VERSION "HNPBNYYYYYYYYYYYYYYYYYYYYYYYYYYYNNNNNNNNNN/4/%%/4/'%**4NNN///"

NS_ :

BS_:

BU_: ADL Aux_Device CANLogger CTU Central CentralMulti OffboardUDS Predecessor_Node RDC Radar SensorCANopen Simulator TEPM TIM TPMS iTEPM

BO_ 2566805936 ASC3_Tx_4 :8 CentralMulti
 SG_ VehicleLevelFrontLeft : 0|16@1+ (0.1,-3200) [0|65535] "mm" Vector__XXX
 SG_ VehicleLevelFrontRight : 16|16@1+ (0.1,-3200) [0|65535] "mm" Vector__XXX
 SG_ VehicleLevelRearLeft : 32|16@1+ (0.1,-3200) [0|65535] "mm" Vector__XXX
 SG_ VehicleLevelRearRight : 48|16@1+ (0.1,-3200) [0|65535] "mm" Vector__XXX

BO_ 2566805928 ASC3_Tx_5 :8 CentralMulti
 SG_ VehicleLevelFrontLeft : 0|16@1+ (0.1,-3200) [0|65535] "mm" Vector__XXX
 SG_ VehicleLevelFrontRight : 16|16@1+ (0.1,-3200) [0|65535] "mm" Vector__XXX
 SG_ VehicleLevelRearLeft : 32|16@1+ (0.1,-3200) [0|65535] "mm" Vector__XXX
 SG_ VehicleLevelRearRight : 48|16@1+ (0.1,-3200) [0|65535] "mm" Vector__XXX

BO_ 2566805920 ASC3_Tx_6 :8 CentralMulti
 SG_ VehicleLevelFrontLeft : 0|16@1+ (0.1,-3200) [0|65535] "mm" Vector__XXX
 SG_ VehicleLevelFrontRight : 16|16@1+ (0.1,-3200) [0|65535] "mm" Vector__XXX
 SG_ VehicleLevelRearLeft : 32|16@1+ (0.1,-3200) [0|65535] "mm" Vector__XXX
 SG_ VehicleLevelRearRight : 48|16@1+ (0.1,-3200) [0|65535] "mm" Vector__XXX

BO_ 2173691288 ASC3_Tx_7 :8 CentralMulti
 SG_ VehicleLevelFrontLeft : 0|16@1+ (0.1,-3200) [0|65535] "mm" Vector__XXX
 SG_ VehicleLevelFrontRight : 16|16@1+ (0.1,-3200) [0|65535] "mm" Vector__XXX
 SG_ VehicleLevelRearLeft : 32|16@1+ (0.1,-3200) [0|65535] "mm" Vector__XXX
 SG_ VehicleLevelRearRight : 48|16@1+ (0.1,-3200) [0|65535] "mm" Vector__XXX

BO_ 2566805904 ASC3_Tx_8 :8 CentralMulti
 SG_ VehicleLevelFrontLeft : 0|16@1+ (0.1,-3200) [0|65535] "mm" Vector__XXX
 SG_ VehicleLevelFrontRight : 16|16@1+ (0.1,-3200) [0|65535] "mm" Vector__XXX
 SG_ VehicleLevelRearLeft : 32|16@1+ (0.1,-3200) [0|65535] "mm" Vector__XXX
 SG_ VehicleLevelRearRight : 48|16@1+ (0.1,-3200) [0|65535] "mm" Vector__XXX

BO_ 2566805896 ASC3_Tx_9 :8 CentralMulti
 SG_ VehicleLevelFrontLeft : 0|16@1+ (0.1,-3200) [0|65535] "mm" Vector__XXX
 SG_ VehicleLevelFrontRight : 16|16@1+ (0.1,-3200) [0|65535] "mm" Vector__XXX
 SG_ VehicleLevelRearLeft : 32|16@1+ (0.1,-3200) [0|65535] "mm" Vector__XXX
 SG_ VehicleLevelRearRight : 48|16@1+ (0.1,-3200) [0|65535] "mm" Vector__XXX

BO_ 2566805888 ASC3_Tx_10 :8 CentralMulti
 SG_ VehicleLevelFrontLeft : 0|16@1+ (0.1,-3200) [0|65535] "mm" Vector__XXX
 SG_ VehicleLevelFrontRight : 16|16@1+ (0.1,-3200) [0|65535] "mm" Vector__XXX
 SG_ VehicleLevelRearLeft : 32|16@1+ (0.1,-3200) [0|65535] "mm" Vector__XXX
 SG_ VehicleLevelRearRight : 48|16@1+ (0.1,-3200) [0|65535] "mm" Vector__XXX

BO_ 2566813896 PGN65144_Tx :8 Central
 SG_ Tire_Press_Sw_Sta : 28|2@1+ (1,0) [0|3] "" Vector__XXX

BO_ 2566813888 PGN65144_Tx_2 :8 CentralMulti
 SG_ Tire_Press_Sw_Sta : 28|2@1+ (1,0) [0|3] "" Vector__XXX

BO_ 2566813880 PGN65144_Tx_3 :8 CentralMulti
 SG_ Tire_Press_Sw_Sta : 28|2@1+ (1,0) [0|3] "" Vector__XXX

BO_ 2566813872 PGN65144_Tx_4 :8 CentralMulti
 SG_ Tire_Press_Sw_Sta : 28|2@1+ (1,0) [0|3] "" Vector__XXX

BO_ 2566813864 PGN65144_Tx_5 :8 CentralMulti
 SG_ Tire_Press_Sw_Sta : 28|2@1+ (1,0) [0|3] "" Vector__XXX

BO_ 2566813856 PGN65144_Tx_6 :8 CentralMulti
 SG_ Tire_Press_Sw_Sta : 28|2@1+ (1,0) [0|3] "" Vector__XXX

BO_ 2566813848 PGN65144_Tx_7 :8 CentralMulti
 SG_ Tire_Press_Sw_Sta : 28|2@1+ (1,0) [0|3] "" Vector__XXX

BO_ 2566813840 PGN65144_Tx_8 :8 CentralMulti
 SG_ Tire_Press_Sw_Sta : 28|2@1+ (1,0) [0|3] "" Vector__XXX

BO_ 2566813832 PGN65144_Tx_9 :8 CentralMulti
 SG_ Tire_Press_Sw_Sta : 28|2@1+ (1,0) [0|3] "" Vector__XXX

BO_ 2566813824 PGN65144_Tx_10 :8 CentralMulti
 SG_ Tire_Press_Sw_Sta : 28|2@1+ (1,0) [0|3] "" Vector__XXX

BO_ 2566844872 PGN65265_Tx :8 Central
 SG_ ParkBrakeSwitch : 2|2@1+ (1,0) [0|3] "" Vector__XXX

BO_ 2566844864 PGN65265_Tx_2 :8 CentralMulti
 SG_ ParkBrakeSwitch : 2|2@1+ (1,0) [0|3] "" Vector__XXX

BO_ 2566844856 PGN65265_Tx_3 :8 CentralMulti
 SG_ ParkBrakeSwitch : 2|2@1+ (1,0) [0|3] "" Vector__XXX

BO_ 2566844848 PGN65265_Tx_4 :8 CentralMulti
 SG_ ParkBrakeSwitch : 2|2@1+ (1,0) [0|3] "" Vector__XXX

BO_ 2566844840 PGN65265_Tx_5 :8 CentralMulti
 SG_ ParkBrakeSwitch : 2|2@1+ (1,0) [0|3] "" Vector__XXX

BO_ 2566844832 PGN65265_Tx_6 :8 CentralMulti
 SG_ ParkBrakeSwitch : 2|2@1+ (1,0) [0|3] "" Vector__XXX

BO_ 2566844824 PGN65265_Tx_7 :8 CentralMulti
 SG_ ParkBrakeSwitch : 2|2@1+ (1,0) [0|3] "" Vector__XXX

BO_ 2566844816 PGN65265_Tx_8 :8 CentralMulti
 SG_ ParkBrakeSwitch : 2|2@1+ (1,0) [0|3] "" Vector__XXX

BO_ 2566844808 PGN65265_Tx_9 :8 CentralMulti
 SG_ ParkBrakeSwitch : 2|2@1+ (1,0) [0|3] "" Vector__XXX

BO_ 2566844800 PGN65265_Tx_10 :8 CentralMulti
 SG_ ParkBrakeSwitch : 2|2@1+ (1,0) [0|3] "" Vector__XXX

BO_ 2566848712 PGN65280_Tx :8 Central
 SG_ Overload : 0|2@1+ (1,0) [0|3] "" Vector__XXX
 SG_ TracHelp : 2|2@1+ (1,0) [0|3] "" Vector__XXX
 SG_ P1_Sys : 8|8@1+ (80,0) [0|255] "mbar" Vector__XXX
 SG_ P4_Dem : 16|8@1+ (80,0) [0|255] "mbar" Vector__XXX
 SG_ EBS_Press : 24|8@1+ (80,0) [0|255] "mbar" Vector__XXX
 SG_ AvgBrPressMain : 32|8@1+ (80,0) [0|255] "mbar" Vector__XXX
 SG_ AvgBrPressSteer : 40|8@1+ (80,0) [0|255] "mbar" Vector__XXX
 SG_ LoadPress : 48|8@1+ (80,0) [0|255] "mbar" Vector__XXX

BO_ 2566848704 PGN65280_Tx_2 :8 CentralMulti
 SG_ Overload : 0|2@1+ (1,0) [0|3] "" Vector__XXX
 SG_ TracHelp : 2|2@1+ (1,0) [0|3] "" Vector__XXX
 SG_ P1_Sys : 8|8@1+ (80,0) [0|255] "mbar" Vector__XXX
 SG_ P4_Dem : 16|8@1+ (80,0) [0|255] "mbar" Vector__XXX
 SG_ EBS_Press : 24|8@1+ (80,0) [0|255] "mbar" Vector__XXX
 SG_ AvgBrPressMain : 32|8@1+ (80,0) [0|255] "mbar" Vector__XXX
 SG_ AvgBrPressSteer : 40|8@1+ (80,0) [0|255] "mbar" Vector__XXX
 SG_ LoadPress : 48|8@1+ (80,0) [0|255] "mbar" Vector__XXX

BO_ 2566848696 PGN65280_Tx_3 :8 CentralMulti
 SG_ Overload : 0|2@1+ (1,0) [0|3] "" Vector__XXX
 SG_ TracHelp : 2|2@1+ (1,0) [0|3] "" Vector__XXX
 SG_ P1_Sys : 8|8@1+ (80,0) [0|255] "mbar" Vector__XXX
 SG_ P4_Dem : 16|8@1+ (80,0) [0|255] "mbar" Vector__XXX
 SG_ EBS_Press : 24|8@1+ (80,0) [0|255] "mbar" Vector__XXX
 SG_ AvgBrPressMain : 32|8@1+ (80,0) [0|255] "mbar" Vector__XXX
 SG_ AvgBrPressSteer : 40|8@1+ (80,0) [0|255] "mbar" Vector__XXX
 SG_ LoadPress : 48|8@1+ (80,0) [0|255] "mbar" Vector__XXX

BO_ 2566848688 PGN65280_Tx_4 :8 CentralMulti
 SG_ Overload : 0|2@1+ (1,0) [0|3] "" Vector__XXX
 SG_ TracHelp : 2|2@1+ (1,0) [0|3] "" Vector__XXX
 SG_ P1_Sys : 8|8@1+ (80,0) [0|255] "mbar" Vector__XXX
 SG_ P4_Dem : 16|8@1+ (80,0) [0|255] "mbar" Vector__XXX
 SG_ EBS_Press : 24|8@1+ (80,0) [0|255] "mbar" Vector__XXX
 SG_ AvgBrPressMain : 32|8@1+ (80,0) [0|255] "mbar" Vector__XXX
 SG_ AvgBrPressSteer : 40|8@1+ (80,0) [0|255] "mbar" Vector__XXX
 SG_ LoadPress : 48|8@1+ (80,0) [0|255] "mbar" Vector__XXX

BO_ 2566848680 PGN65280_Tx_5 :8 CentralMulti
 SG_ Overload : 0|2@1+ (1,0) [0|3] "" Vector__XXX
 SG_ TracHelp : 2|2@1+ (1,0) [0|3] "" Vector__XXX
 SG_ P1_Sys : 8|8@1+ (80,0) [0|255] "mbar" Vector__XXX
 SG_ P4_Dem : 16|8@1+ (80,0) [0|255] "mbar" Vector__XXX
 SG_ EBS_Press : 24|8@1+ (80,0) [0|255] "mbar" Vector__XXX
 SG_ AvgBrPressMain : 32|8@1+ (80,0) [0|255] "mbar" Vector__XXX
 SG_ AvgBrPressSteer : 40|8@1+ (80,0) [0|255] "mbar" Vector__XXX
 SG_ LoadPress : 48|8@1+ (80,0) [0|255] "mbar" Vector__XXX

BO_ 2566848672 PGN65280_Tx_6 :8 CentralMulti
 SG_ Overload : 0|2@1+ (1,0) [0|3] "" Vector__XXX
 SG_ TracHelp : 2|2@1+ (1,0) [0|3] "" Vector__XXX
 SG_ P1_Sys : 8|8@1+ (80,0) [0|255] "mbar" Vector__XXX
 SG_ P4_Dem : 16|8@1+ (80,0) [0|255] "mbar" Vector__XXX
 SG_ EBS_Press : 24|8@1+ (80,0) [0|255] "mbar" Vector__XXX
 SG_ AvgBrPressMain : 32|8@1+ (80,0) [0|255] "mbar" Vector__XXX
 SG_ AvgBrPressSteer : 40|8@1+ (80,0) [0|255] "mbar" Vector__XXX
 SG_ LoadPress : 48|8@1+ (80,0) [0|255] "mbar" Vector__XXX

BO_ 2566848664 PGN65280_Tx_7 :8 CentralMulti
 SG_ Overload : 0|2@1+ (1,0) [0|3] "" Vector__XXX
 SG_ TracHelp : 2|2@1+ (1,0) [0|3] "" Vector__XXX
 SG_ P1_Sys : 8|8@1+ (80,0) [0|255] "mbar" Vector__XXX
 SG_ P4_Dem : 16|8@1+ (80,0) [0|255] "mbar" Vector__XXX
 SG_ EBS_Press : 24|8@1+ (80,0) [0|255] "mbar" Vector__XXX
 SG_ AvgBrPressMain : 32|8@1+ (80,0) [0|255] "mbar" Vector__XXX
 SG_ AvgBrPressSteer : 40|8@1+ (80,0) [0|255] "mbar" Vector__XXX
 SG_ LoadPress : 48|8@1+ (80,0) [0|255] "mbar" Vector__XXX

BO_ 2566848656 PGN65280_Tx_8 :8 CentralMulti
 SG_ Overload : 0|2@1+ (1,0) [0|3] "" Vector__XXX
 SG_ TracHelp : 2|2@1+ (1,0) [0|3] "" Vector__XXX
 SG_ P1_Sys : 8|8@1+ (80,0) [0|255] "mbar" Vector__XXX
 SG_ P4_Dem : 16|8@1+ (80,0) [0|255] "mbar" Vector__XXX
 SG_ EBS_Press : 24|8@1+ (80,0) [0|255] "mbar" Vector__XXX
 SG_ AvgBrPressMain : 32|8@1+ (80,0) [0|255] "mbar" Vector__XXX
 SG_ AvgBrPressSteer : 40|8@1+ (80,0) [0|255] "mbar" Vector__XXX
 SG_ LoadPress : 48|8@1+ (80,0) [0|255] "mbar" Vector__XXX

BO_ 2566848648 PGN65280_Tx_9 :8 CentralMulti
 SG_ Overload : 0|2@1+ (1,0) [0|3] "" Vector__XXX
 SG_ TracHelp : 2|2@1+ (1,0) [0|3] "" Vector__XXX
 SG_ P1_Sys : 8|8@1+ (80,0) [0|255] "mbar" Vector__XXX
 SG_ P4_Dem : 16|8@1+ (80,0) [0|255] "mbar" Vector__XXX
 SG_ EBS_Press : 24|8@1+ (80,0) [0|255] "mbar" Vector__XXX
 SG_ AvgBrPressMain : 32|8@1+ (80,0) [0|255] "mbar" Vector__XXX
 SG_ AvgBrPressSteer : 40|8@1+ (80,0) [0|255] "mbar" Vector__XXX
 SG_ LoadPress : 48|8@1+ (80,0) [0|255] "mbar" Vector__XXX

BO_ 2566848640 PGN65280_Tx_10 :8 CentralMulti
 SG_ Overload : 0|2@1+ (1,0) [0|3] "" Vector__XXX
 SG_ TracHelp : 2|2@1+ (1,0) [0|3] "" Vector__XXX
 SG_ P1_Sys : 8|8@1+ (80,0) [0|255] "mbar" Vector__XXX
 SG_ P4_Dem : 16|8@1+ (80,0) [0|255] "mbar" Vector__XXX
 SG_ EBS_Press : 24|8@1+ (80,0) [0|255] "mbar" Vector__XXX
 SG_ AvgBrPressMain : 32|8@1+ (80,0) [0|255] "mbar" Vector__XXX
 SG_ AvgBrPressSteer : 40|8@1+ (80,0) [0|255] "mbar" Vector__XXX
 SG_ LoadPress : 48|8@1+ (80,0) [0|255] "mbar" Vector__XXX

BO_ 2566849224 PGN65282_Tx :8 Central
 SG_ StBkpPSup : 0|2@1+ (1,0) [0|3] "" Vector__XXX
 SG_ StISO7638PSup : 2|2@1+ (1,0) [0|3] "" Vector__XXX
 SG_ YellowPress : 24|8@1+ (10,0) [0|255] "kPa" Vector__XXX
 SG_ PCANDem : 32|8@1+ (10,0) [0|255] "kPa" Vector__XXX
 SG_ P21 : 40|8@1+ (10,0) [0|255] "kPa" Vector__XXX
 SG_ P22 : 48|8@1+ (10,0) [0|255] "kPa" Vector__XXX
 SG_ P2P23 : 56|8@1+ (10,0) [0|255] "kPa" Vector__XXX

BO_ 2566849216 PGN65282_Tx_2 :8 CentralMulti
 SG_ StBkpPSup : 0|2@1+ (1,0) [0|3] "" Vector__XXX
 SG_ StISO7638PSup : 2|2@1+ (1,0) [0|3] "" Vector__XXX
 SG_ YellowPress : 24|8@1+ (10,0) [0|255] "kPa" Vector__XXX
 SG_ PCANDem : 32|8@1+ (10,0) [0|255] "kPa" Vector__XXX
 SG_ P21 : 40|8@1+ (10,0) [0|255] "kPa" Vector__XXX
 SG_ P22 : 48|8@1+ (10,0) [0|255] "kPa" Vector__XXX
 SG_ P2P23 : 56|8@1+ (10,0) [0|255] "kPa" Vector__XXX

BO_ 2566849208 PGN65282_Tx_3 :8 CentralMulti
 SG_ StBkpPSup : 0|2@1+ (1,0) [0|3] "" Vector__XXX
 SG_ StISO7638PSup : 2|2@1+ (1,0) [0|3] "" Vector__XXX
 SG_ YellowPress : 24|8@1+ (10,0) [0|255] "kPa" Vector__XXX
 SG_ PCANDem : 32|8@1+ (10,0) [0|255] "kPa" Vector__XXX
 SG_ P21 : 40|8@1+ (10,0) [0|255] "kPa" Vector__XXX
 SG_ P22 : 48|8@1+ (10,0) [0|255] "kPa" Vector__XXX
 SG_ P2P23 : 56|8@1+ (10,0) [0|255] "kPa" Vector__XXX

BO_ 2566849200 PGN65282_Tx_4 :8 CentralMulti
 SG_ StBkpPSup : 0|2@1+ (1,0) [0|3] "" Vector__XXX
 SG_ StISO7638PSup : 2|2@1+ (1,0) [0|3] "" Vector__XXX
 SG_ YellowPress : 24|8@1+ (10,0) [0|255] "kPa" Vector__XXX
 SG_ PCANDem : 32|8@1+ (10,0) [0|255] "kPa" Vector__XXX
 SG_ P21 : 40|8@1+ (10,0) [0|255] "kPa" Vector__XXX
 SG_ P22 : 48|8@1+ (10,0) [0|255] "kPa" Vector__XXX
 SG_ P2P23 : 56|8@1+ (10,0) [0|255] "kPa" Vector__XXX

BO_ 2566849192 PGN65282_Tx_5 :8 CentralMulti
 SG_ StBkpPSup : 0|2@1+ (1,0) [0|3] "" Vector__XXX
 SG_ StISO7638PSup : 2|2@1+ (1,0) [0|3] "" Vector__XXX
 SG_ YellowPress : 24|8@1+ (10,0) [0|255] "kPa" Vector__XXX
 SG_ PCANDem : 32|8@1+ (10,0) [0|255] "kPa" Vector__XXX
 SG_ P21 : 40|8@1+ (10,0) [0|255] "kPa" Vector__XXX
 SG_ P22 : 48|8@1+ (10,0) [0|255] "kPa" Vector__XXX
 SG_ P2P23 : 56|8@1+ (10,0) [0|255] "kPa" Vector__XXX

BO_ 2566849184 PGN65282_Tx_6 :8 CentralMulti
 SG_ StBkpPSup : 0|2@1+ (1,0) [0|3] "" Vector__XXX
 SG_ StISO7638PSup : 2|2@1+ (1,0) [0|3] "" Vector__XXX
 SG_ YellowPress : 24|8@1+ (10,0) [0|255] "kPa" Vector__XXX
 SG_ PCANDem : 32|8@1+ (10,0) [0|255] "kPa" Vector__XXX
 SG_ P21 : 40|8@1+ (10,0) [0|255] "kPa" Vector__XXX
 SG_ P22 : 48|8@1+ (10,0) [0|255] "kPa" Vector__XXX
 SG_ P2P23 : 56|8@1+ (10,0) [0|255] "kPa" Vector__XXX

BO_ 2566849176 PGN65282_Tx_7 :8 CentralMulti
 SG_ StBkpPSup : 0|2@1+ (1,0) [0|3] "" Vector__XXX
 SG_ StISO7638PSup : 2|2@1+ (1,0) [0|3] "" Vector__XXX
 SG_ YellowPress : 24|8@1+ (10,0) [0|255] "kPa" Vector__XXX
 SG_ PCANDem : 32|8@1+ (10,0) [0|255] "kPa" Vector__XXX
 SG_ P21 : 40|8@1+ (10,0) [0|255] "kPa" Vector__XXX
 SG_ P22 : 48|8@1+ (10,0) [0|255] "kPa" Vector__XXX
 SG_ P2P23 : 56|8@1+ (10,0) [0|255] "kPa" Vector__XXX

BO_ 2566849168 PGN65282_Tx_8 :8 CentralMulti
 SG_ StBkpPSup : 0|2@1+ (1,0) [0|3] "" Vector__XXX
 SG_ StISO7638PSup : 2|2@1+ (1,0) [0|3] "" Vector__XXX
 SG_ YellowPress : 24|8@1+ (10,0) [0|255] "kPa" Vector__XXX
 SG_ PCANDem : 32|8@1+ (10,0) [0|255] "kPa" Vector__XXX
 SG_ P21 : 40|8@1+ (10,0) [0|255] "kPa" Vector__XXX
 SG_ P22 : 48|8@1+ (10,0) [0|255] "kPa" Vector__XXX
 SG_ P2P23 : 56|8@1+ (10,0) [0|255] "kPa" Vector__XXX

BO_ 2566849160 PGN65282_Tx_9 :8 CentralMulti
 SG_ StBkpPSup : 0|2@1+ (1,0) [0|3] "" Vector__XXX
 SG_ StISO7638PSup : 2|2@1+ (1,0) [0|3] "" Vector__XXX
 SG_ YellowPress : 24|8@1+ (10,0) [0|255] "kPa" Vector__XXX
 SG_ PCANDem : 32|8@1+ (10,0) [0|255] "kPa" Vector__XXX
 SG_ P21 : 40|8@1+ (10,0) [0|255] "kPa" Vector__XXX
 SG_ P22 : 48|8@1+ (10,0) [0|255] "kPa" Vector__XXX
 SG_ P2P23 : 56|8@1+ (10,0) [0|255] "kPa" Vector__XXX

BO_ 2566849152 PGN65282_Tx_10 :8 CentralMulti
 SG_ StBkpPSup : 0|2@1+ (1,0) [0|3] "" Vector__XXX
 SG_ StISO7638PSup : 2|2@1+ (1,0) [0|3] "" Vector__XXX
 SG_ YellowPress : 24|8@1+ (10,0) [0|255] "kPa" Vector__XXX
 SG_ PCANDem : 32|8@1+ (10,0) [0|255] "kPa" Vector__XXX
 SG_ P21 : 40|8@1+ (10,0) [0|255] "kPa" Vector__XXX
 SG_ P22 : 48|8@1+ (10,0) [0|255] "kPa" Vector__XXX
 SG_ P2P23 : 56|8@1+ (10,0) [0|255] "kPa" Vector__XXX

BO_ 2566849480 PGN65283_Tx :8 Central
 SG_ TrlInfInd : 0|8@1+ (1,0) [0|255] "" Vector__XXX
 SG_ TrlInfDat : 8|8@1+ (1,0) [0|255] "" Vector__XXX
 SG_ Odometer : 16|32@1+ (5,0) [0|4294967295] "m" Vector__XXX
 SG_ ConDevPermTr : 48|2@1+ (1,0) [0|3] "" Vector__XXX

BO_ 2566849472 PGN65283_Tx_2 :8 CentralMulti
 SG_ TrlInfInd : 0|8@1+ (1,0) [0|255] "" Vector__XXX
 SG_ TrlInfDat : 8|8@1+ (1,0) [0|255] "" Vector__XXX
 SG_ Odometer : 16|32@1+ (5,0) [0|4294967295] "m" Vector__XXX
 SG_ ConDevPermTr : 48|2@1+ (1,0) [0|3] "" Vector__XXX

BO_ 2566849464 PGN65283_Tx_3 :8 CentralMulti
 SG_ TrlInfInd : 0|8@1+ (1,0) [0|255] "" Vector__XXX
 SG_ TrlInfDat : 8|8@1+ (1,0) [0|255] "" Vector__XXX
 SG_ Odometer : 16|32@1+ (5,0) [0|4294967295] "m" Vector__XXX
 SG_ ConDevPermTr : 48|2@1+ (1,0) [0|3] "" Vector__XXX

BO_ 2566849456 PGN65283_Tx_4 :8 CentralMulti
 SG_ TrlInfInd : 0|8@1+ (1,0) [0|255] "" Vector__XXX
 SG_ TrlInfDat : 8|8@1+ (1,0) [0|255] "" Vector__XXX
 SG_ Odometer : 16|32@1+ (5,0) [0|4294967295] "m" Vector__XXX
 SG_ ConDevPermTr : 48|2@1+ (1,0) [0|3] "" Vector__XXX

BO_ 2566849448 PGN65283_Tx_5 :8 CentralMulti
 SG_ TrlInfInd : 0|8@1+ (1,0) [0|255] "" Vector__XXX
 SG_ TrlInfDat : 8|8@1+ (1,0) [0|255] "" Vector__XXX
 SG_ Odometer : 16|32@1+ (5,0) [0|4294967295] "m" Vector__XXX
 SG_ ConDevPermTr : 48|2@1+ (1,0) [0|3] "" Vector__XXX

BO_ 2566849440 PGN65283_Tx_6 :8 CentralMulti
 SG_ TrlInfInd : 0|8@1+ (1,0) [0|255] "" Vector__XXX
 SG_ TrlInfDat : 8|8@1+ (1,0) [0|255] "" Vector__XXX
 SG_ Odometer : 16|32@1+ (5,0) [0|4294967295] "m" Vector__XXX
 SG_ ConDevPermTr : 48|2@1+ (1,0) [0|3] "" Vector__XXX

BO_ 2566849432 PGN65283_Tx_7 :8 CentralMulti
 SG_ TrlInfInd : 0|8@1+ (1,0) [0|255] "" Vector__XXX
 SG_ TrlInfDat : 8|8@1+ (1,0) [0|255] "" Vector__XXX
 SG_ Odometer : 16|32@1+ (5,0) [0|4294967295] "m" Vector__XXX
 SG_ ConDevPermTr : 48|2@1+ (1,0) [0|3] "" Vector__XXX

BO_ 2566849424 PGN65283_Tx_8 :8 CentralMulti
 SG_ TrlInfInd : 0|8@1+ (1,0) [0|255] "" Vector__XXX
 SG_ TrlInfDat : 8|8@1+ (1,0) [0|255] "" Vector__XXX
 SG_ Odometer : 16|32@1+ (5,0) [0|4294967295] "m" Vector__XXX
 SG_ ConDevPermTr : 48|2@1+ (1,0) [0|3] "" Vector__XXX

BO_ 2566849416 PGN65283_Tx_9 :8 CentralMulti
 SG_ TrlInfInd : 0|8@1+ (1,0) [0|255] "" Vector__XXX
 SG_ TrlInfDat : 8|8@1+ (1,0) [0|255] "" Vector__XXX
 SG_ Odometer : 16|32@1+ (5,0) [0|4294967295] "m" Vector__XXX
 SG_ ConDevPermTr : 48|2@1+ (1,0) [0|3] "" Vector__XXX

BO_ 2566849408 PGN65283_Tx_10 :8 CentralMulti
 SG_ TrlInfInd : 0|8@1+ (1,0) [0|255] "" Vector__XXX
 SG_ TrlInfDat : 8|8@1+ (1,0) [0|255] "" Vector__XXX
 SG_ Odometer : 16|32@1+ (5,0) [0|4294967295] "m" Vector__XXX
 SG_ ConDevPermTr : 48|2@1+ (1,0) [0|3] "" Vector__XXX

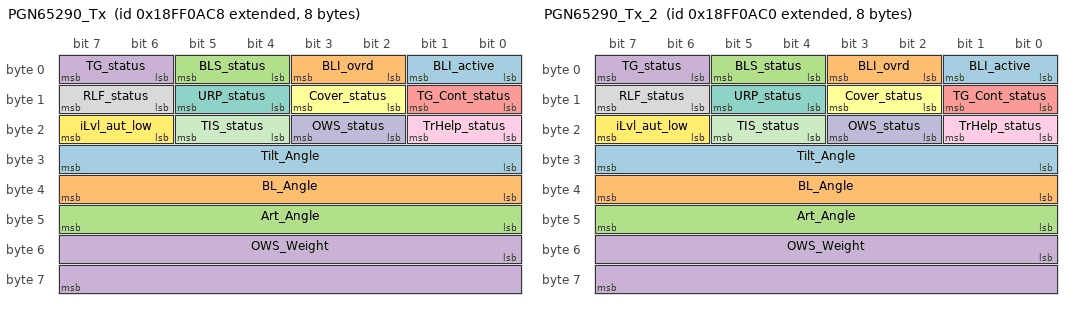
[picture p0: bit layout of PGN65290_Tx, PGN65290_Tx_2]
BO_ 2566851272 PGN65290_Tx :8 Central
 SG_ BLI_active : 0|2@1+ (1,0) [0|3] "" Vector__XXX
 SG_ BLI_ovrd : 2|2@1+ (1,0) [0|3] "" Vector__XXX
 SG_ BLS_status : 4|2@1+ (1,0) [0|3] "" Vector__XXX
 SG_ TG_status : 6|2@1+ (1,0) [0|3] "" Vector__XXX
 SG_ TG_Cont_status : 8|2@1+ (1,0) [0|3] "" Vector__XXX
 SG_ Cover_status : 10|2@1+ (1,0) [0|3] "" Vector__XXX
 SG_ URP_status : 12|2@1+ (1,0) [0|3] "" Vector__XXX
 SG_ RLF_status : 14|2@1+ (1,0) [0|3] "" Vector__XXX
 SG_ TrHelp_status : 16|2@1+ (1,0) [0|3] "" Vector__XXX
 SG_ OWS_status : 18|2@1+ (1,0) [0|3] "" Vector__XXX
 SG_ TIS_status : 20|2@1+ (1,0) [0|3] "" Vector__XXX
 SG_ iLvl_aut_low : 22|2@1+ (1,0) [0|3] "" Vector__XXX
 SG_ Tilt_Angle : 24|8@1+ (1,-125) [0|255] "deg" Vector__XXX
 SG_ BL_Angle : 32|8@1+ (1,-125) [0|255] "deg" Vector__XXX
 SG_ Art_Angle : 40|8@1+ (1,-125) [0|255] "deg" Vector__XXX
 SG_ OWS_Weight : 48|16@1+ (10,0) [0|65535] "kg" Vector__XXX

BO_ 2566851264 PGN65290_Tx_2 :8 CentralMulti
 SG_ BLI_active : 0|2@1+ (1,0) [0|3] "" Vector__XXX
 SG_ BLI_ovrd : 2|2@1+ (1,0) [0|3] "" Vector__XXX
 SG_ BLS_status : 4|2@1+ (1,0) [0|3] "" Vector__XXX
 SG_ TG_status : 6|2@1+ (1,0) [0|3] "" Vector__XXX
 SG_ TG_Cont_status : 8|2@1+ (1,0) [0|3] "" Vector__XXX
 SG_ Cover_status : 10|2@1+ (1,0) [0|3] "" Vector__XXX
 SG_ URP_status : 12|2@1+ (1,0) [0|3] "" Vector__XXX
 SG_ RLF_status : 14|2@1+ (1,0) [0|3] "" Vector__XXX
 SG_ TrHelp_status : 16|2@1+ (1,0) [0|3] "" Vector__XXX
 SG_ OWS_status : 18|2@1+ (1,0) [0|3] "" Vector__XXX
 SG_ TIS_status : 20|2@1+ (1,0) [0|3] "" Vector__XXX
 SG_ iLvl_aut_low : 22|2@1+ (1,0) [0|3] "" Vector__XXX
 SG_ Tilt_Angle : 24|8@1+ (1,-125) [0|255] "deg" Vector__XXX
 SG_ BL_Angle : 32|8@1+ (1,-125) [0|255] "deg" Vector__XXX
 SG_ Art_Angle : 40|8@1+ (1,-125) [0|255] "deg" Vector__XXX
 SG_ OWS_Weight : 48|16@1+ (10,0) [0|65535] "kg" Vector__XXX

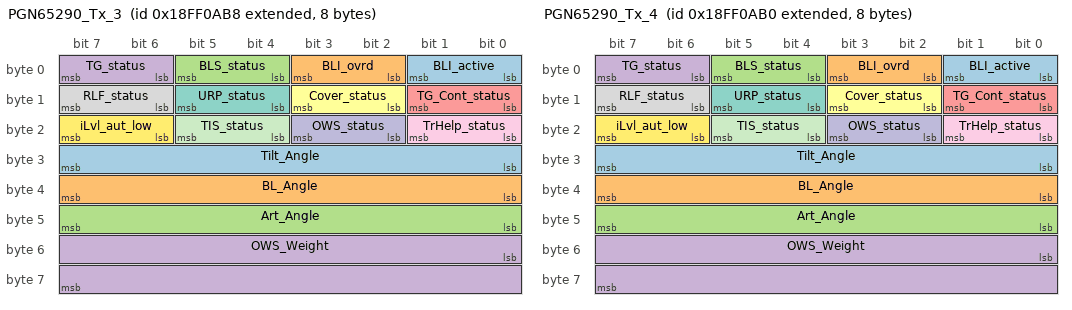
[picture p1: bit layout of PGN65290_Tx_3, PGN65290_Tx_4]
BO_ 2566851256 PGN65290_Tx_3 :8 CentralMulti
 SG_ BLI_active : 0|2@1+ (1,0) [0|3] "" Vector__XXX
 SG_ BLI_ovrd : 2|2@1+ (1,0) [0|3] "" Vector__XXX
 SG_ BLS_status : 4|2@1+ (1,0) [0|3] "" Vector__XXX
 SG_ TG_status : 6|2@1+ (1,0) [0|3] "" Vector__XXX
 SG_ TG_Cont_status : 8|2@1+ (1,0) [0|3] "" Vector__XXX
 SG_ Cover_status : 10|2@1+ (1,0) [0|3] "" Vector__XXX
 SG_ URP_status : 12|2@1+ (1,0) [0|3] "" Vector__XXX
 SG_ RLF_status : 14|2@1+ (1,0) [0|3] "" Vector__XXX
 SG_ TrHelp_status : 16|2@1+ (1,0) [0|3] "" Vector__XXX
 SG_ OWS_status : 18|2@1+ (1,0) [0|3] "" Vector__XXX
 SG_ TIS_status : 20|2@1+ (1,0) [0|3] "" Vector__XXX
 SG_ iLvl_aut_low : 22|2@1+ (1,0) [0|3] "" Vector__XXX
 SG_ Tilt_Angle : 24|8@1+ (1,-125) [0|255] "deg" Vector__XXX
 SG_ BL_Angle : 32|8@1+ (1,-125) [0|255] "deg" Vector__XXX
 SG_ Art_Angle : 40|8@1+ (1,-125) [0|255] "deg" Vector__XXX
 SG_ OWS_Weight : 48|16@1+ (10,0) [0|65535] "kg" Vector__XXX

BO_ 2566851248 PGN65290_Tx_4 :8 CentralMulti
 SG_ BLI_active : 0|2@1+ (1,0) [0|3] "" Vector__XXX
 SG_ BLI_ovrd : 2|2@1+ (1,0) [0|3] "" Vector__XXX
 SG_ BLS_status : 4|2@1+ (1,0) [0|3] "" Vector__XXX
 SG_ TG_status : 6|2@1+ (1,0) [0|3] "" Vector__XXX
 SG_ TG_Cont_status : 8|2@1+ (1,0) [0|3] "" Vector__XXX
 SG_ Cover_status : 10|2@1+ (1,0) [0|3] "" Vector__XXX
 SG_ URP_status : 12|2@1+ (1,0) [0|3] "" Vector__XXX
 SG_ RLF_status : 14|2@1+ (1,0) [0|3] "" Vector__XXX
 SG_ TrHelp_status : 16|2@1+ (1,0) [0|3] "" Vector__XXX
 SG_ OWS_status : 18|2@1+ (1,0) [0|3] "" Vector__XXX
 SG_ TIS_status : 20|2@1+ (1,0) [0|3] "" Vector__XXX
 SG_ iLvl_aut_low : 22|2@1+ (1,0) [0|3] "" Vector__XXX
 SG_ Tilt_Angle : 24|8@1+ (1,-125) [0|255] "deg" Vector__XXX
 SG_ BL_Angle : 32|8@1+ (1,-125) [0|255] "deg" Vector__XXX
 SG_ Art_Angle : 40|8@1+ (1,-125) [0|255] "deg" Vector__XXX
 SG_ OWS_Weight : 48|16@1+ (10,0) [0|65535] "kg" Vector__XXX

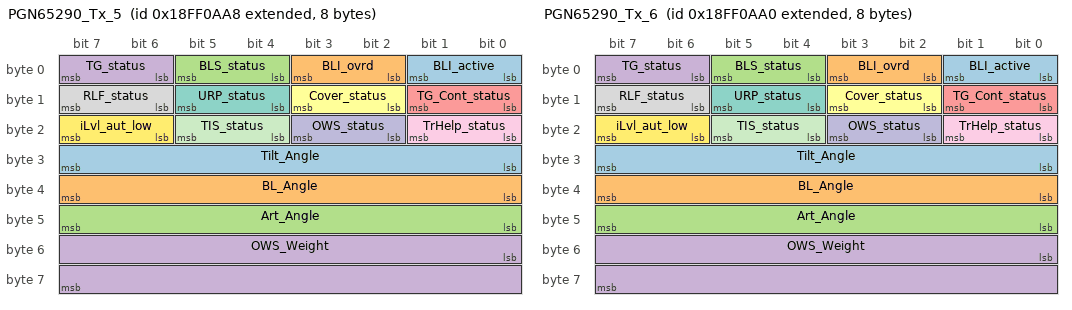
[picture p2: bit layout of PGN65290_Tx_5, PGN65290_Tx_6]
BO_ 2566851240 PGN65290_Tx_5 :8 CentralMulti
 SG_ BLI_active : 0|2@1+ (1,0) [0|3] "" Vector__XXX
 SG_ BLI_ovrd : 2|2@1+ (1,0) [0|3] "" Vector__XXX
 SG_ BLS_status : 4|2@1+ (1,0) [0|3] "" Vector__XXX
 SG_ TG_status : 6|2@1+ (1,0) [0|3] "" Vector__XXX
 SG_ TG_Cont_status : 8|2@1+ (1,0) [0|3] "" Vector__XXX
 SG_ Cover_status : 10|2@1+ (1,0) [0|3] "" Vector__XXX
 SG_ URP_status : 12|2@1+ (1,0) [0|3] "" Vector__XXX
 SG_ RLF_status : 14|2@1+ (1,0) [0|3] "" Vector__XXX
 SG_ TrHelp_status : 16|2@1+ (1,0) [0|3] "" Vector__XXX
 SG_ OWS_status : 18|2@1+ (1,0) [0|3] "" Vector__XXX
 SG_ TIS_status : 20|2@1+ (1,0) [0|3] "" Vector__XXX
 SG_ iLvl_aut_low : 22|2@1+ (1,0) [0|3] "" Vector__XXX
 SG_ Tilt_Angle : 24|8@1+ (1,-125) [0|255] "deg" Vector__XXX
 SG_ BL_Angle : 32|8@1+ (1,-125) [0|255] "deg" Vector__XXX
 SG_ Art_Angle : 40|8@1+ (1,-125) [0|255] "deg" Vector__XXX
 SG_ OWS_Weight : 48|16@1+ (10,0) [0|65535] "kg" Vector__XXX

BO_ 2566851232 PGN65290_Tx_6 :8 CentralMulti
 SG_ BLI_active : 0|2@1+ (1,0) [0|3] "" Vector__XXX
 SG_ BLI_ovrd : 2|2@1+ (1,0) [0|3] "" Vector__XXX
 SG_ BLS_status : 4|2@1+ (1,0) [0|3] "" Vector__XXX
 SG_ TG_status : 6|2@1+ (1,0) [0|3] "" Vector__XXX
 SG_ TG_Cont_status : 8|2@1+ (1,0) [0|3] "" Vector__XXX
 SG_ Cover_status : 10|2@1+ (1,0) [0|3] "" Vector__XXX
 SG_ URP_status : 12|2@1+ (1,0) [0|3] "" Vector__XXX
 SG_ RLF_status : 14|2@1+ (1,0) [0|3] "" Vector__XXX
 SG_ TrHelp_status : 16|2@1+ (1,0) [0|3] "" Vector__XXX
 SG_ OWS_status : 18|2@1+ (1,0) [0|3] "" Vector__XXX
 SG_ TIS_status : 20|2@1+ (1,0) [0|3] "" Vector__XXX
 SG_ iLvl_aut_low : 22|2@1+ (1,0) [0|3] "" Vector__XXX
 SG_ Tilt_Angle : 24|8@1+ (1,-125) [0|255] "deg" Vector__XXX
 SG_ BL_Angle : 32|8@1+ (1,-125) [0|255] "deg" Vector__XXX
 SG_ Art_Angle : 40|8@1+ (1,-125) [0|255] "deg" Vector__XXX
 SG_ OWS_Weight : 48|16@1+ (10,0) [0|65535] "kg" Vector__XXX

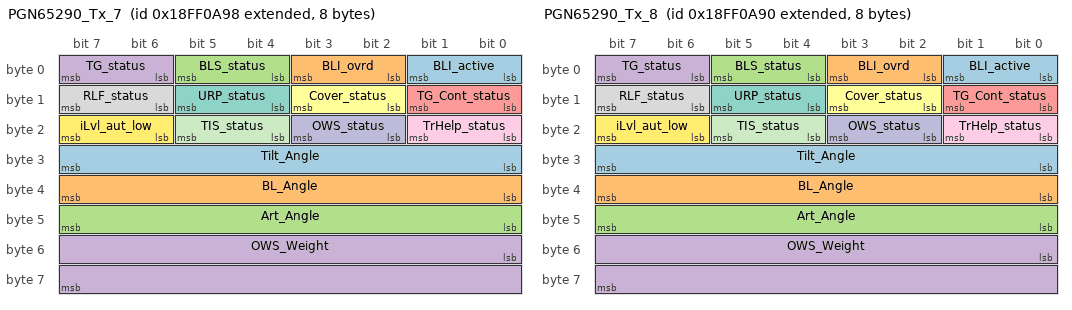
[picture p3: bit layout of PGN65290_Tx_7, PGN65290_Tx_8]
BO_ 2566851224 PGN65290_Tx_7 :8 CentralMulti
 SG_ BLI_active : 0|2@1+ (1,0) [0|3] "" Vector__XXX
 SG_ BLI_ovrd : 2|2@1+ (1,0) [0|3] "" Vector__XXX
 SG_ BLS_status : 4|2@1+ (1,0) [0|3] "" Vector__XXX
 SG_ TG_status : 6|2@1+ (1,0) [0|3] "" Vector__XXX
 SG_ TG_Cont_status : 8|2@1+ (1,0) [0|3] "" Vector__XXX
 SG_ Cover_status : 10|2@1+ (1,0) [0|3] "" Vector__XXX
 SG_ URP_status : 12|2@1+ (1,0) [0|3] "" Vector__XXX
 SG_ RLF_status : 14|2@1+ (1,0) [0|3] "" Vector__XXX
 SG_ TrHelp_status : 16|2@1+ (1,0) [0|3] "" Vector__XXX
 SG_ OWS_status : 18|2@1+ (1,0) [0|3] "" Vector__XXX
 SG_ TIS_status : 20|2@1+ (1,0) [0|3] "" Vector__XXX
 SG_ iLvl_aut_low : 22|2@1+ (1,0) [0|3] "" Vector__XXX
 SG_ Tilt_Angle : 24|8@1+ (1,-125) [0|255] "deg" Vector__XXX
 SG_ BL_Angle : 32|8@1+ (1,-125) [0|255] "deg" Vector__XXX
 SG_ Art_Angle : 40|8@1+ (1,-125) [0|255] "deg" Vector__XXX
 SG_ OWS_Weight : 48|16@1+ (10,0) [0|65535] "kg" Vector__XXX

BO_ 2566851216 PGN65290_Tx_8 :8 CentralMulti
 SG_ BLI_active : 0|2@1+ (1,0) [0|3] "" Vector__XXX
 SG_ BLI_ovrd : 2|2@1+ (1,0) [0|3] "" Vector__XXX
 SG_ BLS_status : 4|2@1+ (1,0) [0|3] "" Vector__XXX
 SG_ TG_status : 6|2@1+ (1,0) [0|3] "" Vector__XXX
 SG_ TG_Cont_status : 8|2@1+ (1,0) [0|3] "" Vector__XXX
 SG_ Cover_status : 10|2@1+ (1,0) [0|3] "" Vector__XXX
 SG_ URP_status : 12|2@1+ (1,0) [0|3] "" Vector__XXX
 SG_ RLF_status : 14|2@1+ (1,0) [0|3] "" Vector__XXX
 SG_ TrHelp_status : 16|2@1+ (1,0) [0|3] "" Vector__XXX
 SG_ OWS_status : 18|2@1+ (1,0) [0|3] "" Vector__XXX
 SG_ TIS_status : 20|2@1+ (1,0) [0|3] "" Vector__XXX
 SG_ iLvl_aut_low : 22|2@1+ (1,0) [0|3] "" Vector__XXX
 SG_ Tilt_Angle : 24|8@1+ (1,-125) [0|255] "deg" Vector__XXX
 SG_ BL_Angle : 32|8@1+ (1,-125) [0|255] "deg" Vector__XXX
 SG_ Art_Angle : 40|8@1+ (1,-125) [0|255] "deg" Vector__XXX
 SG_ OWS_Weight : 48|16@1+ (10,0) [0|65535] "kg" Vector__XXX

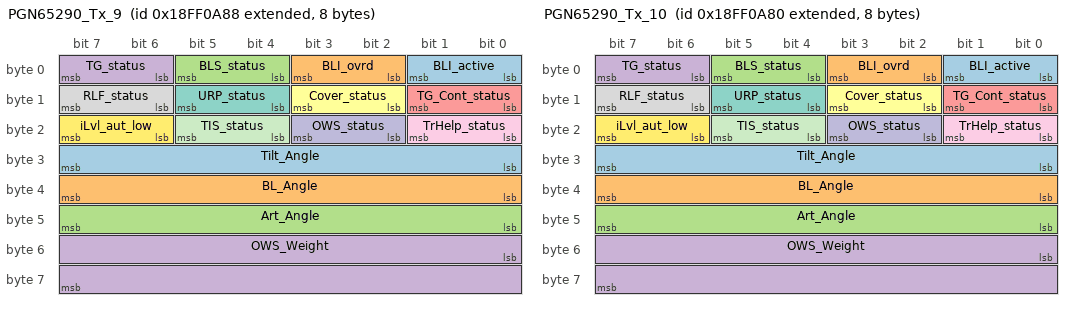
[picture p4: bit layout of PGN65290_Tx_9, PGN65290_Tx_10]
BO_ 2566851208 PGN65290_Tx_9 :8 CentralMulti
 SG_ BLI_active : 0|2@1+ (1,0) [0|3] "" Vector__XXX
 SG_ BLI_ovrd : 2|2@1+ (1,0) [0|3] "" Vector__XXX
 SG_ BLS_status : 4|2@1+ (1,0) [0|3] "" Vector__XXX
 SG_ TG_status : 6|2@1+ (1,0) [0|3] "" Vector__XXX
 SG_ TG_Cont_status : 8|2@1+ (1,0) [0|3] "" Vector__XXX
 SG_ Cover_status : 10|2@1+ (1,0) [0|3] "" Vector__XXX
 SG_ URP_status : 12|2@1+ (1,0) [0|3] "" Vector__XXX
 SG_ RLF_status : 14|2@1+ (1,0) [0|3] "" Vector__XXX
 SG_ TrHelp_status : 16|2@1+ (1,0) [0|3] "" Vector__XXX
 SG_ OWS_status : 18|2@1+ (1,0) [0|3] "" Vector__XXX
 SG_ TIS_status : 20|2@1+ (1,0) [0|3] "" Vector__XXX
 SG_ iLvl_aut_low : 22|2@1+ (1,0) [0|3] "" Vector__XXX
 SG_ Tilt_Angle : 24|8@1+ (1,-125) [0|255] "deg" Vector__XXX
 SG_ BL_Angle : 32|8@1+ (1,-125) [0|255] "deg" Vector__XXX
 SG_ Art_Angle : 40|8@1+ (1,-125) [0|255] "deg" Vector__XXX
 SG_ OWS_Weight : 48|16@1+ (10,0) [0|65535] "kg" Vector__XXX

BO_ 2566851200 PGN65290_Tx_10 :8 CentralMulti
 SG_ BLI_active : 0|2@1+ (1,0) [0|3] "" Vector__XXX
 SG_ BLI_ovrd : 2|2@1+ (1,0) [0|3] "" Vector__XXX
 SG_ BLS_status : 4|2@1+ (1,0) [0|3] "" Vector__XXX
 SG_ TG_status : 6|2@1+ (1,0) [0|3] "" Vector__XXX
 SG_ TG_Cont_status : 8|2@1+ (1,0) [0|3] "" Vector__XXX
 SG_ Cover_status : 10|2@1+ (1,0) [0|3] "" Vector__XXX
 SG_ URP_status : 12|2@1+ (1,0) [0|3] "" Vector__XXX
 SG_ RLF_status : 14|2@1+ (1,0) [0|3] "" Vector__XXX
 SG_ TrHelp_status : 16|2@1+ (1,0) [0|3] "" Vector__XXX
 SG_ OWS_status : 18|2@1+ (1,0) [0|3] "" Vector__XXX
 SG_ TIS_status : 20|2@1+ (1,0) [0|3] "" Vector__XXX
 SG_ iLvl_aut_low : 22|2@1+ (1,0) [0|3] "" Vector__XXX
 SG_ Tilt_Angle : 24|8@1+ (1,-125) [0|255] "deg" Vector__XXX
 SG_ BL_Angle : 32|8@1+ (1,-125) [0|255] "deg" Vector__XXX
 SG_ Art_Angle : 40|8@1+ (1,-125) [0|255] "deg" Vector__XXX
 SG_ OWS_Weight : 48|16@1+ (10,0) [0|65535] "kg" Vector__XXX

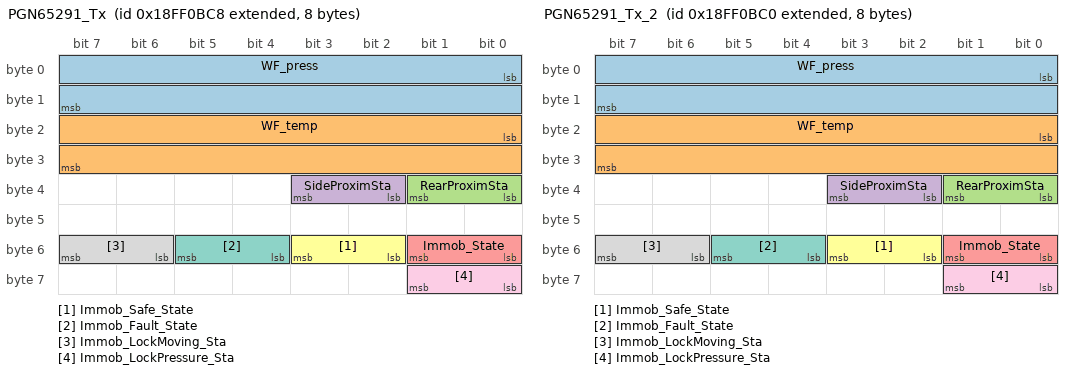
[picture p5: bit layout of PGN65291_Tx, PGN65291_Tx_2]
BO_ 2566851528 PGN65291_Tx :8 Central
 SG_ WF_press : 0|16@1+ (0.1,0) [0|65535] "bar" Vector__XXX
 SG_ WF_temp : 16|16@1+ (0.1,0) [0|65535] "C" Vector__XXX
 SG_ RearProximSta : 32|2@1+ (1,0) [0|3] "" Vector__XXX
 SG_ SideProximSta : 34|2@1+ (1,0) [0|3] "" Vector__XXX
 SG_ Immob_State : 48|2@1+ (1,0) [0|3] "" Vector__XXX
 SG_ Immob_Safe_State : 50|2@1+ (1,0) [0|3] "" Vector__XXX
 SG_ Immob_Fault_State : 52|2@1+ (1,0) [0|3] "" Vector__XXX
 SG_ Immob_LockMoving_Sta : 54|2@1+ (1,0) [0|3] "" Vector__XXX
 SG_ Immob_LockPressure_Sta : 56|2@1+ (1,0) [0|3] "" Vector__XXX

BO_ 2566851520 PGN65291_Tx_2 :8 CentralMulti
 SG_ WF_press : 0|16@1+ (0.1,0) [0|65535] "bar" Vector__XXX
 SG_ WF_temp : 16|16@1+ (0.1,0) [0|65535] "C" Vector__XXX
 SG_ RearProximSta : 32|2@1+ (1,0) [0|3] "" Vector__XXX
 SG_ SideProximSta : 34|2@1+ (1,0) [0|3] "" Vector__XXX
 SG_ Immob_State : 48|2@1+ (1,0) [0|3] "" Vector__XXX
 SG_ Immob_Safe_State : 50|2@1+ (1,0) [0|3] "" Vector__XXX
 SG_ Immob_Fault_State : 52|2@1+ (1,0) [0|3] "" Vector__XXX
 SG_ Immob_LockMoving_Sta : 54|2@1+ (1,0) [0|3] "" Vector__XXX
 SG_ Immob_LockPressure_Sta : 56|2@1+ (1,0) [0|3] "" Vector__XXX

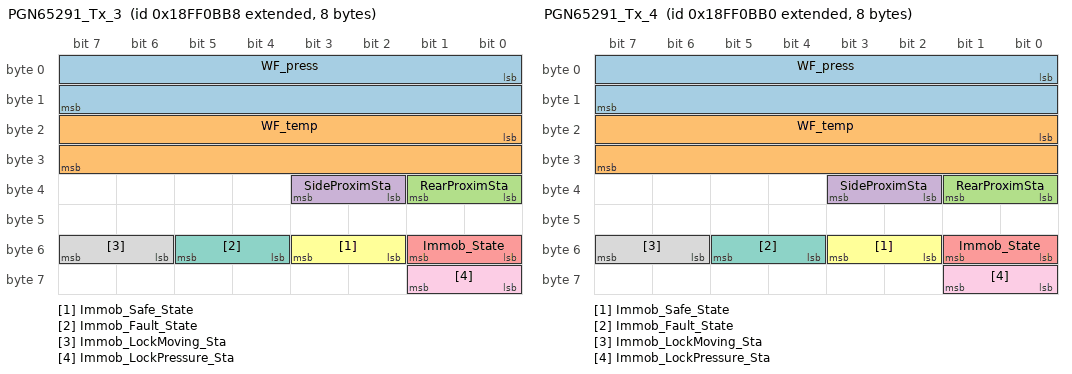
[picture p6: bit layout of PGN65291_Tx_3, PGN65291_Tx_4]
BO_ 2566851512 PGN65291_Tx_3 :8 CentralMulti
 SG_ WF_press : 0|16@1+ (0.1,0) [0|65535] "bar" Vector__XXX
 SG_ WF_temp : 16|16@1+ (0.1,0) [0|65535] "C" Vector__XXX
 SG_ RearProximSta : 32|2@1+ (1,0) [0|3] "" Vector__XXX
 SG_ SideProximSta : 34|2@1+ (1,0) [0|3] "" Vector__XXX
 SG_ Immob_State : 48|2@1+ (1,0) [0|3] "" Vector__XXX
 SG_ Immob_Safe_State : 50|2@1+ (1,0) [0|3] "" Vector__XXX
 SG_ Immob_Fault_State : 52|2@1+ (1,0) [0|3] "" Vector__XXX
 SG_ Immob_LockMoving_Sta : 54|2@1+ (1,0) [0|3] "" Vector__XXX
 SG_ Immob_LockPressure_Sta : 56|2@1+ (1,0) [0|3] "" Vector__XXX

BO_ 2566851504 PGN65291_Tx_4 :8 CentralMulti
 SG_ WF_press : 0|16@1+ (0.1,0) [0|65535] "bar" Vector__XXX
 SG_ WF_temp : 16|16@1+ (0.1,0) [0|65535] "C" Vector__XXX
 SG_ RearProximSta : 32|2@1+ (1,0) [0|3] "" Vector__XXX
 SG_ SideProximSta : 34|2@1+ (1,0) [0|3] "" Vector__XXX
 SG_ Immob_State : 48|2@1+ (1,0) [0|3] "" Vector__XXX
 SG_ Immob_Safe_State : 50|2@1+ (1,0) [0|3] "" Vector__XXX
 SG_ Immob_Fault_State : 52|2@1+ (1,0) [0|3] "" Vector__XXX
 SG_ Immob_LockMoving_Sta : 54|2@1+ (1,0) [0|3] "" Vector__XXX
 SG_ Immob_LockPressure_Sta : 56|2@1+ (1,0) [0|3] "" Vector__XXX

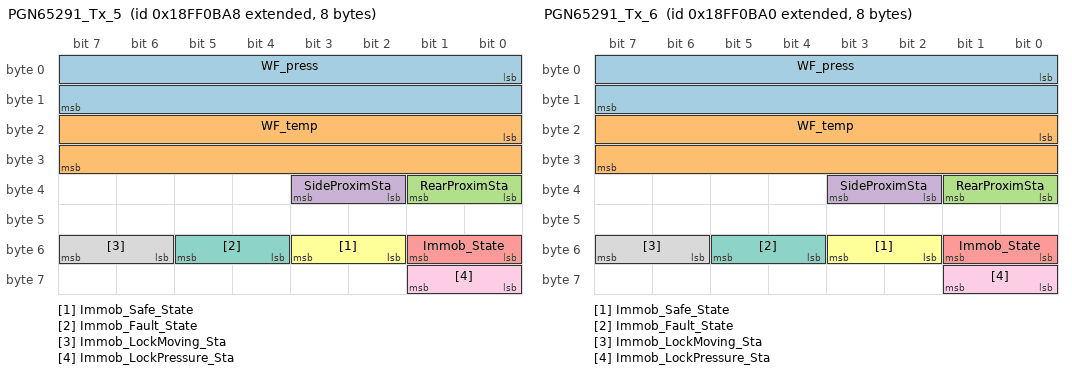
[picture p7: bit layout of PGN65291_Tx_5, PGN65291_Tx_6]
BO_ 2566851496 PGN65291_Tx_5 :8 CentralMulti
 SG_ WF_press : 0|16@1+ (0.1,0) [0|65535] "bar" Vector__XXX
 SG_ WF_temp : 16|16@1+ (0.1,0) [0|65535] "C" Vector__XXX
 SG_ RearProximSta : 32|2@1+ (1,0) [0|3] "" Vector__XXX
 SG_ SideProximSta : 34|2@1+ (1,0) [0|3] "" Vector__XXX
 SG_ Immob_State : 48|2@1+ (1,0) [0|3] "" Vector__XXX
 SG_ Immob_Safe_State : 50|2@1+ (1,0) [0|3] "" Vector__XXX
 SG_ Immob_Fault_State : 52|2@1+ (1,0) [0|3] "" Vector__XXX
 SG_ Immob_LockMoving_Sta : 54|2@1+ (1,0) [0|3] "" Vector__XXX
 SG_ Immob_LockPressure_Sta : 56|2@1+ (1,0) [0|3] "" Vector__XXX

BO_ 2566851488 PGN65291_Tx_6 :8 CentralMulti
 SG_ WF_press : 0|16@1+ (0.1,0) [0|65535] "bar" Vector__XXX
 SG_ WF_temp : 16|16@1+ (0.1,0) [0|65535] "C" Vector__XXX
 SG_ RearProximSta : 32|2@1+ (1,0) [0|3] "" Vector__XXX
 SG_ SideProximSta : 34|2@1+ (1,0) [0|3] "" Vector__XXX
 SG_ Immob_State : 48|2@1+ (1,0) [0|3] "" Vector__XXX
 SG_ Immob_Safe_State : 50|2@1+ (1,0) [0|3] "" Vector__XXX
 SG_ Immob_Fault_State : 52|2@1+ (1,0) [0|3] "" Vector__XXX
 SG_ Immob_LockMoving_Sta : 54|2@1+ (1,0) [0|3] "" Vector__XXX
 SG_ Immob_LockPressure_Sta : 56|2@1+ (1,0) [0|3] "" Vector__XXX

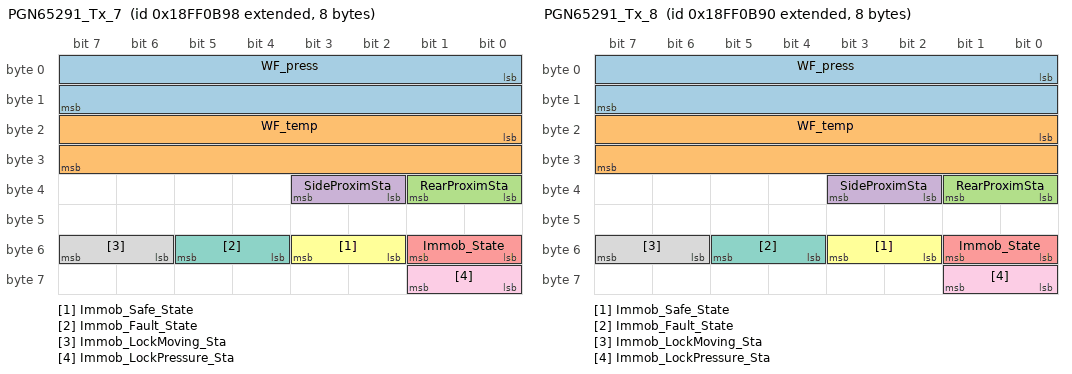
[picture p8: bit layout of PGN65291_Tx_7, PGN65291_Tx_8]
BO_ 2566851480 PGN65291_Tx_7 :8 CentralMulti
 SG_ WF_press : 0|16@1+ (0.1,0) [0|65535] "bar" Vector__XXX
 SG_ WF_temp : 16|16@1+ (0.1,0) [0|65535] "C" Vector__XXX
 SG_ RearProximSta : 32|2@1+ (1,0) [0|3] "" Vector__XXX
 SG_ SideProximSta : 34|2@1+ (1,0) [0|3] "" Vector__XXX
 SG_ Immob_State : 48|2@1+ (1,0) [0|3] "" Vector__XXX
 SG_ Immob_Safe_State : 50|2@1+ (1,0) [0|3] "" Vector__XXX
 SG_ Immob_Fault_State : 52|2@1+ (1,0) [0|3] "" Vector__XXX
 SG_ Immob_LockMoving_Sta : 54|2@1+ (1,0) [0|3] "" Vector__XXX
 SG_ Immob_LockPressure_Sta : 56|2@1+ (1,0) [0|3] "" Vector__XXX

BO_ 2566851472 PGN65291_Tx_8 :8 CentralMulti
 SG_ WF_press : 0|16@1+ (0.1,0) [0|65535] "bar" Vector__XXX
 SG_ WF_temp : 16|16@1+ (0.1,0) [0|65535] "C" Vector__XXX
 SG_ RearProximSta : 32|2@1+ (1,0) [0|3] "" Vector__XXX
 SG_ SideProximSta : 34|2@1+ (1,0) [0|3] "" Vector__XXX
 SG_ Immob_State : 48|2@1+ (1,0) [0|3] "" Vector__XXX
 SG_ Immob_Safe_State : 50|2@1+ (1,0) [0|3] "" Vector__XXX
 SG_ Immob_Fault_State : 52|2@1+ (1,0) [0|3] "" Vector__XXX
 SG_ Immob_LockMoving_Sta : 54|2@1+ (1,0) [0|3] "" Vector__XXX
 SG_ Immob_LockPressure_Sta : 56|2@1+ (1,0) [0|3] "" Vector__XXX

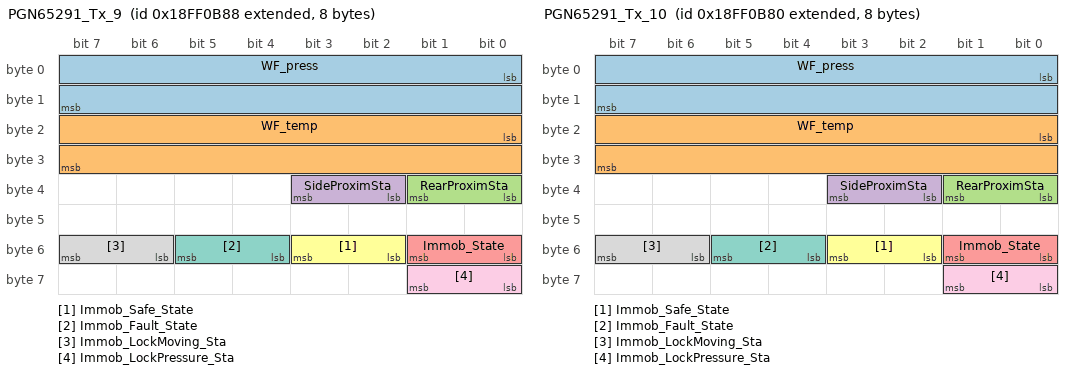
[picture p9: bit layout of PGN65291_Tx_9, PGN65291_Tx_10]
BO_ 2566851464 PGN65291_Tx_9 :8 CentralMulti
 SG_ WF_press : 0|16@1+ (0.1,0) [0|65535] "bar" Vector__XXX
 SG_ WF_temp : 16|16@1+ (0.1,0) [0|65535] "C" Vector__XXX
 SG_ RearProximSta : 32|2@1+ (1,0) [0|3] "" Vector__XXX
 SG_ SideProximSta : 34|2@1+ (1,0) [0|3] "" Vector__XXX
 SG_ Immob_State : 48|2@1+ (1,0) [0|3] "" Vector__XXX
 SG_ Immob_Safe_State : 50|2@1+ (1,0) [0|3] "" Vector__XXX
 SG_ Immob_Fault_State : 52|2@1+ (1,0) [0|3] "" Vector__XXX
 SG_ Immob_LockMoving_Sta : 54|2@1+ (1,0) [0|3] "" Vector__XXX
 SG_ Immob_LockPressure_Sta : 56|2@1+ (1,0) [0|3] "" Vector__XXX

BO_ 2566851456 PGN65291_Tx_10 :8 CentralMulti
 SG_ WF_press : 0|16@1+ (0.1,0) [0|65535] "bar" Vector__XXX
 SG_ WF_temp : 16|16@1+ (0.1,0) [0|65535] "C" Vector__XXX
 SG_ RearProximSta : 32|2@1+ (1,0) [0|3] "" Vector__XXX
 SG_ SideProximSta : 34|2@1+ (1,0) [0|3] "" Vector__XXX
 SG_ Immob_State : 48|2@1+ (1,0) [0|3] "" Vector__XXX
 SG_ Immob_Safe_State : 50|2@1+ (1,0) [0|3] "" Vector__XXX
 SG_ Immob_Fault_State : 52|2@1+ (1,0) [0|3] "" Vector__XXX
 SG_ Immob_LockMoving_Sta : 54|2@1+ (1,0) [0|3] "" Vector__XXX
 SG_ Immob_LockPressure_Sta : 56|2@1+ (1,0) [0|3] "" Vector__XXX

BO_ 2566913480 PGN65533_Tx :8 Central
 SG_ ServiceDist : 0|32@1+ (0.005,-10527703) [0|4294967295] "km" Vector__XXX

BO_ 2566913472 PGN65533_Tx_2 :8 CentralMulti
 SG_ ServiceDist : 0|32@1+ (0.005,-10527703) [0|4294967295] "km" Vector__XXX

BO_ 2566913464 PGN65533_Tx_3 :8 CentralMulti
 SG_ ServiceDist : 0|32@1+ (0.005,-10527703) [0|4294967295] "km" Vector__XXX

BO_ 2566913456 PGN65533_Tx_4 :8 CentralMulti
 SG_ ServiceDist : 0|32@1+ (0.005,-10527703) [0|4294967295] "km" Vector__XXX

BO_ 2566913448 PGN65533_Tx_5 :8 CentralMulti
 SG_ ServiceDist : 0|32@1+ (0.005,-10527703) [0|4294967295] "km" Vector__XXX

BO_ 2566913440 PGN65533_Tx_6 :8 CentralMulti
 SG_ ServiceDist : 0|32@1+ (0.005,-10527703) [0|4294967295] "km" Vector__XXX

BO_ 2566913432 PGN65533_Tx_7 :8 CentralMulti
 SG_ ServiceDist : 0|32@1+ (0.005,-10527703) [0|4294967295] "km" Vector__XXX

BO_ 2566913424 PGN65533_Tx_8 :8 CentralMulti
 SG_ ServiceDist : 0|32@1+ (0.005,-10527703) [0|4294967295] "km" Vector__XXX

BO_ 2566913416 PGN65533_Tx_9 :8 CentralMulti
 SG_ ServiceDist : 0|32@1+ (0.005,-10527703) [0|4294967295] "km" Vector__XXX

BO_ 2566913408 PGN65533_Tx_10 :8 CentralMulti
 SG_ ServiceDist : 0|32@1+ (0.005,-10527703) [0|4294967295] "km" Vector__XXX

BO_ 2566913736 PGN65534_Tx :8 Central
 SG_ Data : 0|64@1+ (1,0) [0|0] "" Vector__XXX

BO_ 2566913728 PGN65534_Tx_2 :8 CentralMulti
 SG_ Data : 0|64@1+ (1,0) [0|0] "" Vector__XXX

BO_ 2566913720 PGN65534_Tx_3 :8 CentralMulti
 SG_ Data : 0|64@1+ (1,0) [0|0] "" Vector__XXX

BO_ 2566913712 PGN65534_Tx_4 :8 CentralMulti
 SG_ Data : 0|64@1+ (1,0) [0|0] "" Vector__XXX

BO_ 2566913704 PGN65534_Tx_5 :8 CentralMulti
 SG_ Data : 0|64@1+ (1,0) [0|0] "" Vector__XXX

BO_ 2566913696 PGN65534_Tx_6 :8 CentralMulti
 SG_ Data : 0|64@1+ (1,0) [0|0] "" Vector__XXX

BO_ 2566913688 PGN65534_Tx_7 :8 CentralMulti
 SG_ Data : 0|64@1+ (1,0) [0|0] "" Vector__XXX

BO_ 2566913680 PGN65534_Tx_8 :8 CentralMulti
 SG_ Data : 0|64@1+ (1,0) [0|0] "" Vector__XXX

BO_ 2566913672 PGN65534_Tx_9 :8 CentralMulti
 SG_ Data : 0|64@1+ (1,0) [0|0] "" Vector__XXX

BO_ 2566913664 PGN65534_Tx_10 :8 CentralMulti
 SG_ Data : 0|64@1+ (1,0) [0|0] "" Vector__XXX

BO_ 2566913992 PGN65535_Tx :8 Central
 SG_ VlvVolt : 0|16@1+ (0.05,0) [0|65535] "V" Vector__XXX
 SG_ ElVolt : 16|16@1+ (0.05,0) [0|65535] "V" Vector__XXX
 SG_ BogLoadPrc : 32|8@1+ (1,0) [0|255] "%" Vector__XXX
 SG_ TrlLoadPrc : 40|8@1+ (1,0) [0|255] "%" Vector__XXX

BO_ 2566913984 PGN65535_Tx_2 :8 CentralMulti
 SG_ VlvVolt : 0|16@1+ (0.05,0) [0|65535] "V" Vector__XXX
 SG_ ElVolt : 16|16@1+ (0.05,0) [0|65535] "V" Vector__XXX
 SG_ BogLoadPrc : 32|8@1+ (1,0) [0|255] "%" Vector__XXX
 SG_ TrlLoadPrc : 40|8@1+ (1,0) [0|255] "%" Vector__XXX

BO_ 2566913976 PGN65535_Tx_3 :8 CentralMulti
 SG_ VlvVolt : 0|16@1+ (0.05,0) [0|65535] "V" Vector__XXX
 SG_ ElVolt : 16|16@1+ (0.05,0) [0|65535] "V" Vector__XXX
 SG_ BogLoadPrc : 32|8@1+ (1,0) [0|255] "%" Vector__XXX
 SG_ TrlLoadPrc : 40|8@1+ (1,0) [0|255] "%" Vector__XXX

BO_ 2566913968 PGN65535_Tx_4 :8 CentralMulti
 SG_ VlvVolt : 0|16@1+ (0.05,0) [0|65535] "V" Vector__XXX
 SG_ ElVolt : 16|16@1+ (0.05,0) [0|65535] "V" Vector__XXX
 SG_ BogLoadPrc : 32|8@1+ (1,0) [0|255] "%" Vector__XXX
 SG_ TrlLoadPrc : 40|8@1+ (1,0) [0|255] "%" Vector__XXX

BO_ 2566913960 PGN65535_Tx_5 :8 CentralMulti
 SG_ VlvVolt : 0|16@1+ (0.05,0) [0|65535] "V" Vector__XXX
 SG_ ElVolt : 16|16@1+ (0.05,0) [0|65535] "V" Vector__XXX
 SG_ BogLoadPrc : 32|8@1+ (1,0) [0|255] "%" Vector__XXX
 SG_ TrlLoadPrc : 40|8@1+ (1,0) [0|255] "%" Vector__XXX

BO_ 2566913952 PGN65535_Tx_6 :8 CentralMulti
 SG_ VlvVolt : 0|16@1+ (0.05,0) [0|65535] "V" Vector__XXX
 SG_ ElVolt : 16|16@1+ (0.05,0) [0|65535] "V" Vector__XXX
 SG_ BogLoadPrc : 32|8@1+ (1,0) [0|255] "%" Vector__XXX
 SG_ TrlLoadPrc : 40|8@1+ (1,0) [0|255] "%" Vector__XXX

BO_ 2566913944 PGN65535_Tx_7 :8 CentralMulti
 SG_ VlvVolt : 0|16@1+ (0.05,0) [0|65535] "V" Vector__XXX
 SG_ ElVolt : 16|16@1+ (0.05,0) [0|65535] "V" Vector__XXX
 SG_ BogLoadPrc : 32|8@1+ (1,0) [0|255] "%" Vector__XXX
 SG_ TrlLoadPrc : 40|8@1+ (1,0) [0|255] "%" Vector__XXX

BO_ 2566913936 PGN65535_Tx_8 :8 CentralMulti
 SG_ VlvVolt : 0|16@1+ (0.05,0) [0|65535] "V" Vector__XXX
 SG_ ElVolt : 16|16@1+ (0.05,0) [0|65535] "V" Vector__XXX
 SG_ BogLoadPrc : 32|8@1+ (1,0) [0|255] "%" Vector__XXX
 SG_ TrlLoadPrc : 40|8@1+ (1,0) [0|255] "%" Vector__XXX

BO_ 2566913928 PGN65535_Tx_9 :8 CentralMulti
 SG_ VlvVolt : 0|16@1+ (0.05,0) [0|65535] "V" Vector__XXX
 SG_ ElVolt : 16|16@1+ (0.05,0) [0|65535] "V" Vector__XXX
 SG_ BogLoadPrc : 32|8@1+ (1,0) [0|255] "%" Vector__XXX
 SG_ TrlLoadPrc : 40|8@1+ (1,0) [0|255] "%" Vector__XXX

BO_ 2566913920 PGN65535_Tx_10 :8 CentralMulti
 SG_ VlvVolt : 0|16@1+ (0.05,0) [0|65535] "V" Vector__XXX
 SG_ ElVolt : 16|16@1+ (0.05,0) [0|65535] "V" Vector__XXX
 SG_ BogLoadPrc : 32|8@1+ (1,0) [0|255] "%" Vector__XXX
 SG_ TrlLoadPrc : 40|8@1+ (1,0) [0|255] "%" Vector__XXX

BO_ 2499791651 TIM_IO_Rx :8 TIM
 SG_ Aux31Error : 0|4@1+ (1,0) [0|15] "" Central
 SG_ Aux31Input : 8|2@1+ (1,0) [0|3] "" Central
 SG_ Aux32Error : 16|4@1+ (1,0) [0|15] "" Central
 SG_ Aux32Input : 24|2@1+ (1,0) [0|3] "" Central
 SG_ AuxADValue : 32|12@1+ (1,0) [0|4095] "" Central
 SG_ AuxADIndex : 44|4@1+ (1,0) [0|15] "" Central

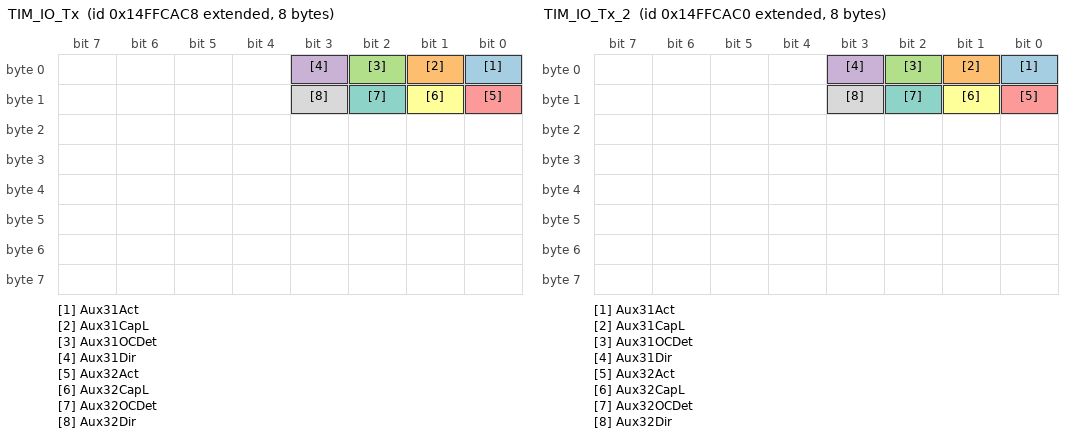
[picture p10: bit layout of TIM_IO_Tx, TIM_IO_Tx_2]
BO_ 2499791560 TIM_IO_Tx :8 Central
 SG_ Aux31Act : 0|1@1+ (1,0) [0|1] "" Vector__XXX
 SG_ Aux31CapL : 1|1@1+ (1,0) [0|1] "" Vector__XXX
 SG_ Aux31OCDet : 2|1@1+ (1,0) [0|1] "" Vector__XXX
 SG_ Aux31Dir : 3|1@1+ (1,0) [0|1] "" Vector__XXX
 SG_ Aux32Act : 8|1@1+ (1,0) [0|1] "" Vector__XXX
 SG_ Aux32CapL : 9|1@1+ (1,0) [0|1] "" Vector__XXX
 SG_ Aux32OCDet : 10|1@1+ (1,0) [0|1] "" Vector__XXX
 SG_ Aux32Dir : 11|1@1+ (1,0) [0|1] "" Vector__XXX

BO_ 2499791552 TIM_IO_Tx_2 :8 CentralMulti
 SG_ Aux31Act : 0|1@1+ (1,0) [0|1] "" Vector__XXX
 SG_ Aux31CapL : 1|1@1+ (1,0) [0|1] "" Vector__XXX
 SG_ Aux31OCDet : 2|1@1+ (1,0) [0|1] "" Vector__XXX
 SG_ Aux31Dir : 3|1@1+ (1,0) [0|1] "" Vector__XXX
 SG_ Aux32Act : 8|1@1+ (1,0) [0|1] "" Vector__XXX
 SG_ Aux32CapL : 9|1@1+ (1,0) [0|1] "" Vector__XXX
 SG_ Aux32OCDet : 10|1@1+ (1,0) [0|1] "" Vector__XXX
 SG_ Aux32Dir : 11|1@1+ (1,0) [0|1] "" Vector__XXX

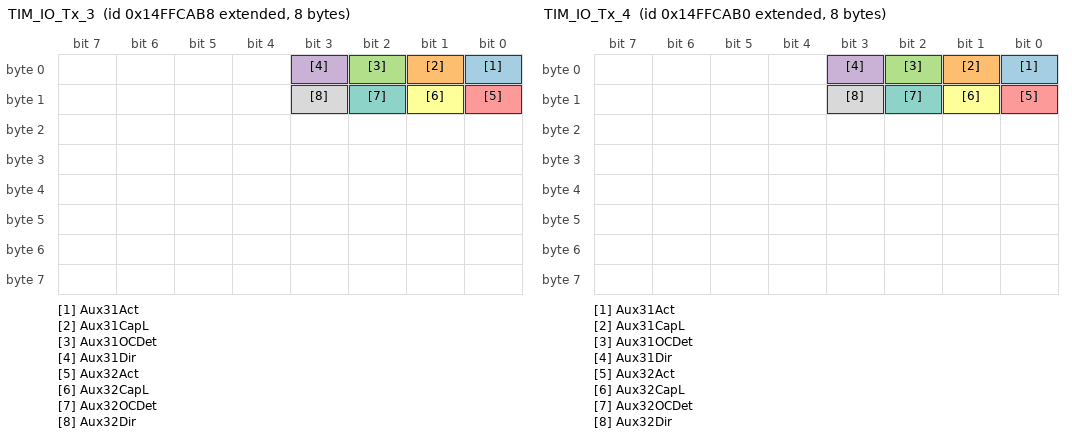
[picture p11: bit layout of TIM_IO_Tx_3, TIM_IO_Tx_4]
BO_ 2499791544 TIM_IO_Tx_3 :8 CentralMulti
 SG_ Aux31Act : 0|1@1+ (1,0) [0|1] "" Vector__XXX
 SG_ Aux31CapL : 1|1@1+ (1,0) [0|1] "" Vector__XXX
 SG_ Aux31OCDet : 2|1@1+ (1,0) [0|1] "" Vector__XXX
 SG_ Aux31Dir : 3|1@1+ (1,0) [0|1] "" Vector__XXX
 SG_ Aux32Act : 8|1@1+ (1,0) [0|1] "" Vector__XXX
 SG_ Aux32CapL : 9|1@1+ (1,0) [0|1] "" Vector__XXX
 SG_ Aux32OCDet : 10|1@1+ (1,0) [0|1] "" Vector__XXX
 SG_ Aux32Dir : 11|1@1+ (1,0) [0|1] "" Vector__XXX

BO_ 2499791536 TIM_IO_Tx_4 :8 CentralMulti
 SG_ Aux31Act : 0|1@1+ (1,0) [0|1] "" Vector__XXX
 SG_ Aux31CapL : 1|1@1+ (1,0) [0|1] "" Vector__XXX
 SG_ Aux31OCDet : 2|1@1+ (1,0) [0|1] "" Vector__XXX
 SG_ Aux31Dir : 3|1@1+ (1,0) [0|1] "" Vector__XXX
 SG_ Aux32Act : 8|1@1+ (1,0) [0|1] "" Vector__XXX
 SG_ Aux32CapL : 9|1@1+ (1,0) [0|1] "" Vector__XXX
 SG_ Aux32OCDet : 10|1@1+ (1,0) [0|1] "" Vector__XXX
 SG_ Aux32Dir : 11|1@1+ (1,0) [0|1] "" Vector__XXX

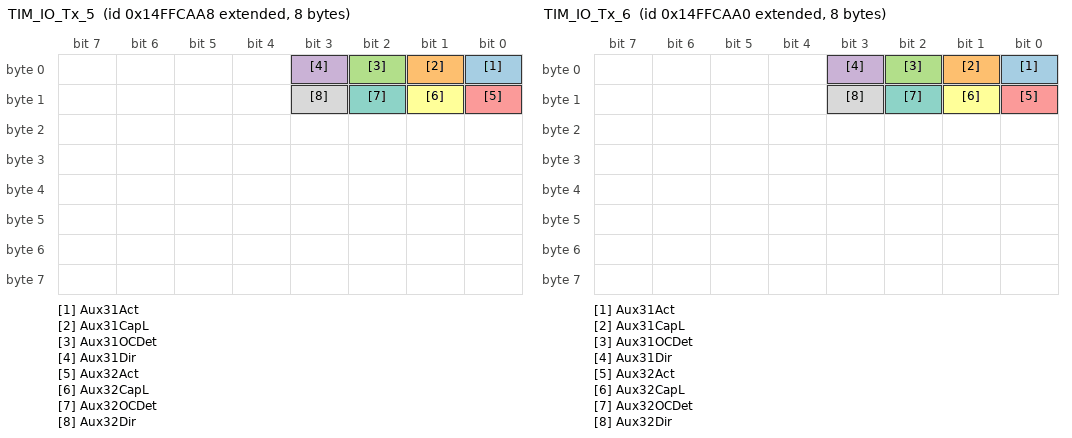
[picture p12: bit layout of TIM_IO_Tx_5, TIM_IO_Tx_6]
BO_ 2499791528 TIM_IO_Tx_5 :8 CentralMulti
 SG_ Aux31Act : 0|1@1+ (1,0) [0|1] "" Vector__XXX
 SG_ Aux31CapL : 1|1@1+ (1,0) [0|1] "" Vector__XXX
 SG_ Aux31OCDet : 2|1@1+ (1,0) [0|1] "" Vector__XXX
 SG_ Aux31Dir : 3|1@1+ (1,0) [0|1] "" Vector__XXX
 SG_ Aux32Act : 8|1@1+ (1,0) [0|1] "" Vector__XXX
 SG_ Aux32CapL : 9|1@1+ (1,0) [0|1] "" Vector__XXX
 SG_ Aux32OCDet : 10|1@1+ (1,0) [0|1] "" Vector__XXX
 SG_ Aux32Dir : 11|1@1+ (1,0) [0|1] "" Vector__XXX

BO_ 2499791520 TIM_IO_Tx_6 :8 CentralMulti
 SG_ Aux31Act : 0|1@1+ (1,0) [0|1] "" Vector__XXX
 SG_ Aux31CapL : 1|1@1+ (1,0) [0|1] "" Vector__XXX
 SG_ Aux31OCDet : 2|1@1+ (1,0) [0|1] "" Vector__XXX
 SG_ Aux31Dir : 3|1@1+ (1,0) [0|1] "" Vector__XXX
 SG_ Aux32Act : 8|1@1+ (1,0) [0|1] "" Vector__XXX
 SG_ Aux32CapL : 9|1@1+ (1,0) [0|1] "" Vector__XXX
 SG_ Aux32OCDet : 10|1@1+ (1,0) [0|1] "" Vector__XXX
 SG_ Aux32Dir : 11|1@1+ (1,0) [0|1] "" Vector__XXX

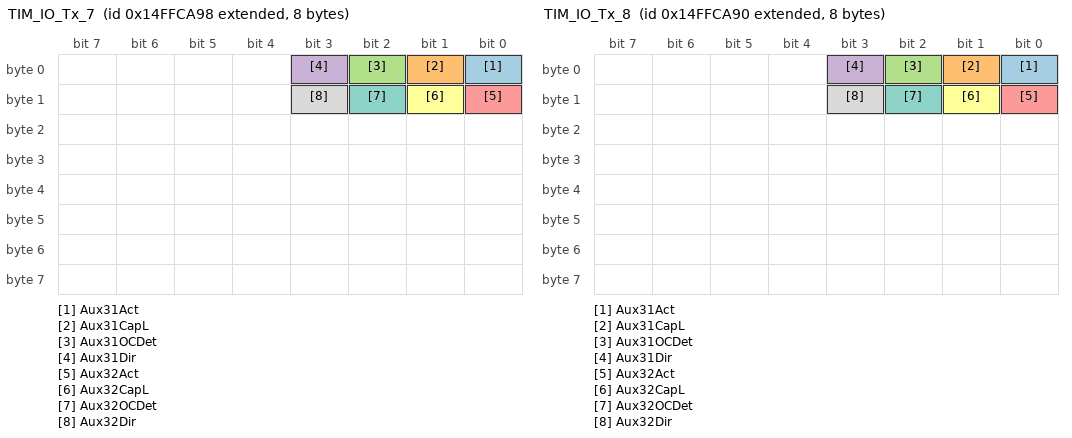
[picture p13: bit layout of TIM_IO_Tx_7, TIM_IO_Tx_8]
BO_ 2499791512 TIM_IO_Tx_7 :8 CentralMulti
 SG_ Aux31Act : 0|1@1+ (1,0) [0|1] "" Vector__XXX
 SG_ Aux31CapL : 1|1@1+ (1,0) [0|1] "" Vector__XXX
 SG_ Aux31OCDet : 2|1@1+ (1,0) [0|1] "" Vector__XXX
 SG_ Aux31Dir : 3|1@1+ (1,0) [0|1] "" Vector__XXX
 SG_ Aux32Act : 8|1@1+ (1,0) [0|1] "" Vector__XXX
 SG_ Aux32CapL : 9|1@1+ (1,0) [0|1] "" Vector__XXX
 SG_ Aux32OCDet : 10|1@1+ (1,0) [0|1] "" Vector__XXX
 SG_ Aux32Dir : 11|1@1+ (1,0) [0|1] "" Vector__XXX

BO_ 2499791504 TIM_IO_Tx_8 :8 CentralMulti
 SG_ Aux31Act : 0|1@1+ (1,0) [0|1] "" Vector__XXX
 SG_ Aux31CapL : 1|1@1+ (1,0) [0|1] "" Vector__XXX
 SG_ Aux31OCDet : 2|1@1+ (1,0) [0|1] "" Vector__XXX
 SG_ Aux31Dir : 3|1@1+ (1,0) [0|1] "" Vector__XXX
 SG_ Aux32Act : 8|1@1+ (1,0) [0|1] "" Vector__XXX
 SG_ Aux32CapL : 9|1@1+ (1,0) [0|1] "" Vector__XXX
 SG_ Aux32OCDet : 10|1@1+ (1,0) [0|1] "" Vector__XXX
 SG_ Aux32Dir : 11|1@1+ (1,0) [0|1] "" Vector__XXX

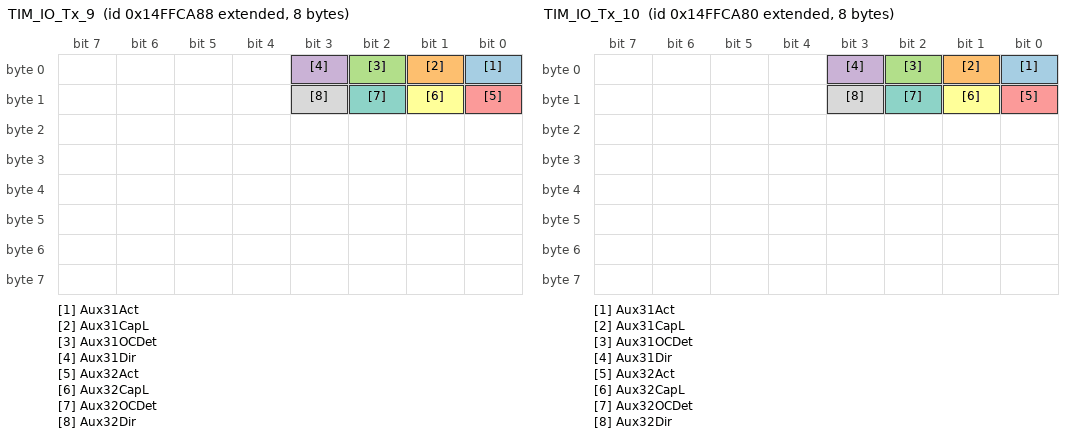
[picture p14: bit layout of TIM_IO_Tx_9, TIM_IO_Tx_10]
BO_ 2499791496 TIM_IO_Tx_9 :8 CentralMulti
 SG_ Aux31Act : 0|1@1+ (1,0) [0|1] "" Vector__XXX
 SG_ Aux31CapL : 1|1@1+ (1,0) [0|1] "" Vector__XXX
 SG_ Aux31OCDet : 2|1@1+ (1,0) [0|1] "" Vector__XXX
 SG_ Aux31Dir : 3|1@1+ (1,0) [0|1] "" Vector__XXX
 SG_ Aux32Act : 8|1@1+ (1,0) [0|1] "" Vector__XXX
 SG_ Aux32CapL : 9|1@1+ (1,0) [0|1] "" Vector__XXX
 SG_ Aux32OCDet : 10|1@1+ (1,0) [0|1] "" Vector__XXX
 SG_ Aux32Dir : 11|1@1+ (1,0) [0|1] "" Vector__XXX

BO_ 2499791488 TIM_IO_Tx_10 :8 CentralMulti
 SG_ Aux31Act : 0|1@1+ (1,0) [0|1] "" Vector__XXX
 SG_ Aux31CapL : 1|1@1+ (1,0) [0|1] "" Vector__XXX
 SG_ Aux31OCDet : 2|1@1+ (1,0) [0|1] "" Vector__XXX
 SG_ Aux31Dir : 3|1@1+ (1,0) [0|1] "" Vector__XXX
 SG_ Aux32Act : 8|1@1+ (1,0) [0|1] "" Vector__XXX
 SG_ Aux32CapL : 9|1@1+ (1,0) [0|1] "" Vector__XXX
 SG_ Aux32OCDet : 10|1@1+ (1,0) [0|1] "" Vector__XXX
 SG_ Aux32Dir : 11|1@1+ (1,0) [0|1] "" Vector__XXX

BO_ 2566848547 VirtualSwitch :8 TIM
 SG_ TH_SWITCH : 0|2@1+ (1,0) [0|3] "" Central
 SG_ TH_BUTTON : 2|2@1+ (1,0) [0|3] "" Central
 SG_ MH_SWITCH : 4|2@1+ (1,0) [0|3] "" Central
 SG_ MH_BUTTON : 6|2@1+ (1,0) [0|3] "" Central
 SG_ LL_SWITCH : 8|2@1+ (1,0) [0|3] "" Central
 SG_ LL1_SWITCH : 10|2@1+ (1,0) [0|3] "" Central
 SG_ LL2_SWITCH : 12|2@1+ (1,0) [0|3] "" Central
 SG_ LL_BUTTON : 14|2@1+ (1,0) [0|3] "" Central
 SG_ LL1_BUTTON : 16|2@1+ (1,0) [0|3] "" Central
 SG_ LL2_BUTTON : 18|2@1+ (1,0) [0|3] "" Central
 SG_ LLTH : 20|2@1+ (1,0) [0|3] "" Central
 SG_ FM : 22|2@1+ (1,0) [0|3] "" Central
 SG_ ADL_IPA : 24|2@1+ (1,0) [0|3] "" Central
 SG_ ADL_IPB : 26|2@1+ (1,0) [0|3] "" Central
 SG_ ADL_IPC : 28|2@1+ (1,0) [0|3] "" Central
 SG_ ADL_IPD : 30|2@1+ (1,0) [0|3] "" Central
 SG_ ADL_IPE : 32|2@1+ (1,0) [0|3] "" Central
 SG_ ADL_IPF : 34|2@1+ (1,0) [0|3] "" Central
 SG_ LC1_State : 36|2@1+ (1,0) [0|3] "" Central
 SG_ LC2_State : 38|2@1+ (1,0) [0|3] "" Central
 SG_ BodyLift : 40|2@1+ (1,0) [0|3] "" Central
 SG_ RLF : 42|2@1+ (1,0) [0|3] "" Central
 SG_ TRI_ADL_A_VirtualSwitch : 44|2@1+ (1,0) [0|3] "" Central
 SG_ TRI_ADL_B_VirtualSwitch : 46|2@1+ (1,0) [0|3] "" Central
 SG_ TRI_ADL_C_VirtualSwitch : 48|2@1+ (1,0) [0|3] "" Central
 SG_ TRI_ADL_D_VirtualSwitch : 50|2@1+ (1,0) [0|3] "" Central
 SG_ TRI_REVERSE_VirtualSwitch : 52|2@1+ (1,0) [0|3] "" Central
 SG_ LSP_SWITCH : 54|2@1+ (1,0) [0|3] "" Central
 SG_ LSP_BUTTON : 56|2@1+ (1,0) [0|3] "" Central
 SG_ TSR_BUTTON : 58|2@1+ (1,0) [0|3] "" Central
 SG_ TBR_BUTTON : 60|2@1+ (1,0) [0|3] "" Central
 SG_ TBR_IL_SW : 62|2@1+ (1,0) [0|3] "" Central

BO_ 2566848803 VirtualSwitchExt :8 TIM
 SG_ TH_SW__TBR_BU : 0|2@1+ (1,0) [0|3] "" Central
 SG_ TH_BU__TBR_IL_SW : 2|2@1+ (1,0) [0|3] "" Central
 SG_ MH_SW__ELC_FR_UP : 4|2@1+ (1,0) [0|3] "" Central
 SG_ MH_BU__ELC_FR_DN : 6|2@1+ (1,0) [0|3] "" Central
 SG_ LL_SW__ELC_RE_UP : 8|2@1+ (1,0) [0|3] "" Central
 SG_ LL1_SW__ELC_RE_DN : 10|2@1+ (1,0) [0|3] "" Central
 SG_ LL2_SW__ELC_FR_M1 : 12|2@1+ (1,0) [0|3] "" Central
 SG_ LL_BU__ELC_RE_M1 : 14|2@1+ (1,0) [0|3] "" Central
 SG_ LL1_BU__ELC_FR_M2 : 16|2@1+ (1,0) [0|3] "" Central
 SG_ LL2_BU__ELC_RE_M2 : 18|2@1+ (1,0) [0|3] "" Central
 SG_ LLTH__ELC_FR_DL1 : 20|2@1+ (1,0) [0|3] "" Central
 SG_ FM__ELC_RE_DL1 : 22|2@1+ (1,0) [0|3] "" Central
 SG_ ADL_IPA__ELC_FR_DL2 : 24|2@1+ (1,0) [0|3] "" Central
 SG_ ADL_IPB__ELC_RE_DL2 : 26|2@1+ (1,0) [0|3] "" Central
 SG_ ADL_IPC__ELC_FR_DL3 : 28|2@1+ (1,0) [0|3] "" Central
 SG_ ADL_IPD__ELC_RE_DL3 : 30|2@1+ (1,0) [0|3] "" Central
 SG_ ADL_IPE__ELC_FR_TOP : 32|2@1+ (1,0) [0|3] "" Central
 SG_ ADL_IPF__ELC_RE_TOP : 34|2@1+ (1,0) [0|3] "" Central
 SG_ LC1_State__ELC_FR_BOT : 36|2@1+ (1,0) [0|3] "" Central
 SG_ LC2_State__ELC_RE_BOT : 38|2@1+ (1,0) [0|3] "" Central
 SG_ BodyLift__ELC_FR_RAMP : 40|2@1+ (1,0) [0|3] "" Central
 SG_ RLF__ELC_RE_RAMP : 42|2@1+ (1,0) [0|3] "" Central
 SG_ TRI_ADL_A : 44|2@1+ (1,0) [0|3] "" Central
 SG_ TRI_ADL_B : 46|2@1+ (1,0) [0|3] "" Central
 SG_ TRI_ADL_C : 48|2@1+ (1,0) [0|3] "" Central
 SG_ TRI_ADL_D : 50|2@1+ (1,0) [0|3] "" Central
 SG_ TRI_REVERSE : 52|2@1+ (1,0) [0|3] "" Central
 SG_ LSP_SW : 54|2@1+ (1,0) [0|3] "" Central
 SG_ LSP_BU : 56|2@1+ (1,0) [0|3] "" Central
 SG_ TSR_BU : 58|2@1+ (1,0) [0|3] "" Central
 SG_ VSE_ID : 60|4@1+ (1,0) [0|15] "" Central

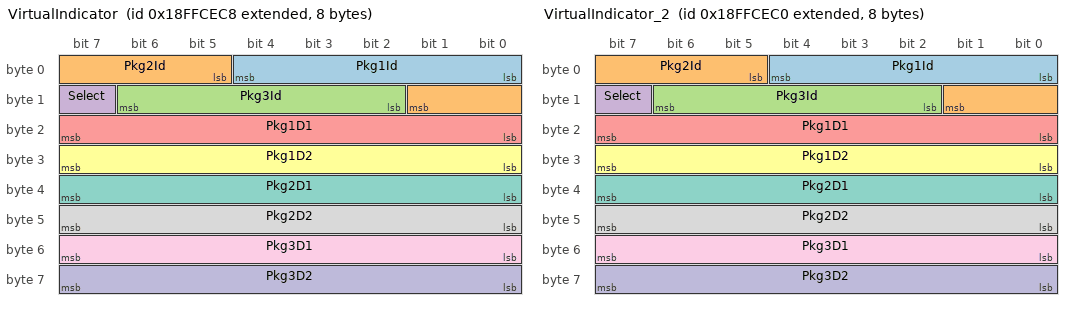
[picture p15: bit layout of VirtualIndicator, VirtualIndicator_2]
BO_ 2566901448 VirtualIndicator :8 Central
 SG_ Pkg1Id : 0|5@1+ (1,0) [0|31] "" Vector__XXX
 SG_ Pkg2Id : 5|5@1+ (1,0) [0|31] "" Vector__XXX
 SG_ Pkg3Id : 10|5@1+ (1,0) [0|31] "" Vector__XXX
 SG_ Select : 15|1@1+ (1,0) [0|1] "" Vector__XXX
 SG_ Pkg1D1 : 16|8@1+ (1,0) [0|255] "" Vector__XXX
 SG_ Pkg1D2 : 24|8@1+ (1,0) [0|255] "" Vector__XXX
 SG_ Pkg2D1 : 32|8@1+ (1,0) [0|255] "" Vector__XXX
 SG_ Pkg2D2 : 40|8@1+ (1,0) [0|255] "" Vector__XXX
 SG_ Pkg3D1 : 48|8@1+ (1,0) [0|255] "" Vector__XXX
 SG_ Pkg3D2 : 56|8@1+ (1,0) [0|255] "" Vector__XXX

BO_ 2566901440 VirtualIndicator_2 :8 CentralMulti
 SG_ Pkg1Id : 0|5@1+ (1,0) [0|31] "" Vector__XXX
 SG_ Pkg2Id : 5|5@1+ (1,0) [0|31] "" Vector__XXX
 SG_ Pkg3Id : 10|5@1+ (1,0) [0|31] "" Vector__XXX
 SG_ Select : 15|1@1+ (1,0) [0|1] "" Vector__XXX
 SG_ Pkg1D1 : 16|8@1+ (1,0) [0|255] "" Vector__XXX
 SG_ Pkg1D2 : 24|8@1+ (1,0) [0|255] "" Vector__XXX
 SG_ Pkg2D1 : 32|8@1+ (1,0) [0|255] "" Vector__XXX
 SG_ Pkg2D2 : 40|8@1+ (1,0) [0|255] "" Vector__XXX
 SG_ Pkg3D1 : 48|8@1+ (1,0) [0|255] "" Vector__XXX
 SG_ Pkg3D2 : 56|8@1+ (1,0) [0|255] "" Vector__XXX

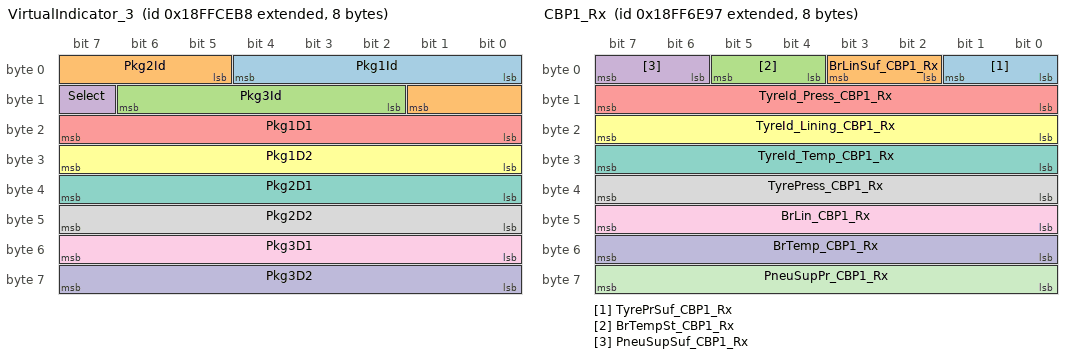
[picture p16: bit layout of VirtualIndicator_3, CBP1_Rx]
BO_ 2566901432 VirtualIndicator_3 :8 CentralMulti
 SG_ Pkg1Id : 0|5@1+ (1,0) [0|31] "" Vector__XXX
 SG_ Pkg2Id : 5|5@1+ (1,0) [0|31] "" Vector__XXX
 SG_ Pkg3Id : 10|5@1+ (1,0) [0|31] "" Vector__XXX
 SG_ Select : 15|1@1+ (1,0) [0|1] "" Vector__XXX
 SG_ Pkg1D1 : 16|8@1+ (1,0) [0|255] "" Vector__XXX
 SG_ Pkg1D2 : 24|8@1+ (1,0) [0|255] "" Vector__XXX
 SG_ Pkg2D1 : 32|8@1+ (1,0) [0|255] "" Vector__XXX
 SG_ Pkg2D2 : 40|8@1+ (1,0) [0|255] "" Vector__XXX
 SG_ Pkg3D1 : 48|8@1+ (1,0) [0|255] "" Vector__XXX
 SG_ Pkg3D2 : 56|8@1+ (1,0) [0|255] "" Vector__XXX

BO_ 2566901424 VirtualIndicator_4 :8 CentralMulti
 SG_ Pkg1Id : 0|5@1+ (1,0) [0|31] "" Vector__XXX
 SG_ Pkg2Id : 5|5@1+ (1,0) [0|31] "" Vector__XXX
 SG_ Pkg3Id : 10|5@1+ (1,0) [0|31] "" Vector__XXX
 SG_ Select : 15|1@1+ (1,0) [0|1] "" Vector__XXX
 SG_ Pkg1D1 : 16|8@1+ (1,0) [0|255] "" Vector__XXX
 SG_ Pkg1D2 : 24|8@1+ (1,0) [0|255] "" Vector__XXX
 SG_ Pkg2D1 : 32|8@1+ (1,0) [0|255] "" Vector__XXX
 SG_ Pkg2D2 : 40|8@1+ (1,0) [0|255] "" Vector__XXX
 SG_ Pkg3D1 : 48|8@1+ (1,0) [0|255] "" Vector__XXX
 SG_ Pkg3D2 : 56|8@1+ (1,0) [0|255] "" Vector__XXX

BO_ 2566901416 VirtualIndicator_5 :8 CentralMulti
 SG_ Pkg1Id : 0|5@1+ (1,0) [0|31] "" Vector__XXX
 SG_ Pkg2Id : 5|5@1+ (1,0) [0|31] "" Vector__XXX
 SG_ Pkg3Id : 10|5@1+ (1,0) [0|31] "" Vector__XXX
 SG_ Select : 15|1@1+ (1,0) [0|1] "" Vector__XXX
 SG_ Pkg1D1 : 16|8@1+ (1,0) [0|255] "" Vector__XXX
 SG_ Pkg1D2 : 24|8@1+ (1,0) [0|255] "" Vector__XXX
 SG_ Pkg2D1 : 32|8@1+ (1,0) [0|255] "" Vector__XXX
 SG_ Pkg2D2 : 40|8@1+ (1,0) [0|255] "" Vector__XXX
 SG_ Pkg3D1 : 48|8@1+ (1,0) [0|255] "" Vector__XXX
 SG_ Pkg3D2 : 56|8@1+ (1,0) [0|255] "" Vector__XXX

BO_ 2566901408 VirtualIndicator_6 :8 CentralMulti
 SG_ Pkg1Id : 0|5@1+ (1,0) [0|31] "" Vector__XXX
 SG_ Pkg2Id : 5|5@1+ (1,0) [0|31] "" Vector__XXX
 SG_ Pkg3Id : 10|5@1+ (1,0) [0|31] "" Vector__XXX
 SG_ Select : 15|1@1+ (1,0) [0|1] "" Vector__XXX
 SG_ Pkg1D1 : 16|8@1+ (1,0) [0|255] "" Vector__XXX
 SG_ Pkg1D2 : 24|8@1+ (1,0) [0|255] "" Vector__XXX
 SG_ Pkg2D1 : 32|8@1+ (1,0) [0|255] "" Vector__XXX
 SG_ Pkg2D2 : 40|8@1+ (1,0) [0|255] "" Vector__XXX
 SG_ Pkg3D1 : 48|8@1+ (1,0) [0|255] "" Vector__XXX
 SG_ Pkg3D2 : 56|8@1+ (1,0) [0|255] "" Vector__XXX

BO_ 2566901400 VirtualIndicator_7 :8 CentralMulti
 SG_ Pkg1Id : 0|5@1+ (1,0) [0|31] "" Vector__XXX
 SG_ Pkg2Id : 5|5@1+ (1,0) [0|31] "" Vector__XXX
 SG_ Pkg3Id : 10|5@1+ (1,0) [0|31] "" Vector__XXX
 SG_ Select : 15|1@1+ (1,0) [0|1] "" Vector__XXX
 SG_ Pkg1D1 : 16|8@1+ (1,0) [0|255] "" Vector__XXX
 SG_ Pkg1D2 : 24|8@1+ (1,0) [0|255] "" Vector__XXX
 SG_ Pkg2D1 : 32|8@1+ (1,0) [0|255] "" Vector__XXX
 SG_ Pkg2D2 : 40|8@1+ (1,0) [0|255] "" Vector__XXX
 SG_ Pkg3D1 : 48|8@1+ (1,0) [0|255] "" Vector__XXX
 SG_ Pkg3D2 : 56|8@1+ (1,0) [0|255] "" Vector__XXX

BO_ 2566901392 VirtualIndicator_8 :8 CentralMulti
 SG_ Pkg1Id : 0|5@1+ (1,0) [0|31] "" Vector__XXX
 SG_ Pkg2Id : 5|5@1+ (1,0) [0|31] "" Vector__XXX
 SG_ Pkg3Id : 10|5@1+ (1,0) [0|31] "" Vector__XXX
 SG_ Select : 15|1@1+ (1,0) [0|1] "" Vector__XXX
 SG_ Pkg1D1 : 16|8@1+ (1,0) [0|255] "" Vector__XXX
 SG_ Pkg1D2 : 24|8@1+ (1,0) [0|255] "" Vector__XXX
 SG_ Pkg2D1 : 32|8@1+ (1,0) [0|255] "" Vector__XXX
 SG_ Pkg2D2 : 40|8@1+ (1,0) [0|255] "" Vector__XXX
 SG_ Pkg3D1 : 48|8@1+ (1,0) [0|255] "" Vector__XXX
 SG_ Pkg3D2 : 56|8@1+ (1,0) [0|255] "" Vector__XXX

BO_ 2566901384 VirtualIndicator_9 :8 CentralMulti
 SG_ Pkg1Id : 0|5@1+ (1,0) [0|31] "" Vector__XXX
 SG_ Pkg2Id : 5|5@1+ (1,0) [0|31] "" Vector__XXX
 SG_ Pkg3Id : 10|5@1+ (1,0) [0|31] "" Vector__XXX
 SG_ Select : 15|1@1+ (1,0) [0|1] "" Vector__XXX
 SG_ Pkg1D1 : 16|8@1+ (1,0) [0|255] "" Vector__XXX
 SG_ Pkg1D2 : 24|8@1+ (1,0) [0|255] "" Vector__XXX
 SG_ Pkg2D1 : 32|8@1+ (1,0) [0|255] "" Vector__XXX
 SG_ Pkg2D2 : 40|8@1+ (1,0) [0|255] "" Vector__XXX
 SG_ Pkg3D1 : 48|8@1+ (1,0) [0|255] "" Vector__XXX
 SG_ Pkg3D2 : 56|8@1+ (1,0) [0|255] "" Vector__XXX

BO_ 2566901376 VirtualIndicator_10 :8 CentralMulti
 SG_ Pkg1Id : 0|5@1+ (1,0) [0|31] "" Vector__XXX
 SG_ Pkg2Id : 5|5@1+ (1,0) [0|31] "" Vector__XXX
 SG_ Pkg3Id : 10|5@1+ (1,0) [0|31] "" Vector__XXX
 SG_ Select : 15|1@1+ (1,0) [0|1] "" Vector__XXX
 SG_ Pkg1D1 : 16|8@1+ (1,0) [0|255] "" Vector__XXX
 SG_ Pkg1D2 : 24|8@1+ (1,0) [0|255] "" Vector__XXX
 SG_ Pkg2D1 : 32|8@1+ (1,0) [0|255] "" Vector__XXX
 SG_ Pkg2D2 : 40|8@1+ (1,0) [0|255] "" Vector__XXX
 SG_ Pkg3D1 : 48|8@1+ (1,0) [0|255] "" Vector__XXX
 SG_ Pkg3D2 : 56|8@1+ (1,0) [0|255] "" Vector__XXX

BO_ 2566876823 CBP1_Rx :8 CTU
 SG_ TyrePrSuf_CBP1_Rx : 0|2@1+ (1,0) [0|3] "" Central
 SG_ BrLinSuf_CBP1_Rx : 2|2@1+ (1,0) [0|3] "" Central
 SG_ BrTempSt_CBP1_Rx : 4|2@1+ (1,0) [0|3] "" Central
 SG_ PneuSupSuf_CBP1_Rx : 6|2@1+ (1,0) [0|3] "" Central
 SG_ TyreId_Press_CBP1_Rx : 8|8@1+ (1,0) [0|255] "" Central
 SG_ TyreId_Lining_CBP1_Rx : 16|8@1+ (1,0) [0|255] "" Central
 SG_ TyreId_Temp_CBP1_Rx : 24|8@1+ (1,0) [0|255] "" Central
 SG_ TyrePress_CBP1_Rx : 32|8@1+ (0.1,0) [0|255] "bar" Central
 SG_ BrLin_CBP1_Rx : 40|8@1+ (0.4,0) [0|255] "%" Central
 SG_ BrTemp_CBP1_Rx : 48|8@1+ (10,0) [0|255] "C" Central
 SG_ PneuSupPr_CBP1_Rx : 56|8@1+ (0.05,0) [0|255] "bar" Central

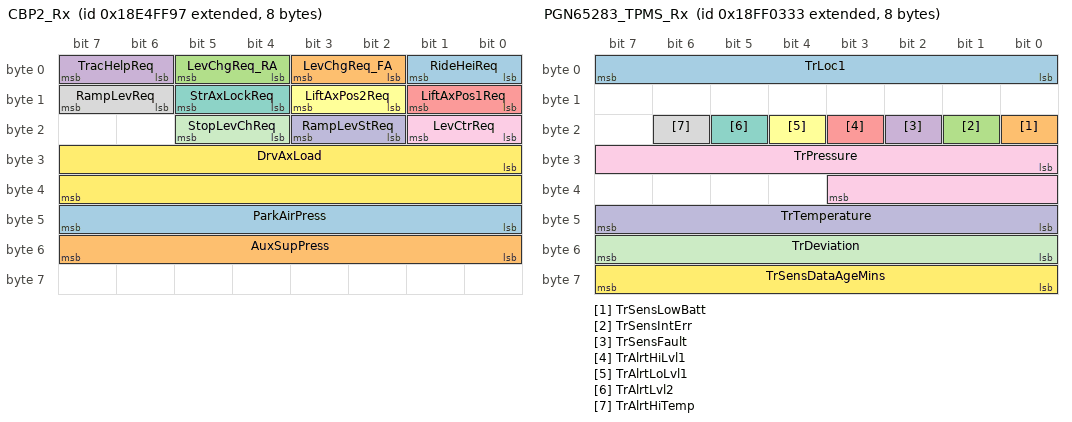
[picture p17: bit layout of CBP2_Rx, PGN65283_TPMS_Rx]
BO_ 2565144471 CBP2_Rx :8 CTU
 SG_ RideHeiReq : 0|2@1+ (1,0) [0|3] "" Central
 SG_ LevChgReq_FA : 2|2@1+ (1,0) [0|3] "" Central
 SG_ LevChgReq_RA : 4|2@1+ (1,0) [0|3] "" Central
 SG_ TracHelpReq : 6|2@1+ (1,0) [0|3] "" Central
 SG_ LiftAxPos1Req : 8|2@1+ (1,0) [0|3] "" Central
 SG_ LiftAxPos2Req : 10|2@1+ (1,0) [0|3] "" Central
 SG_ StrAxLockReq : 12|2@1+ (1,0) [0|3] "" Central
 SG_ RampLevReq : 14|2@1+ (1,0) [0|3] "" Central
 SG_ LevCtrReq : 16|2@1+ (1,0) [0|3] "" Central
 SG_ RampLevStReq : 18|2@1+ (1,0) [0|3] "" Central
 SG_ StopLevChReq : 20|2@1+ (1,0) [0|3] "" Central
 SG_ DrvAxLoad : 24|16@1+ (2,0) [0|65535] "kg" Central
 SG_ ParkAirPress : 40|8@1+ (80,0) [0|255] "mbar" Central
 SG_ AuxSupPress : 48|8@1+ (80,0) [0|255] "mbar" Central

BO_ 2566900787 TPMS1_Rx :8 TPMS
 SG_ TrPos1 : 0|8@1+ (1,0) [0|255] "" Central
 SG_ TrPress1 : 8|8@1+ (1,0) [0|255] "" Central
 SG_ TrTemp1 : 16|16@1+ (1,0) [0|65535] "" Central
 SG_ TrPDev1 : 32|8@1+ (1,0) [0|255] "" Central
 SG_ TrFltMap1 : 40|8@1+ (1,0) [0|255] "" Central

BO_ 2566901043 TPMS2_Rx :8 TPMS
 SG_ TrPos2 : 0|8@1+ (1,0) [0|255] "" Central
 SG_ TrPress2 : 8|8@1+ (1,0) [0|255] "" Central
 SG_ TrTemp2 : 16|8@1+ (1,0) [0|255] "" Central
 SG_ TrPDev2 : 24|8@1+ (1,0) [0|255] "" Central
 SG_ TrFltMap2 : 32|8@1+ (1,0) [0|255] "" Central

BO_ 2566849331 PGN65283_TPMS_Rx :8 TPMS
 SG_ TrLoc1 : 0|8@1+ (1,0) [0|255] "" Central
 SG_ TrSensLowBatt : 16|1@1+ (1,0) [0|1] "" Central
 SG_ TrSensIntErr : 17|1@1+ (1,0) [0|1] "" Central
 SG_ TrSensFault : 18|1@1+ (1,0) [0|1] "" Central
 SG_ TrAlrtHiLvl1 : 19|1@1+ (1,0) [0|1] "" Central
 SG_ TrAlrtLoLvl1 : 20|1@1+ (1,0) [0|1] "" Central
 SG_ TrAlrtLvl2 : 21|1@1+ (1,0) [0|1] "" Central
 SG_ TrAlrtHiTemp : 22|1@1+ (1,0) [0|1] "" Central
 SG_ TrPressure : 24|12@1+ (1,0) [0|4095] "" Central
 SG_ TrTemperature : 40|8@1+ (1,0) [0|255] "" Central
 SG_ TrDeviation : 48|8@1+ (1,0) [0|255] "" Central
 SG_ TrSensDataAgeMins : 56|8@1+ (1,0) [0|255] "" Central

BO_ 2566845491 PGN65268_TPMS_Rx :8 TPMS
 SG_ TrData0 : 0|8@1+ (1,0) [0|255] "" Central
 SG_ TrData1 : 8|8@1+ (1,0) [0|255] "" Central
 SG_ TrData2 : 16|8@1+ (1,0) [0|255] "" Central
 SG_ TrData3 : 24|8@1+ (1,0) [0|255] "" Central
 SG_ TrData4 : 32|8@1+ (1,0) [0|255] "" Central
 SG_ TrData5 : 40|8@1+ (1,0) [0|255] "" Central
 SG_ TrData6 : 48|8@1+ (1,0) [0|255] "" Central
 SG_ TrData7 : 56|8@1+ (1,0) [0|255] "" Central

BO_ 385 Sens1CANopen_Rx :4 SensorCANopen
 SG_ CANopenPr : 0|32@1+ (1,0) [0|4294967295] "" Central

BO_ 129 Sens1CANopen_Err_Rx :8 SensorCANopen
 SG_ CANopenErr : 0|64@1+ (1,0) [0|0] "" Central

BO_ 2499780643 ADP_Capability_Rx :8 Aux_Device
 SG_ P0_CapMask : 0|8@1+ (1,0) [0|255] "" Central
 SG_ P1_CapMask : 8|8@1+ (1,0) [0|255] "" Central
 SG_ P2_CapMask : 16|8@1+ (1,0) [0|255] "" Central
 SG_ P3_CapMask : 24|8@1+ (1,0) [0|255] "" Central
 SG_ P4_CapMask : 32|8@1+ (1,0) [0|255] "" Central
 SG_ P5_CapMask : 40|8@1+ (1,0) [0|255] "" Central
 SG_ P6_CapMask : 48|8@1+ (1,0) [0|255] "" Central
 SG_ iCapSet : 56|4@1+ (1,0) [0|15] "" Central
 SG_ MaxCapSet : 60|4@1+ (1,0) [0|15] "" Central

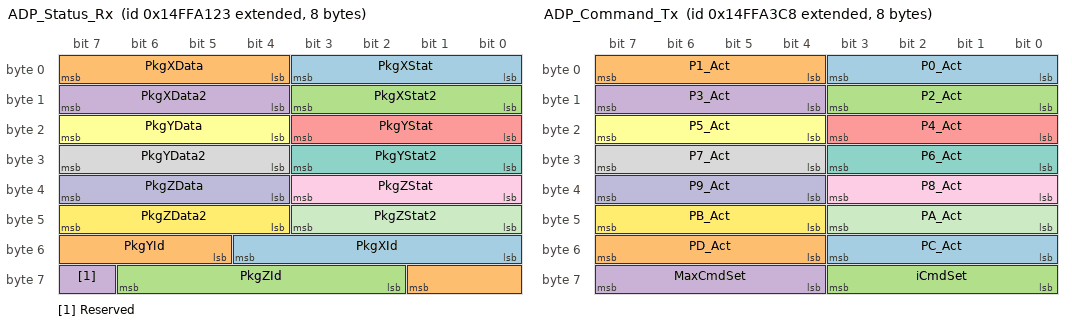
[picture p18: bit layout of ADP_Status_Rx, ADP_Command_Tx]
BO_ 2499780899 ADP_Status_Rx :8 Aux_Device
 SG_ PkgXStat : 0|4@1+ (1,0) [0|15] "" Central
 SG_ PkgXData : 4|4@1+ (1,0) [0|15] "" Central
 SG_ PkgXStat2 : 8|4@1+ (1,0) [0|15] "" Central
 SG_ PkgXData2 : 12|4@1+ (1,0) [0|15] "" Central
 SG_ PkgYStat : 16|4@1+ (1,0) [0|15] "" Central
 SG_ PkgYData : 20|4@1+ (1,0) [0|15] "" Central
 SG_ PkgYStat2 : 24|4@1+ (1,0) [0|15] "" Central
 SG_ PkgYData2 : 28|4@1+ (1,0) [0|15] "" Central
 SG_ PkgZStat : 32|4@1+ (1,0) [0|15] "" Central
 SG_ PkgZData : 36|4@1+ (1,0) [0|15] "" Central
 SG_ PkgZStat2 : 40|4@1+ (1,0) [0|15] "" Central
 SG_ PkgZData2 : 44|4@1+ (1,0) [0|15] "" Central
 SG_ PkgXId : 48|5@1+ (1,0) [0|31] "" Central
 SG_ PkgYId : 53|5@1+ (1,0) [0|31] "" Central
 SG_ PkgZId : 58|5@1+ (1,0) [0|31] "" Central
 SG_ Reserved : 63|1@1+ (1,0) [0|1] "" Central

BO_ 2499781320 ADP_Config_Tx :8 Central
 SG_ P0_IOin : 0|1@1+ (1,0) [0|1] "" Vector__XXX
 SG_ P0_Mode : 1|2@1+ (1,0) [0|3] "" Vector__XXX
 SG_ P0_Ath_PWM : 3|2@1+ (1,0) [0|3] "" Vector__XXX
 SG_ P0_Ath_Cap : 5|1@1+ (1,0) [0|1] "" Vector__XXX
 SG_ P0_Ngnd_OC : 6|1@1+ (1,0) [0|1] "" Vector__XXX
 SG_ P0_Nsup_Stim : 7|1@1+ (1,0) [0|1] "" Vector__XXX
 SG_ P1_IOin : 8|1@1+ (1,0) [0|1] "" Vector__XXX
 SG_ P1_Mode : 9|2@1+ (1,0) [0|3] "" Vector__XXX
 SG_ P1_Ath_PWM : 11|2@1+ (1,0) [0|3] "" Vector__XXX
 SG_ P1_Ath_Cap : 13|1@1+ (1,0) [0|1] "" Vector__XXX
 SG_ P1_Ngnd_OC : 14|1@1+ (1,0) [0|1] "" Vector__XXX
 SG_ P1_Nsup_Stim : 15|1@1+ (1,0) [0|1] "" Vector__XXX
 SG_ P2_IOin : 16|1@1+ (1,0) [0|1] "" Vector__XXX
 SG_ P2_Mode : 17|2@1+ (1,0) [0|3] "" Vector__XXX
 SG_ P2_Ath_PWM : 19|2@1+ (1,0) [0|3] "" Vector__XXX
 SG_ P2_Ath_Cap : 21|1@1+ (1,0) [0|1] "" Vector__XXX
 SG_ P2_Ngnd_OC : 22|1@1+ (1,0) [0|1] "" Vector__XXX
 SG_ P2_Nsup_Stim : 23|1@1+ (1,0) [0|1] "" Vector__XXX
 SG_ P3_IOin : 24|1@1+ (1,0) [0|1] "" Vector__XXX
 SG_ P3_Mode : 25|2@1+ (1,0) [0|3] "" Vector__XXX
 SG_ P3_Ath_PWM : 27|2@1+ (1,0) [0|3] "" Vector__XXX
 SG_ P3_Ath_Cap : 29|1@1+ (1,0) [0|1] "" Vector__XXX
 SG_ P3_Ngnd_OC : 30|1@1+ (1,0) [0|1] "" Vector__XXX
 SG_ P3_Nsup_Stim : 31|1@1+ (1,0) [0|1] "" Vector__XXX
 SG_ P4_IOin : 32|1@1+ (1,0) [0|1] "" Vector__XXX
 SG_ P4_Mode : 33|2@1+ (1,0) [0|3] "" Vector__XXX
 SG_ P4_Ath_PWM : 35|2@1+ (1,0) [0|3] "" Vector__XXX
 SG_ P4_Ath_Cap : 37|1@1+ (1,0) [0|1] "" Vector__XXX
 SG_ P4_Ngnd_OC : 38|1@1+ (1,0) [0|1] "" Vector__XXX
 SG_ P4_Nsup_Stim : 39|1@1+ (1,0) [0|1] "" Vector__XXX
 SG_ P5_IOin : 40|1@1+ (1,0) [0|1] "" Vector__XXX
 SG_ P5_Mode : 41|2@1+ (1,0) [0|3] "" Vector__XXX
 SG_ P5_Ath_PWM : 43|2@1+ (1,0) [0|3] "" Vector__XXX
 SG_ P5_Ath_Cap : 45|1@1+ (1,0) [0|1] "" Vector__XXX
 SG_ P5_Ngnd_OC : 46|1@1+ (1,0) [0|1] "" Vector__XXX
 SG_ P5_Nsup_Stim : 47|1@1+ (1,0) [0|1] "" Vector__XXX
 SG_ P6_IOin : 48|1@1+ (1,0) [0|1] "" Vector__XXX
 SG_ P6_Mode : 49|2@1+ (1,0) [0|3] "" Vector__XXX
 SG_ P6_Ath_PWM : 51|2@1+ (1,0) [0|3] "" Vector__XXX
 SG_ P6_Ath_Cap : 53|1@1+ (1,0) [0|1] "" Vector__XXX
 SG_ P6_Ngnd_OC : 54|1@1+ (1,0) [0|1] "" Vector__XXX
 SG_ P6_Nsup_Stim : 55|1@1+ (1,0) [0|1] "" Vector__XXX
 SG_ iConfSet : 56|4@1+ (1,0) [0|15] "" Vector__XXX
 SG_ MaxConfSet : 60|4@1+ (1,0) [0|15] "" Vector__XXX

BO_ 2499781576 ADP_Command_Tx :8 Central
 SG_ P0_Act : 0|4@1+ (1,0) [0|15] "" Vector__XXX
 SG_ P1_Act : 4|4@1+ (1,0) [0|15] "" Vector__XXX
 SG_ P2_Act : 8|4@1+ (1,0) [0|15] "" Vector__XXX
 SG_ P3_Act : 12|4@1+ (1,0) [0|15] "" Vector__XXX
 SG_ P4_Act : 16|4@1+ (1,0) [0|15] "" Vector__XXX
 SG_ P5_Act : 20|4@1+ (1,0) [0|15] "" Vector__XXX
 SG_ P6_Act : 24|4@1+ (1,0) [0|15] "" Vector__XXX
 SG_ P7_Act : 28|4@1+ (1,0) [0|15] "" Vector__XXX
 SG_ P8_Act : 32|4@1+ (1,0) [0|15] "" Vector__XXX
 SG_ P9_Act : 36|4@1+ (1,0) [0|15] "" Vector__XXX
 SG_ PA_Act : 40|4@1+ (1,0) [0|15] "" Vector__XXX
 SG_ PB_Act : 44|4@1+ (1,0) [0|15] "" Vector__XXX
 SG_ PC_Act : 48|4@1+ (1,0) [0|15] "" Vector__XXX
 SG_ PD_Act : 52|4@1+ (1,0) [0|15] "" Vector__XXX
 SG_ iCmdSet : 56|4@1+ (1,0) [0|15] "" Vector__XXX
 SG_ MaxCmdSet : 60|4@1+ (1,0) [0|15] "" Vector__XXX

BO_ 2499781667 ADP_Capability_iTEPM_Rx :8 iTEPM
 SG_ CRC_E2E : 0|8@1+ (1,0) [0|255] "" Central
 SG_ Counter_E2E : 8|4@1+ (1,0) [0|15] "" Central
 SG_ MaxCapSet : 12|4@1+ (1,0) [0|15] "" Central
 SG_ P0_CapMask : 16|8@1+ (1,0) [0|255] "" Central
 SG_ P1_CapMask : 24|8@1+ (1,0) [0|255] "" Central
 SG_ P2_CapMask : 32|8@1+ (1,0) [0|255] "" Central
 SG_ P3_CapMask : 40|8@1+ (1,0) [0|255] "" Central
 SG_ P4_CapMask : 48|8@1+ (1,0) [0|255] "" Central
 SG_ iCapSet : 60|4@1+ (1,0) [0|15] "" Central

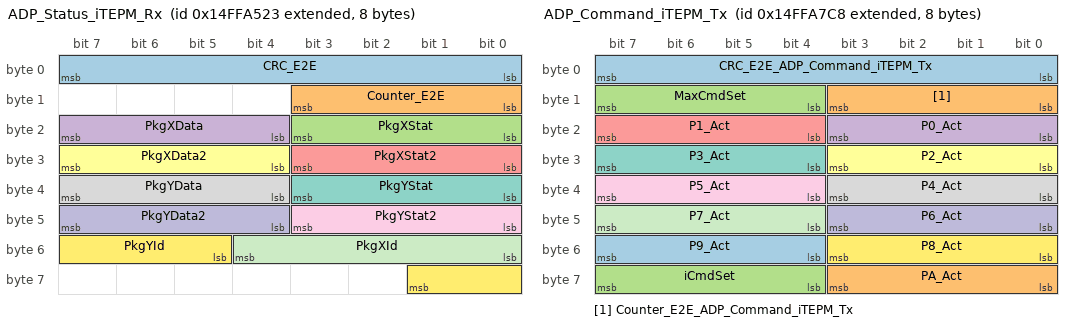
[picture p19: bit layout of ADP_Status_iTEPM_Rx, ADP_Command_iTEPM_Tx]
BO_ 2499781923 ADP_Status_iTEPM_Rx :8 iTEPM
 SG_ CRC_E2E : 0|8@1+ (1,0) [0|255] "" Central
 SG_ Counter_E2E : 8|4@1+ (1,0) [0|15] "" Central
 SG_ PkgXStat : 16|4@1+ (1,0) [0|15] "" Central
 SG_ PkgXData : 20|4@1+ (1,0) [0|15] "" Central
 SG_ PkgXStat2 : 24|4@1+ (1,0) [0|15] "" Central
 SG_ PkgXData2 : 28|4@1+ (1,0) [0|15] "" Central
 SG_ PkgYStat : 32|4@1+ (1,0) [0|15] "" Central
 SG_ PkgYData : 36|4@1+ (1,0) [0|15] "" Central
 SG_ PkgYStat2 : 40|4@1+ (1,0) [0|15] "" Central
 SG_ PkgYData2 : 44|4@1+ (1,0) [0|15] "" Central
 SG_ PkgXId : 48|5@1+ (1,0) [0|31] "" Central
 SG_ PkgYId : 53|5@1+ (1,0) [0|31] "" Central

BO_ 2499782344 ADP_Config_iTEPM_Tx :8 Central
 SG_ CRC_E2E_ADP_Config_iTEPM_Tx : 0|8@1+ (1,0) [0|255] "" iTEPM
 SG_ Counter_E2E_ADP_Config_iTEPM_Tx : 8|4@1+ (1,0) [0|15] "" iTEPM
 SG_ MaxConfSet : 12|4@1+ (1,0) [0|15] "" iTEPM
 SG_ P0_IOin : 16|1@1+ (1,0) [0|1] "" iTEPM
 SG_ P0_Mode : 17|2@1+ (1,0) [0|3] "" iTEPM
 SG_ P0_Ath_PWM : 19|2@1+ (1,0) [0|3] "" iTEPM
 SG_ P0_Ath_Cap : 21|1@1+ (1,0) [0|1] "" iTEPM
 SG_ P0_Ngnd_OC : 22|1@1+ (1,0) [0|1] "" iTEPM
 SG_ P0_Nsup_Stim : 23|1@1+ (1,0) [0|1] "" iTEPM
 SG_ P1_IOin : 24|1@1+ (1,0) [0|1] "" iTEPM
 SG_ P1_Mode : 25|2@1+ (1,0) [0|3] "" iTEPM
 SG_ P1_Ath_PWM : 27|2@1+ (1,0) [0|3] "" iTEPM
 SG_ P1_Ath_Cap : 29|1@1+ (1,0) [0|1] "" iTEPM
 SG_ P1_Ngnd_OC : 30|1@1+ (1,0) [0|1] "" iTEPM
 SG_ P1_Nsup_Stim : 31|1@1+ (1,0) [0|1] "" iTEPM
 SG_ P2_IOin : 32|1@1+ (1,0) [0|1] "" iTEPM
 SG_ P2_Mode : 33|2@1+ (1,0) [0|3] "" iTEPM
 SG_ P2_Ath_PWM : 35|2@1+ (1,0) [0|3] "" iTEPM
 SG_ P2_Ath_Cap : 37|1@1+ (1,0) [0|1] "" iTEPM
 SG_ P2_Ngnd_OC : 38|1@1+ (1,0) [0|1] "" iTEPM
 SG_ P2_Nsup_Stim : 39|1@1+ (1,0) [0|1] "" iTEPM
 SG_ P3_IOin : 40|1@1+ (1,0) [0|1] "" iTEPM
 SG_ P3_Mode : 41|2@1+ (1,0) [0|3] "" iTEPM
 SG_ P3_Ath_PWM : 43|2@1+ (1,0) [0|3] "" iTEPM
 SG_ P3_Ath_Cap : 45|1@1+ (1,0) [0|1] "" iTEPM
 SG_ P3_Ngnd_OC : 46|1@1+ (1,0) [0|1] "" iTEPM
 SG_ P3_Nsup_Stim : 47|1@1+ (1,0) [0|1] "" iTEPM
 SG_ P4_IOin : 48|1@1+ (1,0) [0|1] "" iTEPM
 SG_ P4_Mode : 49|2@1+ (1,0) [0|3] "" iTEPM
 SG_ P4_Ath_PWM : 51|2@1+ (1,0) [0|3] "" iTEPM
 SG_ P4_Ath_Cap : 53|1@1+ (1,0) [0|1] "" iTEPM
 SG_ P4_Ngnd_OC : 54|1@1+ (1,0) [0|1] "" iTEPM
 SG_ P4_Nsup_Stim : 55|1@1+ (1,0) [0|1] "" iTEPM
 SG_ iConfSet : 60|4@1+ (1,0) [0|15] "" iTEPM

BO_ 2499782600 ADP_Command_iTEPM_Tx :8 Central
 SG_ CRC_E2E_ADP_Command_iTEPM_Tx : 0|8@1+ (1,0) [0|255] "" iTEPM
 SG_ Counter_E2E_ADP_Command_iTEPM_Tx : 8|4@1+ (1,0) [0|15] "" iTEPM
 SG_ MaxCmdSet : 12|4@1+ (1,0) [0|15] "" iTEPM
 SG_ P0_Act : 16|4@1+ (1,0) [0|15] "" iTEPM
 SG_ P1_Act : 20|4@1+ (1,0) [0|15] "" iTEPM
 SG_ P2_Act : 24|4@1+ (1,0) [0|15] "" iTEPM
 SG_ P3_Act : 28|4@1+ (1,0) [0|15] "" iTEPM
 SG_ P4_Act : 32|4@1+ (1,0) [0|15] "" iTEPM
 SG_ P5_Act : 36|4@1+ (1,0) [0|15] "" iTEPM
 SG_ P6_Act : 40|4@1+ (1,0) [0|15] "" iTEPM
 SG_ P7_Act : 44|4@1+ (1,0) [0|15] "" iTEPM
 SG_ P8_Act : 48|4@1+ (1,0) [0|15] "" iTEPM
 SG_ P9_Act : 52|4@1+ (1,0) [0|15] "" iTEPM
 SG_ PA_Act : 56|4@1+ (1,0) [0|15] "" iTEPM
 SG_ iCmdSet : 60|4@1+ (1,0) [0|15] "" iTEPM

BO_ 2560726795 EncryptedDataTEBS :8 Central
 SG_ EncrDataTEBS : 0|64@1+ (1,0) [0|0] "" Vector__XXX

BO_ 2560691095 EncryptedDataCTU :8 CTU
 SG_ EncrDataCTU : 0|64@1+ (1,0) [0|0] "" Central

BA_DEF_ BO_ "DiagConnection" INT 0 65535;
BA_DEF_ BO_ "DiagRequest" ENUM "No","Yes";
BA_DEF_ BO_ "DiagResponse" ENUM "No","Yes";
BA_DEF_ BO_ "GenMsgCycleTime" INT 0 3600000;
BA_DEF_ BO_ "GenMsgILSupport" ENUM "No","Yes";
BA_DEF_ BO_ "GenMsgRequestable" INT 0 1;
BA_DEF_ BO_ "GenMsgSendType" ENUM "cyclic","NotUsed","NotUsed","NotUsed","NotUsed","NotUsed","NotUsed","IfActive","noMsgSendType";
BA_DEF_ BO_ "VFrameFormat" ENUM "StandardCAN","ExtendedCAN","reserved","J1939PG";
BA_DEF_ SG_ "GenSigCycleTime" INT 0 4294967295;
BA_DEF_ SG_ "GenSigEVName" STRING ;
BA_DEF_ SG_ "GenSigILSupport" ENUM "No","Yes";
BA_DEF_ SG_ "GenSigInactiveValue" INT 0 4294967295;
BA_DEF_ SG_ "GenSigSendType" ENUM "Cyclic","OnWrite","OnWriteWithRepetition","OnChange","OnChangeWithRepetition","IfActive","IfActiveWithRepetition","NoSigSendType";
BA_DEF_ SG_ "GenSigStartValue" INT 0 4294967295;
BA_DEF_ SG_ "SigType" ENUM "Default","Range","RangeSigned","ASCII","Discrete","Control","ReferencePGN","DTC","StringDelimiter","StringLength","StringLengthControl";
BA_DEF_DEF_ "DiagConnection" 0;
BA_DEF_DEF_ "DiagRequest" "No";
BA_DEF_DEF_ "DiagResponse" "No";
BA_DEF_DEF_ "GenMsgCycleTime" 0;
BA_DEF_DEF_ "GenMsgILSupport" "Yes";
BA_DEF_DEF_ "GenMsgRequestable" 1;
BA_DEF_DEF_ "GenMsgSendType" "noMsgSendType";
BA_DEF_DEF_ "VFrameFormat" "J1939PG";
BA_DEF_DEF_ "GenSigCycleTime" 0;
BA_DEF_DEF_ "GenSigEVName" "Env@Nodename_@Signame";
BA_DEF_DEF_ "GenSigILSupport" "Yes";
BA_DEF_DEF_ "GenSigInactiveValue" 0;
BA_DEF_DEF_ "GenSigSendType" "NoSigSendType";
BA_DEF_DEF_ "GenSigStartValue" 0;
BA_DEF_DEF_ "SigType" "Default";
BA_ "VFrameFormat" BO_ 2566805936 1;
BA_ "GenSigInactiveValue" SG_ 2566805936 VehicleLevelFrontLeft 32000;
BA_ "GenSigStartValue" SG_ 2566805936 VehicleLevelFrontLeft 32000;
BA_ "GenSigSendType" SG_ 2566805936 VehicleLevelFrontLeft 1;
BA_ "GenSigInactiveValue" SG_ 2566805936 VehicleLevelFrontRight 32000;
BA_ "GenSigStartValue" SG_ 2566805936 VehicleLevelFrontRight 32000;
BA_ "GenSigSendType" SG_ 2566805936 VehicleLevelFrontRight 1;
BA_ "GenSigInactiveValue" SG_ 2566805936 VehicleLevelRearLeft 32000;
BA_ "GenSigStartValue" SG_ 2566805936 VehicleLevelRearLeft 32000;
BA_ "GenSigSendType" SG_ 2566805936 VehicleLevelRearLeft 1;
BA_ "GenSigInactiveValue" SG_ 2566805936 VehicleLevelRearRight 32000;
BA_ "GenSigStartValue" SG_ 2566805936 VehicleLevelRearRight 32000;
BA_ "GenSigSendType" SG_ 2566805936 VehicleLevelRearRight 1;
BA_ "VFrameFormat" BO_ 2566805928 1;
BA_ "GenSigInactiveValue" SG_ 2566805928 VehicleLevelFrontLeft 32000;
BA_ "GenSigStartValue" SG_ 2566805928 VehicleLevelFrontLeft 32000;
BA_ "GenSigSendType" SG_ 2566805928 VehicleLevelFrontLeft 1;
BA_ "GenSigInactiveValue" SG_ 2566805928 VehicleLevelFrontRight 32000;
BA_ "GenSigStartValue" SG_ 2566805928 VehicleLevelFrontRight 32000;
BA_ "GenSigSendType" SG_ 2566805928 VehicleLevelFrontRight 1;
BA_ "GenSigInactiveValue" SG_ 2566805928 VehicleLevelRearLeft 32000;
BA_ "GenSigStartValue" SG_ 2566805928 VehicleLevelRearLeft 32000;
BA_ "GenSigSendType" SG_ 2566805928 VehicleLevelRearLeft 1;
BA_ "GenSigInactiveValue" SG_ 2566805928 VehicleLevelRearRight 32000;
BA_ "GenSigStartValue" SG_ 2566805928 VehicleLevelRearRight 32000;
BA_ "GenSigSendType" SG_ 2566805928 VehicleLevelRearRight 1;
BA_ "VFrameFormat" BO_ 2566805920 1;
BA_ "GenSigInactiveValue" SG_ 2566805920 VehicleLevelFrontLeft 32000;
BA_ "GenSigStartValue" SG_ 2566805920 VehicleLevelFrontLeft 32000;
BA_ "GenSigSendType" SG_ 2566805920 VehicleLevelFrontLeft 1;
BA_ "GenSigInactiveValue" SG_ 2566805920 VehicleLevelFrontRight 32000;
BA_ "GenSigStartValue" SG_ 2566805920 VehicleLevelFrontRight 32000;
BA_ "GenSigSendType" SG_ 2566805920 VehicleLevelFrontRight 1;
BA_ "GenSigInactiveValue" SG_ 2566805920 VehicleLevelRearLeft 32000;
BA_ "GenSigStartValue" SG_ 2566805920 VehicleLevelRearLeft 32000;
BA_ "GenSigSendType" SG_ 2566805920 VehicleLevelRearLeft 1;
BA_ "GenSigInactiveValue" SG_ 2566805920 VehicleLevelRearRight 32000;
BA_ "GenSigStartValue" SG_ 2566805920 VehicleLevelRearRight 32000;
BA_ "GenSigSendType" SG_ 2566805920 VehicleLevelRearRight 1;
BA_ "VFrameFormat" BO_ 2173691288 1;
BA_ "GenSigInactiveValue" SG_ 2173691288 VehicleLevelFrontLeft 32000;
BA_ "GenSigStartValue" SG_ 2173691288 VehicleLevelFrontLeft 32000;
BA_ "GenSigSendType" SG_ 2173691288 VehicleLevelFrontLeft 1;
BA_ "GenSigInactiveValue" SG_ 2173691288 VehicleLevelFrontRight 32000;
BA_ "GenSigStartValue" SG_ 2173691288 VehicleLevelFrontRight 32000;
BA_ "GenSigSendType" SG_ 2173691288 VehicleLevelFrontRight 1;
BA_ "GenSigInactiveValue" SG_ 2173691288 VehicleLevelRearLeft 32000;
BA_ "GenSigStartValue" SG_ 2173691288 VehicleLevelRearLeft 32000;
BA_ "GenSigSendType" SG_ 2173691288 VehicleLevelRearLeft 1;
BA_ "GenSigInactiveValue" SG_ 2173691288 VehicleLevelRearRight 32000;
BA_ "GenSigStartValue" SG_ 2173691288 VehicleLevelRearRight 32000;
BA_ "GenSigSendType" SG_ 2173691288 VehicleLevelRearRight 1;
BA_ "VFrameFormat" BO_ 2566805904 1;
BA_ "GenSigInactiveValue" SG_ 2566805904 VehicleLevelFrontLeft 32000;
BA_ "GenSigStartValue" SG_ 2566805904 VehicleLevelFrontLeft 32000;
BA_ "GenSigSendType" SG_ 2566805904 VehicleLevelFrontLeft 1;
BA_ "GenSigInactiveValue" SG_ 2566805904 VehicleLevelFrontRight 32000;
BA_ "GenSigStartValue" SG_ 2566805904 VehicleLevelFrontRight 32000;
BA_ "GenSigSendType" SG_ 2566805904 VehicleLevelFrontRight 1;
BA_ "GenSigInactiveValue" SG_ 2566805904 VehicleLevelRearLeft 32000;
BA_ "GenSigStartValue" SG_ 2566805904 VehicleLevelRearLeft 32000;
BA_ "GenSigSendType" SG_ 2566805904 VehicleLevelRearLeft 1;
BA_ "GenSigInactiveValue" SG_ 2566805904 VehicleLevelRearRight 32000;
BA_ "GenSigStartValue" SG_ 2566805904 VehicleLevelRearRight 32000;
BA_ "GenSigSendType" SG_ 2566805904 VehicleLevelRearRight 1;
BA_ "VFrameFormat" BO_ 2566805896 1;
BA_ "GenSigInactiveValue" SG_ 2566805896 VehicleLevelFrontLeft 32000;
BA_ "GenSigStartValue" SG_ 2566805896 VehicleLevelFrontLeft 32000;
BA_ "GenSigSendType" SG_ 2566805896 VehicleLevelFrontLeft 1;
BA_ "GenSigInactiveValue" SG_ 2566805896 VehicleLevelFrontRight 32000;
BA_ "GenSigStartValue" SG_ 2566805896 VehicleLevelFrontRight 32000;
BA_ "GenSigSendType" SG_ 2566805896 VehicleLevelFrontRight 1;
BA_ "GenSigInactiveValue" SG_ 2566805896 VehicleLevelRearLeft 32000;
BA_ "GenSigStartValue" SG_ 2566805896 VehicleLevelRearLeft 32000;
BA_ "GenSigSendType" SG_ 2566805896 VehicleLevelRearLeft 1;
BA_ "GenSigInactiveValue" SG_ 2566805896 VehicleLevelRearRight 32000;
BA_ "GenSigStartValue" SG_ 2566805896 VehicleLevelRearRight 32000;
BA_ "GenSigSendType" SG_ 2566805896 VehicleLevelRearRight 1;
BA_ "VFrameFormat" BO_ 2566805888 1;
BA_ "GenSigInactiveValue" SG_ 2566805888 VehicleLevelFrontLeft 32000;
BA_ "GenSigStartValue" SG_ 2566805888 VehicleLevelFrontLeft 32000;
BA_ "GenSigSendType" SG_ 2566805888 VehicleLevelFrontLeft 1;
BA_ "GenSigInactiveValue" SG_ 2566805888 VehicleLevelFrontRight 32000;
BA_ "GenSigStartValue" SG_ 2566805888 VehicleLevelFrontRight 32000;
BA_ "GenSigSendType" SG_ 2566805888 VehicleLevelFrontRight 1;
BA_ "GenSigInactiveValue" SG_ 2566805888 VehicleLevelRearLeft 32000;
BA_ "GenSigStartValue" SG_ 2566805888 VehicleLevelRearLeft 32000;
BA_ "GenSigSendType" SG_ 2566805888 VehicleLevelRearLeft 1;
BA_ "GenSigInactiveValue" SG_ 2566805888 VehicleLevelRearRight 32000;
BA_ "GenSigStartValue" SG_ 2566805888 VehicleLevelRearRight 32000;
BA_ "GenSigSendType" SG_ 2566805888 VehicleLevelRearRight 1;
BA_ "VFrameFormat" BO_ 2566813896 1;
BA_ "GenSigSendType" SG_ 2566813896 Tire_Press_Sw_Sta 1;
BA_ "VFrameFormat" BO_ 2566813888 1;
BA_ "GenSigSendType" SG_ 2566813888 Tire_Press_Sw_Sta 1;
BA_ "VFrameFormat" BO_ 2566813880 1;
BA_ "GenSigSendType" SG_ 2566813880 Tire_Press_Sw_Sta 1;
BA_ "VFrameFormat" BO_ 2566813872 1;
BA_ "GenSigSendType" SG_ 2566813872 Tire_Press_Sw_Sta 1;
BA_ "VFrameFormat" BO_ 2566813864 1;
BA_ "GenSigSendType" SG_ 2566813864 Tire_Press_Sw_Sta 1;
BA_ "VFrameFormat" BO_ 2566813856 1;
BA_ "GenSigSendType" SG_ 2566813856 Tire_Press_Sw_Sta 1;
BA_ "VFrameFormat" BO_ 2566813848 1;
BA_ "GenSigSendType" SG_ 2566813848 Tire_Press_Sw_Sta 1;
BA_ "VFrameFormat" BO_ 2566813840 1;
BA_ "GenSigSendType" SG_ 2566813840 Tire_Press_Sw_Sta 1;
BA_ "VFrameFormat" BO_ 2566813832 1;
BA_ "GenSigSendType" SG_ 2566813832 Tire_Press_Sw_Sta 1;
BA_ "VFrameFormat" BO_ 2566813824 1;
BA_ "GenSigSendType" SG_ 2566813824 Tire_Press_Sw_Sta 1;
BA_ "VFrameFormat" BO_ 2566844872 1;
BA_ "GenSigSendType" SG_ 2566844872 ParkBrakeSwitch 1;
BA_ "VFrameFormat" BO_ 2566844864 1;
BA_ "GenSigSendType" SG_ 2566844864 ParkBrakeSwitch 1;
BA_ "VFrameFormat" BO_ 2566844856 1;
BA_ "GenSigSendType" SG_ 2566844856 ParkBrakeSwitch 1;
BA_ "VFrameFormat" BO_ 2566844848 1;
BA_ "GenSigSendType" SG_ 2566844848 ParkBrakeSwitch 1;
BA_ "VFrameFormat" BO_ 2566844840 1;
BA_ "GenSigSendType" SG_ 2566844840 ParkBrakeSwitch 1;
BA_ "VFrameFormat" BO_ 2566844832 1;
BA_ "GenSigSendType" SG_ 2566844832 ParkBrakeSwitch 1;
BA_ "VFrameFormat" BO_ 2566844824 1;
BA_ "GenSigSendType" SG_ 2566844824 ParkBrakeSwitch 1;
BA_ "VFrameFormat" BO_ 2566844816 1;
BA_ "GenSigSendType" SG_ 2566844816 ParkBrakeSwitch 1;
BA_ "VFrameFormat" BO_ 2566844808 1;
BA_ "GenSigSendType" SG_ 2566844808 ParkBrakeSwitch 1;
BA_ "VFrameFormat" BO_ 2566844800 1;
BA_ "GenSigSendType" SG_ 2566844800 ParkBrakeSwitch 1;
BA_ "VFrameFormat" BO_ 2566848712 1;
BA_ "GenSigSendType" SG_ 2566848712 Overload 1;
BA_ "GenSigSendType" SG_ 2566848712 TracHelp 1;
BA_ "GenSigSendType" SG_ 2566848712 P1_Sys 1;
BA_ "GenSigSendType" SG_ 2566848712 P4_Dem 1;
BA_ "GenSigSendType" SG_ 2566848712 EBS_Press 1;
BA_ "GenSigSendType" SG_ 2566848712 AvgBrPressMain 1;
BA_ "GenSigSendType" SG_ 2566848712 AvgBrPressSteer 1;
BA_ "GenSigSendType" SG_ 2566848712 LoadPress 1;
BA_ "VFrameFormat" BO_ 2566848704 1;
BA_ "GenSigSendType" SG_ 2566848704 Overload 1;
BA_ "GenSigSendType" SG_ 2566848704 TracHelp 1;
BA_ "GenSigSendType" SG_ 2566848704 P1_Sys 1;
BA_ "GenSigSendType" SG_ 2566848704 P4_Dem 1;
BA_ "GenSigSendType" SG_ 2566848704 EBS_Press 1;
BA_ "GenSigSendType" SG_ 2566848704 AvgBrPressMain 1;
BA_ "GenSigSendType" SG_ 2566848704 AvgBrPressSteer 1;
BA_ "GenSigSendType" SG_ 2566848704 LoadPress 1;
BA_ "VFrameFormat" BO_ 2566848696 1;
BA_ "GenSigSendType" SG_ 2566848696 Overload 1;
BA_ "GenSigSendType" SG_ 2566848696 TracHelp 1;
BA_ "GenSigSendType" SG_ 2566848696 P1_Sys 1;
BA_ "GenSigSendType" SG_ 2566848696 P4_Dem 1;
BA_ "GenSigSendType" SG_ 2566848696 EBS_Press 1;
BA_ "GenSigSendType" SG_ 2566848696 AvgBrPressMain 1;
BA_ "GenSigSendType" SG_ 2566848696 AvgBrPressSteer 1;
BA_ "GenSigSendType" SG_ 2566848696 LoadPress 1;
BA_ "VFrameFormat" BO_ 2566848688 1;
BA_ "GenSigSendType" SG_ 2566848688 Overload 1;
BA_ "GenSigSendType" SG_ 2566848688 TracHelp 1;
BA_ "GenSigSendType" SG_ 2566848688 P1_Sys 1;
BA_ "GenSigSendType" SG_ 2566848688 P4_Dem 1;
BA_ "GenSigSendType" SG_ 2566848688 EBS_Press 1;
BA_ "GenSigSendType" SG_ 2566848688 AvgBrPressMain 1;
BA_ "GenSigSendType" SG_ 2566848688 AvgBrPressSteer 1;
BA_ "GenSigSendType" SG_ 2566848688 LoadPress 1;
BA_ "VFrameFormat" BO_ 2566848680 1;
BA_ "GenSigSendType" SG_ 2566848680 Overload 1;
BA_ "GenSigSendType" SG_ 2566848680 TracHelp 1;
BA_ "GenSigSendType" SG_ 2566848680 P1_Sys 1;
BA_ "GenSigSendType" SG_ 2566848680 P4_Dem 1;
BA_ "GenSigSendType" SG_ 2566848680 EBS_Press 1;
BA_ "GenSigSendType" SG_ 2566848680 AvgBrPressMain 1;
BA_ "GenSigSendType" SG_ 2566848680 AvgBrPressSteer 1;
BA_ "GenSigSendType" SG_ 2566848680 LoadPress 1;
BA_ "VFrameFormat" BO_ 2566848672 1;
BA_ "GenSigSendType" SG_ 2566848672 Overload 1;
BA_ "GenSigSendType" SG_ 2566848672 TracHelp 1;
BA_ "GenSigSendType" SG_ 2566848672 P1_Sys 1;
BA_ "GenSigSendType" SG_ 2566848672 P4_Dem 1;
BA_ "GenSigSendType" SG_ 2566848672 EBS_Press 1;
BA_ "GenSigSendType" SG_ 2566848672 AvgBrPressMain 1;
BA_ "GenSigSendType" SG_ 2566848672 AvgBrPressSteer 1;
BA_ "GenSigSendType" SG_ 2566848672 LoadPress 1;
BA_ "VFrameFormat" BO_ 2566848664 1;
BA_ "GenSigSendType" SG_ 2566848664 Overload 1;
BA_ "GenSigSendType" SG_ 2566848664 TracHelp 1;
BA_ "GenSigSendType" SG_ 2566848664 P1_Sys 1;
BA_ "GenSigSendType" SG_ 2566848664 P4_Dem 1;
BA_ "GenSigSendType" SG_ 2566848664 EBS_Press 1;
BA_ "GenSigSendType" SG_ 2566848664 AvgBrPressMain 1;
BA_ "GenSigSendType" SG_ 2566848664 AvgBrPressSteer 1;
BA_ "GenSigSendType" SG_ 2566848664 LoadPress 1;
BA_ "VFrameFormat" BO_ 2566848656 1;
BA_ "GenSigSendType" SG_ 2566848656 Overload 1;
BA_ "GenSigSendType" SG_ 2566848656 TracHelp 1;
BA_ "GenSigSendType" SG_ 2566848656 P1_Sys 1;
BA_ "GenSigSendType" SG_ 2566848656 P4_Dem 1;
BA_ "GenSigSendType" SG_ 2566848656 EBS_Press 1;
BA_ "GenSigSendType" SG_ 2566848656 AvgBrPressMain 1;
BA_ "GenSigSendType" SG_ 2566848656 AvgBrPressSteer 1;
BA_ "GenSigSendType" SG_ 2566848656 LoadPress 1;
BA_ "VFrameFormat" BO_ 2566848648 1;
BA_ "GenSigSendType" SG_ 2566848648 Overload 1;
BA_ "GenSigSendType" SG_ 2566848648 TracHelp 1;
BA_ "GenSigSendType" SG_ 2566848648 P1_Sys 1;
BA_ "GenSigSendType" SG_ 2566848648 P4_Dem 1;
BA_ "GenSigSendType" SG_ 2566848648 EBS_Press 1;
BA_ "GenSigSendType" SG_ 2566848648 AvgBrPressMain 1;
BA_ "GenSigSendType" SG_ 2566848648 AvgBrPressSteer 1;
BA_ "GenSigSendType" SG_ 2566848648 LoadPress 1;
BA_ "VFrameFormat" BO_ 2566848640 1;
BA_ "GenSigSendType" SG_ 2566848640 Overload 1;
BA_ "GenSigSendType" SG_ 2566848640 TracHelp 1;
BA_ "GenSigSendType" SG_ 2566848640 P1_Sys 1;
BA_ "GenSigSendType" SG_ 2566848640 P4_Dem 1;
BA_ "GenSigSendType" SG_ 2566848640 EBS_Press 1;
BA_ "GenSigSendType" SG_ 2566848640 AvgBrPressMain 1;
BA_ "GenSigSendType" SG_ 2566848640 AvgBrPressSteer 1;
BA_ "GenSigSendType" SG_ 2566848640 LoadPress 1;
BA_ "VFrameFormat" BO_ 2566849224 1;
BA_ "GenSigSendType" SG_ 2566849224 StBkpPSup 1;
BA_ "GenSigSendType" SG_ 2566849224 StISO7638PSup 1;
BA_ "GenSigSendType" SG_ 2566849224 YellowPress 1;
BA_ "GenSigSendType" SG_ 2566849224 PCANDem 1;
BA_ "GenSigSendType" SG_ 2566849224 P21 1;
BA_ "GenSigSendType" SG_ 2566849224 P22 1;
BA_ "GenSigSendType" SG_ 2566849224 P2P23 1;
BA_ "VFrameFormat" BO_ 2566849216 1;
BA_ "GenSigSendType" SG_ 2566849216 StBkpPSup 1;
BA_ "GenSigSendType" SG_ 2566849216 StISO7638PSup 1;
BA_ "GenSigSendType" SG_ 2566849216 YellowPress 1;
BA_ "GenSigSendType" SG_ 2566849216 PCANDem 1;
BA_ "GenSigSendType" SG_ 2566849216 P21 1;
BA_ "GenSigSendType" SG_ 2566849216 P22 1;
BA_ "GenSigSendType" SG_ 2566849216 P2P23 1;
BA_ "VFrameFormat" BO_ 2566849208 1;
BA_ "GenSigSendType" SG_ 2566849208 StBkpPSup 1;
BA_ "GenSigSendType" SG_ 2566849208 StISO7638PSup 1;
BA_ "GenSigSendType" SG_ 2566849208 YellowPress 1;
BA_ "GenSigSendType" SG_ 2566849208 PCANDem 1;
BA_ "GenSigSendType" SG_ 2566849208 P21 1;
BA_ "GenSigSendType" SG_ 2566849208 P22 1;
BA_ "GenSigSendType" SG_ 2566849208 P2P23 1;
BA_ "VFrameFormat" BO_ 2566849200 1;
BA_ "GenSigSendType" SG_ 2566849200 StBkpPSup 1;
BA_ "GenSigSendType" SG_ 2566849200 StISO7638PSup 1;
BA_ "GenSigSendType" SG_ 2566849200 YellowPress 1;
BA_ "GenSigSendType" SG_ 2566849200 PCANDem 1;
BA_ "GenSigSendType" SG_ 2566849200 P21 1;
BA_ "GenSigSendType" SG_ 2566849200 P22 1;
BA_ "GenSigSendType" SG_ 2566849200 P2P23 1;
BA_ "VFrameFormat" BO_ 2566849192 1;
BA_ "GenSigSendType" SG_ 2566849192 StBkpPSup 1;
BA_ "GenSigSendType" SG_ 2566849192 StISO7638PSup 1;
BA_ "GenSigSendType" SG_ 2566849192 YellowPress 1;
BA_ "GenSigSendType" SG_ 2566849192 PCANDem 1;
BA_ "GenSigSendType" SG_ 2566849192 P21 1;
BA_ "GenSigSendType" SG_ 2566849192 P22 1;
BA_ "GenSigSendType" SG_ 2566849192 P2P23 1;
BA_ "VFrameFormat" BO_ 2566849184 1;
BA_ "GenSigSendType" SG_ 2566849184 StBkpPSup 1;
BA_ "GenSigSendType" SG_ 2566849184 StISO7638PSup 1;
BA_ "GenSigSendType" SG_ 2566849184 YellowPress 1;
BA_ "GenSigSendType" SG_ 2566849184 PCANDem 1;
BA_ "GenSigSendType" SG_ 2566849184 P21 1;
BA_ "GenSigSendType" SG_ 2566849184 P22 1;
BA_ "GenSigSendType" SG_ 2566849184 P2P23 1;
BA_ "VFrameFormat" BO_ 2566849176 1;
BA_ "GenSigSendType" SG_ 2566849176 StBkpPSup 1;
BA_ "GenSigSendType" SG_ 2566849176 StISO7638PSup 1;
BA_ "GenSigSendType" SG_ 2566849176 YellowPress 1;
BA_ "GenSigSendType" SG_ 2566849176 PCANDem 1;
BA_ "GenSigSendType" SG_ 2566849176 P21 1;
BA_ "GenSigSendType" SG_ 2566849176 P22 1;
BA_ "GenSigSendType" SG_ 2566849176 P2P23 1;
BA_ "VFrameFormat" BO_ 2566849168 1;
BA_ "GenSigSendType" SG_ 2566849168 StBkpPSup 1;
BA_ "GenSigSendType" SG_ 2566849168 StISO7638PSup 1;
BA_ "GenSigSendType" SG_ 2566849168 YellowPress 1;
BA_ "GenSigSendType" SG_ 2566849168 PCANDem 1;
BA_ "GenSigSendType" SG_ 2566849168 P21 1;
BA_ "GenSigSendType" SG_ 2566849168 P22 1;
BA_ "GenSigSendType" SG_ 2566849168 P2P23 1;
BA_ "VFrameFormat" BO_ 2566849160 1;
BA_ "GenSigSendType" SG_ 2566849160 StBkpPSup 1;
BA_ "GenSigSendType" SG_ 2566849160 StISO7638PSup 1;
BA_ "GenSigSendType" SG_ 2566849160 YellowPress 1;
BA_ "GenSigSendType" SG_ 2566849160 PCANDem 1;
BA_ "GenSigSendType" SG_ 2566849160 P21 1;
BA_ "GenSigSendType" SG_ 2566849160 P22 1;
BA_ "GenSigSendType" SG_ 2566849160 P2P23 1;
BA_ "VFrameFormat" BO_ 2566849152 1;
BA_ "GenSigSendType" SG_ 2566849152 StBkpPSup 1;
BA_ "GenSigSendType" SG_ 2566849152 StISO7638PSup 1;
BA_ "GenSigSendType" SG_ 2566849152 YellowPress 1;
BA_ "GenSigSendType" SG_ 2566849152 PCANDem 1;
BA_ "GenSigSendType" SG_ 2566849152 P21 1;
BA_ "GenSigSendType" SG_ 2566849152 P22 1;
BA_ "GenSigSendType" SG_ 2566849152 P2P23 1;
BA_ "VFrameFormat" BO_ 2566849480 1;
BA_ "GenSigSendType" SG_ 2566849480 TrlInfInd 1;
BA_ "GenSigSendType" SG_ 2566849480 TrlInfDat 1;
BA_ "GenSigSendType" SG_ 2566849480 Odometer 1;
BA_ "GenSigSendType" SG_ 2566849480 ConDevPermTr 1;
BA_ "VFrameFormat" BO_ 2566849472 1;
BA_ "GenSigSendType" SG_ 2566849472 TrlInfInd 1;
BA_ "GenSigSendType" SG_ 2566849472 TrlInfDat 1;
BA_ "GenSigSendType" SG_ 2566849472 Odometer 1;
BA_ "GenSigSendType" SG_ 2566849472 ConDevPermTr 1;
BA_ "VFrameFormat" BO_ 2566849464 1;
BA_ "GenSigSendType" SG_ 2566849464 TrlInfInd 1;
BA_ "GenSigSendType" SG_ 2566849464 TrlInfDat 1;
BA_ "GenSigSendType" SG_ 2566849464 Odometer 1;
BA_ "GenSigSendType" SG_ 2566849464 ConDevPermTr 1;
BA_ "VFrameFormat" BO_ 2566849456 1;
BA_ "GenSigSendType" SG_ 2566849456 TrlInfInd 1;
BA_ "GenSigSendType" SG_ 2566849456 TrlInfDat 1;
BA_ "GenSigSendType" SG_ 2566849456 Odometer 1;
BA_ "GenSigSendType" SG_ 2566849456 ConDevPermTr 1;
BA_ "VFrameFormat" BO_ 2566849448 1;
BA_ "GenSigSendType" SG_ 2566849448 TrlInfInd 1;
BA_ "GenSigSendType" SG_ 2566849448 TrlInfDat 1;
BA_ "GenSigSendType" SG_ 2566849448 Odometer 1;
BA_ "GenSigSendType" SG_ 2566849448 ConDevPermTr 1;
BA_ "VFrameFormat" BO_ 2566849440 1;
BA_ "GenSigSendType" SG_ 2566849440 TrlInfInd 1;
BA_ "GenSigSendType" SG_ 2566849440 TrlInfDat 1;
BA_ "GenSigSendType" SG_ 2566849440 Odometer 1;
BA_ "GenSigSendType" SG_ 2566849440 ConDevPermTr 1;
BA_ "VFrameFormat" BO_ 2566849432 1;
BA_ "GenSigSendType" SG_ 2566849432 TrlInfInd 1;
BA_ "GenSigSendType" SG_ 2566849432 TrlInfDat 1;
BA_ "GenSigSendType" SG_ 2566849432 Odometer 1;
BA_ "GenSigSendType" SG_ 2566849432 ConDevPermTr 1;
BA_ "VFrameFormat" BO_ 2566849424 1;
BA_ "GenSigSendType" SG_ 2566849424 TrlInfInd 1;
BA_ "GenSigSendType" SG_ 2566849424 TrlInfDat 1;
BA_ "GenSigSendType" SG_ 2566849424 Odometer 1;
BA_ "GenSigSendType" SG_ 2566849424 ConDevPermTr 1;
BA_ "VFrameFormat" BO_ 2566849416 1;
BA_ "GenSigSendType" SG_ 2566849416 TrlInfInd 1;
BA_ "GenSigSendType" SG_ 2566849416 TrlInfDat 1;
BA_ "GenSigSendType" SG_ 2566849416 Odometer 1;
BA_ "GenSigSendType" SG_ 2566849416 ConDevPermTr 1;
BA_ "VFrameFormat" BO_ 2566849408 1;
BA_ "GenSigSendType" SG_ 2566849408 TrlInfInd 1;
BA_ "GenSigSendType" SG_ 2566849408 TrlInfDat 1;
BA_ "GenSigSendType" SG_ 2566849408 Odometer 1;
BA_ "GenSigSendType" SG_ 2566849408 ConDevPermTr 1;
BA_ "VFrameFormat" BO_ 2566851272 1;
BA_ "GenSigSendType" SG_ 2566851272 BLI_active 1;
BA_ "GenSigSendType" SG_ 2566851272 BLI_ovrd 1;
BA_ "GenSigSendType" SG_ 2566851272 BLS_status 1;
BA_ "GenSigSendType" SG_ 2566851272 TG_status 1;
BA_ "GenSigSendType" SG_ 2566851272 TG_Cont_status 1;
BA_ "GenSigSendType" SG_ 2566851272 Cover_status 1;
BA_ "GenSigSendType" SG_ 2566851272 URP_status 1;
BA_ "GenSigSendType" SG_ 2566851272 RLF_status 1;
BA_ "GenSigSendType" SG_ 2566851272 TrHelp_status 1;
BA_ "GenSigSendType" SG_ 2566851272 OWS_status 1;
BA_ "GenSigSendType" SG_ 2566851272 TIS_status 1;
BA_ "GenSigSendType" SG_ 2566851272 iLvl_aut_low 1;
BA_ "GenSigInactiveValue" SG_ 2566851272 Tilt_Angle 125;
BA_ "GenSigStartValue" SG_ 2566851272 Tilt_Angle 125;
BA_ "GenSigSendType" SG_ 2566851272 Tilt_Angle 1;
BA_ "GenSigInactiveValue" SG_ 2566851272 BL_Angle 125;
BA_ "GenSigStartValue" SG_ 2566851272 BL_Angle 125;
BA_ "GenSigSendType" SG_ 2566851272 BL_Angle 1;
BA_ "GenSigInactiveValue" SG_ 2566851272 Art_Angle 125;
BA_ "GenSigStartValue" SG_ 2566851272 Art_Angle 125;
BA_ "GenSigSendType" SG_ 2566851272 Art_Angle 1;
BA_ "GenSigSendType" SG_ 2566851272 OWS_Weight 1;
BA_ "VFrameFormat" BO_ 2566851264 1;
BA_ "GenSigSendType" SG_ 2566851264 BLI_active 1;
BA_ "GenSigSendType" SG_ 2566851264 BLI_ovrd 1;
BA_ "GenSigSendType" SG_ 2566851264 BLS_status 1;
BA_ "GenSigSendType" SG_ 2566851264 TG_status 1;
BA_ "GenSigSendType" SG_ 2566851264 TG_Cont_status 1;
BA_ "GenSigSendType" SG_ 2566851264 Cover_status 1;
BA_ "GenSigSendType" SG_ 2566851264 URP_status 1;
BA_ "GenSigSendType" SG_ 2566851264 RLF_status 1;
BA_ "GenSigSendType" SG_ 2566851264 TrHelp_status 1;
BA_ "GenSigSendType" SG_ 2566851264 OWS_status 1;
BA_ "GenSigSendType" SG_ 2566851264 TIS_status 1;
BA_ "GenSigSendType" SG_ 2566851264 iLvl_aut_low 1;
BA_ "GenSigInactiveValue" SG_ 2566851264 Tilt_Angle 125;
BA_ "GenSigStartValue" SG_ 2566851264 Tilt_Angle 125;
BA_ "GenSigSendType" SG_ 2566851264 Tilt_Angle 1;
BA_ "GenSigInactiveValue" SG_ 2566851264 BL_Angle 125;
BA_ "GenSigStartValue" SG_ 2566851264 BL_Angle 125;
BA_ "GenSigSendType" SG_ 2566851264 BL_Angle 1;
BA_ "GenSigInactiveValue" SG_ 2566851264 Art_Angle 125;
BA_ "GenSigStartValue" SG_ 2566851264 Art_Angle 125;
BA_ "GenSigSendType" SG_ 2566851264 Art_Angle 1;
BA_ "GenSigSendType" SG_ 2566851264 OWS_Weight 1;
BA_ "VFrameFormat" BO_ 2566851256 1;
BA_ "GenSigSendType" SG_ 2566851256 BLI_active 1;
BA_ "GenSigSendType" SG_ 2566851256 BLI_ovrd 1;
BA_ "GenSigSendType" SG_ 2566851256 BLS_status 1;
BA_ "GenSigSendType" SG_ 2566851256 TG_status 1;
BA_ "GenSigSendType" SG_ 2566851256 TG_Cont_status 1;
BA_ "GenSigSendType" SG_ 2566851256 Cover_status 1;
BA_ "GenSigSendType" SG_ 2566851256 URP_status 1;
BA_ "GenSigSendType" SG_ 2566851256 RLF_status 1;
BA_ "GenSigSendType" SG_ 2566851256 TrHelp_status 1;
BA_ "GenSigSendType" SG_ 2566851256 OWS_status 1;
BA_ "GenSigSendType" SG_ 2566851256 TIS_status 1;
BA_ "GenSigSendType" SG_ 2566851256 iLvl_aut_low 1;
BA_ "GenSigInactiveValue" SG_ 2566851256 Tilt_Angle 125;
BA_ "GenSigStartValue" SG_ 2566851256 Tilt_Angle 125;
BA_ "GenSigSendType" SG_ 2566851256 Tilt_Angle 1;
BA_ "GenSigInactiveValue" SG_ 2566851256 BL_Angle 125;
BA_ "GenSigStartValue" SG_ 2566851256 BL_Angle 125;
BA_ "GenSigSendType" SG_ 2566851256 BL_Angle 1;
BA_ "GenSigInactiveValue" SG_ 2566851256 Art_Angle 125;
BA_ "GenSigStartValue" SG_ 2566851256 Art_Angle 125;
BA_ "GenSigSendType" SG_ 2566851256 Art_Angle 1;
BA_ "GenSigSendType" SG_ 2566851256 OWS_Weight 1;
BA_ "VFrameFormat" BO_ 2566851248 1;
BA_ "GenSigSendType" SG_ 2566851248 BLI_active 1;
BA_ "GenSigSendType" SG_ 2566851248 BLI_ovrd 1;
BA_ "GenSigSendType" SG_ 2566851248 BLS_status 1;
BA_ "GenSigSendType" SG_ 2566851248 TG_status 1;
BA_ "GenSigSendType" SG_ 2566851248 TG_Cont_status 1;
BA_ "GenSigSendType" SG_ 2566851248 Cover_status 1;
BA_ "GenSigSendType" SG_ 2566851248 URP_status 1;
BA_ "GenSigSendType" SG_ 2566851248 RLF_status 1;
BA_ "GenSigSendType" SG_ 2566851248 TrHelp_status 1;
BA_ "GenSigSendType" SG_ 2566851248 OWS_status 1;
BA_ "GenSigSendType" SG_ 2566851248 TIS_status 1;
BA_ "GenSigSendType" SG_ 2566851248 iLvl_aut_low 1;
BA_ "GenSigInactiveValue" SG_ 2566851248 Tilt_Angle 125;
BA_ "GenSigStartValue" SG_ 2566851248 Tilt_Angle 125;
BA_ "GenSigSendType" SG_ 2566851248 Tilt_Angle 1;
BA_ "GenSigInactiveValue" SG_ 2566851248 BL_Angle 125;
BA_ "GenSigStartValue" SG_ 2566851248 BL_Angle 125;
BA_ "GenSigSendType" SG_ 2566851248 BL_Angle 1;
BA_ "GenSigInactiveValue" SG_ 2566851248 Art_Angle 125;
BA_ "GenSigStartValue" SG_ 2566851248 Art_Angle 125;
BA_ "GenSigSendType" SG_ 2566851248 Art_Angle 1;
BA_ "GenSigSendType" SG_ 2566851248 OWS_Weight 1;
BA_ "VFrameFormat" BO_ 2566851240 1;
BA_ "GenSigSendType" SG_ 2566851240 BLI_active 1;
BA_ "GenSigSendType" SG_ 2566851240 BLI_ovrd 1;
BA_ "GenSigSendType" SG_ 2566851240 BLS_status 1;
BA_ "GenSigSendType" SG_ 2566851240 TG_status 1;
BA_ "GenSigSendType" SG_ 2566851240 TG_Cont_status 1;
BA_ "GenSigSendType" SG_ 2566851240 Cover_status 1;
BA_ "GenSigSendType" SG_ 2566851240 URP_status 1;
BA_ "GenSigSendType" SG_ 2566851240 RLF_status 1;
BA_ "GenSigSendType" SG_ 2566851240 TrHelp_status 1;
BA_ "GenSigSendType" SG_ 2566851240 OWS_status 1;
BA_ "GenSigSendType" SG_ 2566851240 TIS_status 1;
BA_ "GenSigSendType" SG_ 2566851240 iLvl_aut_low 1;
BA_ "GenSigInactiveValue" SG_ 2566851240 Tilt_Angle 125;
BA_ "GenSigStartValue" SG_ 2566851240 Tilt_Angle 125;
BA_ "GenSigSendType" SG_ 2566851240 Tilt_Angle 1;
BA_ "GenSigInactiveValue" SG_ 2566851240 BL_Angle 125;
BA_ "GenSigStartValue" SG_ 2566851240 BL_Angle 125;
BA_ "GenSigSendType" SG_ 2566851240 BL_Angle 1;
BA_ "GenSigInactiveValue" SG_ 2566851240 Art_Angle 125;
BA_ "GenSigStartValue" SG_ 2566851240 Art_Angle 125;
BA_ "GenSigSendType" SG_ 2566851240 Art_Angle 1;
BA_ "GenSigSendType" SG_ 2566851240 OWS_Weight 1;
BA_ "VFrameFormat" BO_ 2566851232 1;
BA_ "GenSigSendType" SG_ 2566851232 BLI_active 1;
BA_ "GenSigSendType" SG_ 2566851232 BLI_ovrd 1;
BA_ "GenSigSendType" SG_ 2566851232 BLS_status 1;
BA_ "GenSigSendType" SG_ 2566851232 TG_status 1;
BA_ "GenSigSendType" SG_ 2566851232 TG_Cont_status 1;
BA_ "GenSigSendType" SG_ 2566851232 Cover_status 1;
BA_ "GenSigSendType" SG_ 2566851232 URP_status 1;
BA_ "GenSigSendType" SG_ 2566851232 RLF_status 1;
BA_ "GenSigSendType" SG_ 2566851232 TrHelp_status 1;
BA_ "GenSigSendType" SG_ 2566851232 OWS_status 1;
BA_ "GenSigSendType" SG_ 2566851232 TIS_status 1;
BA_ "GenSigSendType" SG_ 2566851232 iLvl_aut_low 1;
BA_ "GenSigInactiveValue" SG_ 2566851232 Tilt_Angle 125;
BA_ "GenSigStartValue" SG_ 2566851232 Tilt_Angle 125;
BA_ "GenSigSendType" SG_ 2566851232 Tilt_Angle 1;
BA_ "GenSigInactiveValue" SG_ 2566851232 BL_Angle 125;
BA_ "GenSigStartValue" SG_ 2566851232 BL_Angle 125;
BA_ "GenSigSendType" SG_ 2566851232 BL_Angle 1;
BA_ "GenSigInactiveValue" SG_ 2566851232 Art_Angle 125;
BA_ "GenSigStartValue" SG_ 2566851232 Art_Angle 125;
BA_ "GenSigSendType" SG_ 2566851232 Art_Angle 1;
BA_ "GenSigSendType" SG_ 2566851232 OWS_Weight 1;
BA_ "VFrameFormat" BO_ 2566851224 1;
BA_ "GenSigSendType" SG_ 2566851224 BLI_active 1;
BA_ "GenSigSendType" SG_ 2566851224 BLI_ovrd 1;
BA_ "GenSigSendType" SG_ 2566851224 BLS_status 1;
BA_ "GenSigSendType" SG_ 2566851224 TG_status 1;
BA_ "GenSigSendType" SG_ 2566851224 TG_Cont_status 1;
BA_ "GenSigSendType" SG_ 2566851224 Cover_status 1;
BA_ "GenSigSendType" SG_ 2566851224 URP_status 1;
BA_ "GenSigSendType" SG_ 2566851224 RLF_status 1;
BA_ "GenSigSendType" SG_ 2566851224 TrHelp_status 1;
BA_ "GenSigSendType" SG_ 2566851224 OWS_status 1;
BA_ "GenSigSendType" SG_ 2566851224 TIS_status 1;
BA_ "GenSigSendType" SG_ 2566851224 iLvl_aut_low 1;
BA_ "GenSigInactiveValue" SG_ 2566851224 Tilt_Angle 125;
BA_ "GenSigStartValue" SG_ 2566851224 Tilt_Angle 125;
BA_ "GenSigSendType" SG_ 2566851224 Tilt_Angle 1;
BA_ "GenSigInactiveValue" SG_ 2566851224 BL_Angle 125;
BA_ "GenSigStartValue" SG_ 2566851224 BL_Angle 125;
BA_ "GenSigSendType" SG_ 2566851224 BL_Angle 1;
BA_ "GenSigInactiveValue" SG_ 2566851224 Art_Angle 125;
BA_ "GenSigStartValue" SG_ 2566851224 Art_Angle 125;
BA_ "GenSigSendType" SG_ 2566851224 Art_Angle 1;
BA_ "GenSigSendType" SG_ 2566851224 OWS_Weight 1;
BA_ "VFrameFormat" BO_ 2566851216 1;
BA_ "GenSigSendType" SG_ 2566851216 BLI_active 1;
BA_ "GenSigSendType" SG_ 2566851216 BLI_ovrd 1;
BA_ "GenSigSendType" SG_ 2566851216 BLS_status 1;
BA_ "GenSigSendType" SG_ 2566851216 TG_status 1;
BA_ "GenSigSendType" SG_ 2566851216 TG_Cont_status 1;
BA_ "GenSigSendType" SG_ 2566851216 Cover_status 1;
BA_ "GenSigSendType" SG_ 2566851216 URP_status 1;
BA_ "GenSigSendType" SG_ 2566851216 RLF_status 1;
BA_ "GenSigSendType" SG_ 2566851216 TrHelp_status 1;
BA_ "GenSigSendType" SG_ 2566851216 OWS_status 1;
BA_ "GenSigSendType" SG_ 2566851216 TIS_status 1;
BA_ "GenSigSendType" SG_ 2566851216 iLvl_aut_low 1;
BA_ "GenSigInactiveValue" SG_ 2566851216 Tilt_Angle 125;
BA_ "GenSigStartValue" SG_ 2566851216 Tilt_Angle 125;
BA_ "GenSigSendType" SG_ 2566851216 Tilt_Angle 1;
BA_ "GenSigInactiveValue" SG_ 2566851216 BL_Angle 125;
BA_ "GenSigStartValue" SG_ 2566851216 BL_Angle 125;
BA_ "GenSigSendType" SG_ 2566851216 BL_Angle 1;
BA_ "GenSigInactiveValue" SG_ 2566851216 Art_Angle 125;
BA_ "GenSigStartValue" SG_ 2566851216 Art_Angle 125;
BA_ "GenSigSendType" SG_ 2566851216 Art_Angle 1;
BA_ "GenSigSendType" SG_ 2566851216 OWS_Weight 1;
BA_ "VFrameFormat" BO_ 2566851208 1;
BA_ "GenSigSendType" SG_ 2566851208 BLI_active 1;
BA_ "GenSigSendType" SG_ 2566851208 BLI_ovrd 1;
BA_ "GenSigSendType" SG_ 2566851208 BLS_status 1;
BA_ "GenSigSendType" SG_ 2566851208 TG_status 1;
BA_ "GenSigSendType" SG_ 2566851208 TG_Cont_status 1;
BA_ "GenSigSendType" SG_ 2566851208 Cover_status 1;
BA_ "GenSigSendType" SG_ 2566851208 URP_status 1;
BA_ "GenSigSendType" SG_ 2566851208 RLF_status 1;
BA_ "GenSigSendType" SG_ 2566851208 TrHelp_status 1;
BA_ "GenSigSendType" SG_ 2566851208 OWS_status 1;
BA_ "GenSigSendType" SG_ 2566851208 TIS_status 1;
BA_ "GenSigSendType" SG_ 2566851208 iLvl_aut_low 1;
BA_ "GenSigInactiveValue" SG_ 2566851208 Tilt_Angle 125;
BA_ "GenSigStartValue" SG_ 2566851208 Tilt_Angle 125;
BA_ "GenSigSendType" SG_ 2566851208 Tilt_Angle 1;
BA_ "GenSigInactiveValue" SG_ 2566851208 BL_Angle 125;
BA_ "GenSigStartValue" SG_ 2566851208 BL_Angle 125;
BA_ "GenSigSendType" SG_ 2566851208 BL_Angle 1;
BA_ "GenSigInactiveValue" SG_ 2566851208 Art_Angle 125;
BA_ "GenSigStartValue" SG_ 2566851208 Art_Angle 125;
BA_ "GenSigSendType" SG_ 2566851208 Art_Angle 1;
BA_ "GenSigSendType" SG_ 2566851208 OWS_Weight 1;
BA_ "VFrameFormat" BO_ 2566851200 1;
BA_ "GenSigSendType" SG_ 2566851200 BLI_active 1;
BA_ "GenSigSendType" SG_ 2566851200 BLI_ovrd 1;
BA_ "GenSigSendType" SG_ 2566851200 BLS_status 1;
BA_ "GenSigSendType" SG_ 2566851200 TG_status 1;
BA_ "GenSigSendType" SG_ 2566851200 TG_Cont_status 1;
BA_ "GenSigSendType" SG_ 2566851200 Cover_status 1;
BA_ "GenSigSendType" SG_ 2566851200 URP_status 1;
BA_ "GenSigSendType" SG_ 2566851200 RLF_status 1;
BA_ "GenSigSendType" SG_ 2566851200 TrHelp_status 1;
BA_ "GenSigSendType" SG_ 2566851200 OWS_status 1;
BA_ "GenSigSendType" SG_ 2566851200 TIS_status 1;
BA_ "GenSigSendType" SG_ 2566851200 iLvl_aut_low 1;
BA_ "GenSigInactiveValue" SG_ 2566851200 Tilt_Angle 125;
BA_ "GenSigStartValue" SG_ 2566851200 Tilt_Angle 125;
BA_ "GenSigSendType" SG_ 2566851200 Tilt_Angle 1;
BA_ "GenSigInactiveValue" SG_ 2566851200 BL_Angle 125;
BA_ "GenSigStartValue" SG_ 2566851200 BL_Angle 125;
BA_ "GenSigSendType" SG_ 2566851200 BL_Angle 1;
BA_ "GenSigInactiveValue" SG_ 2566851200 Art_Angle 125;
BA_ "GenSigStartValue" SG_ 2566851200 Art_Angle 125;
BA_ "GenSigSendType" SG_ 2566851200 Art_Angle 1;
BA_ "GenSigSendType" SG_ 2566851200 OWS_Weight 1;
BA_ "VFrameFormat" BO_ 2566851528 1;
BA_ "GenSigSendType" SG_ 2566851528 WF_press 1;
BA_ "GenSigSendType" SG_ 2566851528 WF_temp 1;
BA_ "GenSigSendType" SG_ 2566851528 RearProximSta 1;
BA_ "GenSigSendType" SG_ 2566851528 SideProximSta 1;
BA_ "GenSigSendType" SG_ 2566851528 Immob_State 1;
BA_ "GenSigSendType" SG_ 2566851528 Immob_Safe_State 1;
BA_ "GenSigSendType" SG_ 2566851528 Immob_Fault_State 1;
BA_ "GenSigSendType" SG_ 2566851528 Immob_LockMoving_Sta 1;
BA_ "GenSigSendType" SG_ 2566851528 Immob_LockPressure_Sta 1;
BA_ "VFrameFormat" BO_ 2566851520 1;
BA_ "GenSigSendType" SG_ 2566851520 WF_press 1;
BA_ "GenSigSendType" SG_ 2566851520 WF_temp 1;
BA_ "GenSigSendType" SG_ 2566851520 RearProximSta 1;
BA_ "GenSigSendType" SG_ 2566851520 SideProximSta 1;
BA_ "GenSigSendType" SG_ 2566851520 Immob_State 1;
BA_ "GenSigSendType" SG_ 2566851520 Immob_Safe_State 1;
BA_ "GenSigSendType" SG_ 2566851520 Immob_Fault_State 1;
BA_ "GenSigSendType" SG_ 2566851520 Immob_LockMoving_Sta 1;
BA_ "GenSigSendType" SG_ 2566851520 Immob_LockPressure_Sta 1;
BA_ "VFrameFormat" BO_ 2566851512 1;
BA_ "GenSigSendType" SG_ 2566851512 WF_press 1;
BA_ "GenSigSendType" SG_ 2566851512 WF_temp 1;
BA_ "GenSigSendType" SG_ 2566851512 RearProximSta 1;
BA_ "GenSigSendType" SG_ 2566851512 SideProximSta 1;
BA_ "GenSigSendType" SG_ 2566851512 Immob_State 1;
BA_ "GenSigSendType" SG_ 2566851512 Immob_Safe_State 1;
BA_ "GenSigSendType" SG_ 2566851512 Immob_Fault_State 1;
BA_ "GenSigSendType" SG_ 2566851512 Immob_LockMoving_Sta 1;
BA_ "GenSigSendType" SG_ 2566851512 Immob_LockPressure_Sta 1;
BA_ "VFrameFormat" BO_ 2566851504 1;
BA_ "GenSigSendType" SG_ 2566851504 WF_press 1;
BA_ "GenSigSendType" SG_ 2566851504 WF_temp 1;
BA_ "GenSigSendType" SG_ 2566851504 RearProximSta 1;
BA_ "GenSigSendType" SG_ 2566851504 SideProximSta 1;
BA_ "GenSigSendType" SG_ 2566851504 Immob_State 1;
BA_ "GenSigSendType" SG_ 2566851504 Immob_Safe_State 1;
BA_ "GenSigSendType" SG_ 2566851504 Immob_Fault_State 1;
BA_ "GenSigSendType" SG_ 2566851504 Immob_LockMoving_Sta 1;
BA_ "GenSigSendType" SG_ 2566851504 Immob_LockPressure_Sta 1;
BA_ "VFrameFormat" BO_ 2566851496 1;
BA_ "GenSigSendType" SG_ 2566851496 WF_press 1;
BA_ "GenSigSendType" SG_ 2566851496 WF_temp 1;
BA_ "GenSigSendType" SG_ 2566851496 RearProximSta 1;
BA_ "GenSigSendType" SG_ 2566851496 SideProximSta 1;
BA_ "GenSigSendType" SG_ 2566851496 Immob_State 1;
BA_ "GenSigSendType" SG_ 2566851496 Immob_Safe_State 1;
BA_ "GenSigSendType" SG_ 2566851496 Immob_Fault_State 1;
BA_ "GenSigSendType" SG_ 2566851496 Immob_LockMoving_Sta 1;
BA_ "GenSigSendType" SG_ 2566851496 Immob_LockPressure_Sta 1;
BA_ "VFrameFormat" BO_ 2566851488 1;
BA_ "GenSigSendType" SG_ 2566851488 WF_press 1;
BA_ "GenSigSendType" SG_ 2566851488 WF_temp 1;
BA_ "GenSigSendType" SG_ 2566851488 RearProximSta 1;
BA_ "GenSigSendType" SG_ 2566851488 SideProximSta 1;
BA_ "GenSigSendType" SG_ 2566851488 Immob_State 1;
BA_ "GenSigSendType" SG_ 2566851488 Immob_Safe_State 1;
BA_ "GenSigSendType" SG_ 2566851488 Immob_Fault_State 1;
BA_ "GenSigSendType" SG_ 2566851488 Immob_LockMoving_Sta 1;
BA_ "GenSigSendType" SG_ 2566851488 Immob_LockPressure_Sta 1;
BA_ "VFrameFormat" BO_ 2566851480 1;
BA_ "GenSigSendType" SG_ 2566851480 WF_press 1;
BA_ "GenSigSendType" SG_ 2566851480 WF_temp 1;
BA_ "GenSigSendType" SG_ 2566851480 RearProximSta 1;
BA_ "GenSigSendType" SG_ 2566851480 SideProximSta 1;
BA_ "GenSigSendType" SG_ 2566851480 Immob_State 1;
BA_ "GenSigSendType" SG_ 2566851480 Immob_Safe_State 1;
BA_ "GenSigSendType" SG_ 2566851480 Immob_Fault_State 1;
BA_ "GenSigSendType" SG_ 2566851480 Immob_LockMoving_Sta 1;
BA_ "GenSigSendType" SG_ 2566851480 Immob_LockPressure_Sta 1;
BA_ "VFrameFormat" BO_ 2566851472 1;
BA_ "GenSigSendType" SG_ 2566851472 WF_press 1;
BA_ "GenSigSendType" SG_ 2566851472 WF_temp 1;
BA_ "GenSigSendType" SG_ 2566851472 RearProximSta 1;
BA_ "GenSigSendType" SG_ 2566851472 SideProximSta 1;
BA_ "GenSigSendType" SG_ 2566851472 Immob_State 1;
BA_ "GenSigSendType" SG_ 2566851472 Immob_Safe_State 1;
BA_ "GenSigSendType" SG_ 2566851472 Immob_Fault_State 1;
BA_ "GenSigSendType" SG_ 2566851472 Immob_LockMoving_Sta 1;
BA_ "GenSigSendType" SG_ 2566851472 Immob_LockPressure_Sta 1;
BA_ "VFrameFormat" BO_ 2566851464 1;
BA_ "GenSigSendType" SG_ 2566851464 WF_press 1;
BA_ "GenSigSendType" SG_ 2566851464 WF_temp 1;
BA_ "GenSigSendType" SG_ 2566851464 RearProximSta 1;
BA_ "GenSigSendType" SG_ 2566851464 SideProximSta 1;
BA_ "GenSigSendType" SG_ 2566851464 Immob_State 1;
BA_ "GenSigSendType" SG_ 2566851464 Immob_Safe_State 1;
BA_ "GenSigSendType" SG_ 2566851464 Immob_Fault_State 1;
BA_ "GenSigSendType" SG_ 2566851464 Immob_LockMoving_Sta 1;
BA_ "GenSigSendType" SG_ 2566851464 Immob_LockPressure_Sta 1;
BA_ "VFrameFormat" BO_ 2566851456 1;
BA_ "GenSigSendType" SG_ 2566851456 WF_press 1;
BA_ "GenSigSendType" SG_ 2566851456 WF_temp 1;
BA_ "GenSigSendType" SG_ 2566851456 RearProximSta 1;
BA_ "GenSigSendType" SG_ 2566851456 SideProximSta 1;
BA_ "GenSigSendType" SG_ 2566851456 Immob_State 1;
BA_ "GenSigSendType" SG_ 2566851456 Immob_Safe_State 1;
BA_ "GenSigSendType" SG_ 2566851456 Immob_Fault_State 1;
BA_ "GenSigSendType" SG_ 2566851456 Immob_LockMoving_Sta 1;
BA_ "GenSigSendType" SG_ 2566851456 Immob_LockPressure_Sta 1;
BA_ "VFrameFormat" BO_ 2566913480 1;
BA_ "GenSigInactiveValue" SG_ 2566913480 ServiceDist 2105540600;
BA_ "GenSigStartValue" SG_ 2566913480 ServiceDist 2105540600;
BA_ "GenSigSendType" SG_ 2566913480 ServiceDist 1;
BA_ "VFrameFormat" BO_ 2566913472 1;
BA_ "GenSigInactiveValue" SG_ 2566913472 ServiceDist 2105540600;
BA_ "GenSigStartValue" SG_ 2566913472 ServiceDist 2105540600;
BA_ "GenSigSendType" SG_ 2566913472 ServiceDist 1;
BA_ "VFrameFormat" BO_ 2566913464 1;
BA_ "GenSigInactiveValue" SG_ 2566913464 ServiceDist 2105540600;
BA_ "GenSigStartValue" SG_ 2566913464 ServiceDist 2105540600;
BA_ "GenSigSendType" SG_ 2566913464 ServiceDist 1;
BA_ "VFrameFormat" BO_ 2566913456 1;
BA_ "GenSigInactiveValue" SG_ 2566913456 ServiceDist 2105540600;
BA_ "GenSigStartValue" SG_ 2566913456 ServiceDist 2105540600;
BA_ "GenSigSendType" SG_ 2566913456 ServiceDist 1;
BA_ "VFrameFormat" BO_ 2566913448 1;
BA_ "GenSigInactiveValue" SG_ 2566913448 ServiceDist 2105540600;
BA_ "GenSigStartValue" SG_ 2566913448 ServiceDist 2105540600;
BA_ "GenSigSendType" SG_ 2566913448 ServiceDist 1;
BA_ "VFrameFormat" BO_ 2566913440 1;
BA_ "GenSigInactiveValue" SG_ 2566913440 ServiceDist 2105540600;
BA_ "GenSigStartValue" SG_ 2566913440 ServiceDist 2105540600;
BA_ "GenSigSendType" SG_ 2566913440 ServiceDist 1;
BA_ "VFrameFormat" BO_ 2566913432 1;
BA_ "GenSigInactiveValue" SG_ 2566913432 ServiceDist 2105540600;
BA_ "GenSigStartValue" SG_ 2566913432 ServiceDist 2105540600;
BA_ "GenSigSendType" SG_ 2566913432 ServiceDist 1;
BA_ "VFrameFormat" BO_ 2566913424 1;
BA_ "GenSigInactiveValue" SG_ 2566913424 ServiceDist 2105540600;
BA_ "GenSigStartValue" SG_ 2566913424 ServiceDist 2105540600;
BA_ "GenSigSendType" SG_ 2566913424 ServiceDist 1;
BA_ "VFrameFormat" BO_ 2566913416 1;
BA_ "GenSigInactiveValue" SG_ 2566913416 ServiceDist 2105540600;
BA_ "GenSigStartValue" SG_ 2566913416 ServiceDist 2105540600;
BA_ "GenSigSendType" SG_ 2566913416 ServiceDist 1;
BA_ "VFrameFormat" BO_ 2566913408 1;
BA_ "GenSigInactiveValue" SG_ 2566913408 ServiceDist 2105540600;
BA_ "GenSigStartValue" SG_ 2566913408 ServiceDist 2105540600;
BA_ "GenSigSendType" SG_ 2566913408 ServiceDist 1;
BA_ "VFrameFormat" BO_ 2566913736 1;
BA_ "GenSigSendType" SG_ 2566913736 Data 1;
BA_ "VFrameFormat" BO_ 2566913728 1;
BA_ "GenSigSendType" SG_ 2566913728 Data 1;
BA_ "VFrameFormat" BO_ 2566913720 1;
BA_ "GenSigSendType" SG_ 2566913720 Data 1;
BA_ "VFrameFormat" BO_ 2566913712 1;
BA_ "GenSigSendType" SG_ 2566913712 Data 1;
BA_ "VFrameFormat" BO_ 2566913704 1;
BA_ "GenSigSendType" SG_ 2566913704 Data 1;
BA_ "VFrameFormat" BO_ 2566913696 1;
BA_ "GenSigSendType" SG_ 2566913696 Data 1;
BA_ "VFrameFormat" BO_ 2566913688 1;
BA_ "GenSigSendType" SG_ 2566913688 Data 1;
BA_ "VFrameFormat" BO_ 2566913680 1;
BA_ "GenSigSendType" SG_ 2566913680 Data 1;
BA_ "VFrameFormat" BO_ 2566913672 1;
BA_ "GenSigSendType" SG_ 2566913672 Data 1;
BA_ "VFrameFormat" BO_ 2566913664 1;
BA_ "GenSigSendType" SG_ 2566913664 Data 1;
BA_ "VFrameFormat" BO_ 2566913992 1;
BA_ "GenSigSendType" SG_ 2566913992 VlvVolt 1;
BA_ "GenSigSendType" SG_ 2566913992 ElVolt 1;
BA_ "GenSigSendType" SG_ 2566913992 BogLoadPrc 1;
BA_ "GenSigSendType" SG_ 2566913992 TrlLoadPrc 1;
BA_ "VFrameFormat" BO_ 2566913984 1;
BA_ "GenSigSendType" SG_ 2566913984 VlvVolt 1;
BA_ "GenSigSendType" SG_ 2566913984 ElVolt 1;
BA_ "GenSigSendType" SG_ 2566913984 BogLoadPrc 1;
BA_ "GenSigSendType" SG_ 2566913984 TrlLoadPrc 1;
BA_ "VFrameFormat" BO_ 2566913976 1;
BA_ "GenSigSendType" SG_ 2566913976 VlvVolt 1;
BA_ "GenSigSendType" SG_ 2566913976 ElVolt 1;
BA_ "GenSigSendType" SG_ 2566913976 BogLoadPrc 1;
BA_ "GenSigSendType" SG_ 2566913976 TrlLoadPrc 1;
BA_ "VFrameFormat" BO_ 2566913968 1;
BA_ "GenSigSendType" SG_ 2566913968 VlvVolt 1;
BA_ "GenSigSendType" SG_ 2566913968 ElVolt 1;
BA_ "GenSigSendType" SG_ 2566913968 BogLoadPrc 1;
BA_ "GenSigSendType" SG_ 2566913968 TrlLoadPrc 1;
BA_ "VFrameFormat" BO_ 2566913960 1;
BA_ "GenSigSendType" SG_ 2566913960 VlvVolt 1;
BA_ "GenSigSendType" SG_ 2566913960 ElVolt 1;
BA_ "GenSigSendType" SG_ 2566913960 BogLoadPrc 1;
BA_ "GenSigSendType" SG_ 2566913960 TrlLoadPrc 1;
BA_ "VFrameFormat" BO_ 2566913952 1;
BA_ "GenSigSendType" SG_ 2566913952 VlvVolt 1;
BA_ "GenSigSendType" SG_ 2566913952 ElVolt 1;
BA_ "GenSigSendType" SG_ 2566913952 BogLoadPrc 1;
BA_ "GenSigSendType" SG_ 2566913952 TrlLoadPrc 1;
BA_ "VFrameFormat" BO_ 2566913944 1;
BA_ "GenSigSendType" SG_ 2566913944 VlvVolt 1;
BA_ "GenSigSendType" SG_ 2566913944 ElVolt 1;
BA_ "GenSigSendType" SG_ 2566913944 BogLoadPrc 1;
BA_ "GenSigSendType" SG_ 2566913944 TrlLoadPrc 1;
BA_ "VFrameFormat" BO_ 2566913936 1;
BA_ "GenSigSendType" SG_ 2566913936 VlvVolt 1;
BA_ "GenSigSendType" SG_ 2566913936 ElVolt 1;
BA_ "GenSigSendType" SG_ 2566913936 BogLoadPrc 1;
BA_ "GenSigSendType" SG_ 2566913936 TrlLoadPrc 1;
BA_ "VFrameFormat" BO_ 2566913928 1;
BA_ "GenSigSendType" SG_ 2566913928 VlvVolt 1;
BA_ "GenSigSendType" SG_ 2566913928 ElVolt 1;
BA_ "GenSigSendType" SG_ 2566913928 BogLoadPrc 1;
BA_ "GenSigSendType" SG_ 2566913928 TrlLoadPrc 1;
BA_ "VFrameFormat" BO_ 2566913920 1;
BA_ "GenSigSendType" SG_ 2566913920 VlvVolt 1;
BA_ "GenSigSendType" SG_ 2566913920 ElVolt 1;
BA_ "GenSigSendType" SG_ 2566913920 BogLoadPrc 1;
BA_ "GenSigSendType" SG_ 2566913920 TrlLoadPrc 1;
BA_ "VFrameFormat" BO_ 2499791651 1;
BA_ "GenSigSendType" SG_ 2499791651 Aux31Error 1;
BA_ "GenSigSendType" SG_ 2499791651 Aux31Input 1;
BA_ "GenSigSendType" SG_ 2499791651 Aux32Error 1;
BA_ "GenSigSendType" SG_ 2499791651 Aux32Input 1;
BA_ "GenSigSendType" SG_ 2499791651 AuxADValue 1;
BA_ "GenSigSendType" SG_ 2499791651 AuxADIndex 1;
BA_ "VFrameFormat" BO_ 2499791560 1;
BA_ "GenSigSendType" SG_ 2499791560 Aux31Act 1;
BA_ "GenSigSendType" SG_ 2499791560 Aux31CapL 1;
BA_ "GenSigSendType" SG_ 2499791560 Aux31OCDet 1;
BA_ "GenSigSendType" SG_ 2499791560 Aux31Dir 1;
BA_ "GenSigSendType" SG_ 2499791560 Aux32Act 1;
BA_ "GenSigSendType" SG_ 2499791560 Aux32CapL 1;
BA_ "GenSigSendType" SG_ 2499791560 Aux32OCDet 1;
BA_ "GenSigSendType" SG_ 2499791560 Aux32Dir 1;
BA_ "VFrameFormat" BO_ 2499791552 1;
BA_ "GenSigSendType" SG_ 2499791552 Aux31Act 1;
BA_ "GenSigSendType" SG_ 2499791552 Aux31CapL 1;
BA_ "GenSigSendType" SG_ 2499791552 Aux31OCDet 1;
BA_ "GenSigSendType" SG_ 2499791552 Aux31Dir 1;
BA_ "GenSigSendType" SG_ 2499791552 Aux32Act 1;
BA_ "GenSigSendType" SG_ 2499791552 Aux32CapL 1;
BA_ "GenSigSendType" SG_ 2499791552 Aux32OCDet 1;
BA_ "GenSigSendType" SG_ 2499791552 Aux32Dir 1;
BA_ "VFrameFormat" BO_ 2499791544 1;
BA_ "GenSigSendType" SG_ 2499791544 Aux31Act 1;
BA_ "GenSigSendType" SG_ 2499791544 Aux31CapL 1;
BA_ "GenSigSendType" SG_ 2499791544 Aux31OCDet 1;
BA_ "GenSigSendType" SG_ 2499791544 Aux31Dir 1;
BA_ "GenSigSendType" SG_ 2499791544 Aux32Act 1;
BA_ "GenSigSendType" SG_ 2499791544 Aux32CapL 1;
BA_ "GenSigSendType" SG_ 2499791544 Aux32OCDet 1;
BA_ "GenSigSendType" SG_ 2499791544 Aux32Dir 1;
BA_ "VFrameFormat" BO_ 2499791536 1;
BA_ "GenSigSendType" SG_ 2499791536 Aux31Act 1;
BA_ "GenSigSendType" SG_ 2499791536 Aux31CapL 1;
BA_ "GenSigSendType" SG_ 2499791536 Aux31OCDet 1;
BA_ "GenSigSendType" SG_ 2499791536 Aux31Dir 1;
BA_ "GenSigSendType" SG_ 2499791536 Aux32Act 1;
BA_ "GenSigSendType" SG_ 2499791536 Aux32CapL 1;
BA_ "GenSigSendType" SG_ 2499791536 Aux32OCDet 1;
BA_ "GenSigSendType" SG_ 2499791536 Aux32Dir 1;
BA_ "VFrameFormat" BO_ 2499791528 1;
BA_ "GenSigSendType" SG_ 2499791528 Aux31Act 1;
BA_ "GenSigSendType" SG_ 2499791528 Aux31CapL 1;
BA_ "GenSigSendType" SG_ 2499791528 Aux31OCDet 1;
BA_ "GenSigSendType" SG_ 2499791528 Aux31Dir 1;
BA_ "GenSigSendType" SG_ 2499791528 Aux32Act 1;
BA_ "GenSigSendType" SG_ 2499791528 Aux32CapL 1;
BA_ "GenSigSendType" SG_ 2499791528 Aux32OCDet 1;
BA_ "GenSigSendType" SG_ 2499791528 Aux32Dir 1;
BA_ "VFrameFormat" BO_ 2499791520 1;
BA_ "GenSigSendType" SG_ 2499791520 Aux31Act 1;
BA_ "GenSigSendType" SG_ 2499791520 Aux31CapL 1;
BA_ "GenSigSendType" SG_ 2499791520 Aux31OCDet 1;
BA_ "GenSigSendType" SG_ 2499791520 Aux31Dir 1;
BA_ "GenSigSendType" SG_ 2499791520 Aux32Act 1;
BA_ "GenSigSendType" SG_ 2499791520 Aux32CapL 1;
BA_ "GenSigSendType" SG_ 2499791520 Aux32OCDet 1;
BA_ "GenSigSendType" SG_ 2499791520 Aux32Dir 1;
BA_ "VFrameFormat" BO_ 2499791512 1;
BA_ "GenSigSendType" SG_ 2499791512 Aux31Act 1;
BA_ "GenSigSendType" SG_ 2499791512 Aux31CapL 1;
BA_ "GenSigSendType" SG_ 2499791512 Aux31OCDet 1;
BA_ "GenSigSendType" SG_ 2499791512 Aux31Dir 1;
BA_ "GenSigSendType" SG_ 2499791512 Aux32Act 1;
BA_ "GenSigSendType" SG_ 2499791512 Aux32CapL 1;
BA_ "GenSigSendType" SG_ 2499791512 Aux32OCDet 1;
BA_ "GenSigSendType" SG_ 2499791512 Aux32Dir 1;
BA_ "VFrameFormat" BO_ 2499791504 1;
BA_ "GenSigSendType" SG_ 2499791504 Aux31Act 1;
BA_ "GenSigSendType" SG_ 2499791504 Aux31CapL 1;
BA_ "GenSigSendType" SG_ 2499791504 Aux31OCDet 1;
BA_ "GenSigSendType" SG_ 2499791504 Aux31Dir 1;
BA_ "GenSigSendType" SG_ 2499791504 Aux32Act 1;
BA_ "GenSigSendType" SG_ 2499791504 Aux32CapL 1;
BA_ "GenSigSendType" SG_ 2499791504 Aux32OCDet 1;
BA_ "GenSigSendType" SG_ 2499791504 Aux32Dir 1;
BA_ "VFrameFormat" BO_ 2499791496 1;
BA_ "GenSigSendType" SG_ 2499791496 Aux31Act 1;
BA_ "GenSigSendType" SG_ 2499791496 Aux31CapL 1;
BA_ "GenSigSendType" SG_ 2499791496 Aux31OCDet 1;
BA_ "GenSigSendType" SG_ 2499791496 Aux31Dir 1;
BA_ "GenSigSendType" SG_ 2499791496 Aux32Act 1;
BA_ "GenSigSendType" SG_ 2499791496 Aux32CapL 1;
BA_ "GenSigSendType" SG_ 2499791496 Aux32OCDet 1;
BA_ "GenSigSendType" SG_ 2499791496 Aux32Dir 1;
BA_ "VFrameFormat" BO_ 2499791488 1;
BA_ "GenSigSendType" SG_ 2499791488 Aux31Act 1;
BA_ "GenSigSendType" SG_ 2499791488 Aux31CapL 1;
BA_ "GenSigSendType" SG_ 2499791488 Aux31OCDet 1;
BA_ "GenSigSendType" SG_ 2499791488 Aux31Dir 1;
BA_ "GenSigSendType" SG_ 2499791488 Aux32Act 1;
BA_ "GenSigSendType" SG_ 2499791488 Aux32CapL 1;
BA_ "GenSigSendType" SG_ 2499791488 Aux32OCDet 1;
BA_ "GenSigSendType" SG_ 2499791488 Aux32Dir 1;
BA_ "VFrameFormat" BO_ 2566848547 1;
BA_ "GenSigSendType" SG_ 2566848547 TH_SWITCH 1;
BA_ "GenSigSendType" SG_ 2566848547 TH_BUTTON 1;
BA_ "GenSigSendType" SG_ 2566848547 MH_SWITCH 1;
BA_ "GenSigSendType" SG_ 2566848547 MH_BUTTON 1;
BA_ "GenSigSendType" SG_ 2566848547 LL_SWITCH 1;
BA_ "GenSigSendType" SG_ 2566848547 LL1_SWITCH 1;
BA_ "GenSigSendType" SG_ 2566848547 LL2_SWITCH 1;
BA_ "GenSigSendType" SG_ 2566848547 LL_BUTTON 1;
BA_ "GenSigSendType" SG_ 2566848547 LL1_BUTTON 1;
BA_ "GenSigSendType" SG_ 2566848547 LL2_BUTTON 1;
BA_ "GenSigSendType" SG_ 2566848547 LLTH 1;
BA_ "GenSigSendType" SG_ 2566848547 FM 1;
BA_ "GenSigSendType" SG_ 2566848547 ADL_IPA 1;
BA_ "GenSigSendType" SG_ 2566848547 ADL_IPB 1;
BA_ "GenSigSendType" SG_ 2566848547 ADL_IPC 1;
BA_ "GenSigSendType" SG_ 2566848547 ADL_IPD 1;
BA_ "GenSigSendType" SG_ 2566848547 ADL_IPE 1;
BA_ "GenSigSendType" SG_ 2566848547 ADL_IPF 1;
BA_ "GenSigSendType" SG_ 2566848547 LC1_State 1;
BA_ "GenSigSendType" SG_ 2566848547 LC2_State 1;
BA_ "GenSigSendType" SG_ 2566848547 BodyLift 1;
BA_ "GenSigSendType" SG_ 2566848547 RLF 1;
BA_ "GenSigSendType" SG_ 2566848547 TRI_ADL_A_VirtualSwitch 1;
BA_ "GenSigSendType" SG_ 2566848547 TRI_ADL_B_VirtualSwitch 1;
BA_ "GenSigSendType" SG_ 2566848547 TRI_ADL_C_VirtualSwitch 1;
BA_ "GenSigSendType" SG_ 2566848547 TRI_ADL_D_VirtualSwitch 1;
BA_ "GenSigSendType" SG_ 2566848547 TRI_REVERSE_VirtualSwitch 1;
BA_ "GenSigSendType" SG_ 2566848547 LSP_SWITCH 1;
BA_ "GenSigSendType" SG_ 2566848547 LSP_BUTTON 1;
BA_ "GenSigSendType" SG_ 2566848547 TSR_BUTTON 1;
BA_ "GenSigSendType" SG_ 2566848547 TBR_BUTTON 1;
BA_ "GenSigSendType" SG_ 2566848547 TBR_IL_SW 1;
BA_ "VFrameFormat" BO_ 2566848803 1;
BA_ "GenSigSendType" SG_ 2566848803 TH_SW__TBR_BU 1;
BA_ "GenSigSendType" SG_ 2566848803 TH_BU__TBR_IL_SW 1;
BA_ "GenSigSendType" SG_ 2566848803 MH_SW__ELC_FR_UP 1;
BA_ "GenSigSendType" SG_ 2566848803 MH_BU__ELC_FR_DN 1;
BA_ "GenSigSendType" SG_ 2566848803 LL_SW__ELC_RE_UP 1;
BA_ "GenSigSendType" SG_ 2566848803 LL1_SW__ELC_RE_DN 1;
BA_ "GenSigSendType" SG_ 2566848803 LL2_SW__ELC_FR_M1 1;
BA_ "GenSigSendType" SG_ 2566848803 LL_BU__ELC_RE_M1 1;
BA_ "GenSigSendType" SG_ 2566848803 LL1_BU__ELC_FR_M2 1;
BA_ "GenSigSendType" SG_ 2566848803 LL2_BU__ELC_RE_M2 1;
BA_ "GenSigSendType" SG_ 2566848803 LLTH__ELC_FR_DL1 1;
BA_ "GenSigSendType" SG_ 2566848803 FM__ELC_RE_DL1 1;
BA_ "GenSigSendType" SG_ 2566848803 ADL_IPA__ELC_FR_DL2 1;
BA_ "GenSigSendType" SG_ 2566848803 ADL_IPB__ELC_RE_DL2 1;
BA_ "GenSigSendType" SG_ 2566848803 ADL_IPC__ELC_FR_DL3 1;
BA_ "GenSigSendType" SG_ 2566848803 ADL_IPD__ELC_RE_DL3 1;
BA_ "GenSigSendType" SG_ 2566848803 ADL_IPE__ELC_FR_TOP 1;
BA_ "GenSigSendType" SG_ 2566848803 ADL_IPF__ELC_RE_TOP 1;
BA_ "GenSigSendType" SG_ 2566848803 LC1_State__ELC_FR_BOT 1;
BA_ "GenSigSendType" SG_ 2566848803 LC2_State__ELC_RE_BOT 1;
BA_ "GenSigSendType" SG_ 2566848803 BodyLift__ELC_FR_RAMP 1;
BA_ "GenSigSendType" SG_ 2566848803 RLF__ELC_RE_RAMP 1;
BA_ "GenSigSendType" SG_ 2566848803 TRI_ADL_A 1;
BA_ "GenSigSendType" SG_ 2566848803 TRI_ADL_B 1;
BA_ "GenSigSendType" SG_ 2566848803 TRI_ADL_C 1;
BA_ "GenSigSendType" SG_ 2566848803 TRI_ADL_D 1;
BA_ "GenSigSendType" SG_ 2566848803 TRI_REVERSE 1;
BA_ "GenSigSendType" SG_ 2566848803 LSP_SW 1;
BA_ "GenSigSendType" SG_ 2566848803 LSP_BU 1;
BA_ "GenSigSendType" SG_ 2566848803 TSR_BU 1;
BA_ "GenSigSendType" SG_ 2566848803 VSE_ID 1;
BA_ "VFrameFormat" BO_ 2566901448 1;
BA_ "GenSigSendType" SG_ 2566901448 Pkg1Id 1;
BA_ "GenSigSendType" SG_ 2566901448 Pkg2Id 1;
BA_ "GenSigSendType" SG_ 2566901448 Pkg3Id 1;
BA_ "GenSigSendType" SG_ 2566901448 Select 1;
BA_ "GenSigSendType" SG_ 2566901448 Pkg1D1 1;
BA_ "GenSigSendType" SG_ 2566901448 Pkg1D2 1;
BA_ "GenSigSendType" SG_ 2566901448 Pkg2D1 1;
BA_ "GenSigSendType" SG_ 2566901448 Pkg2D2 1;
BA_ "GenSigSendType" SG_ 2566901448 Pkg3D1 1;
BA_ "GenSigSendType" SG_ 2566901448 Pkg3D2 1;
BA_ "VFrameFormat" BO_ 2566901440 1;
BA_ "GenSigSendType" SG_ 2566901440 Pkg1Id 1;
BA_ "GenSigSendType" SG_ 2566901440 Pkg2Id 1;
BA_ "GenSigSendType" SG_ 2566901440 Pkg3Id 1;
BA_ "GenSigSendType" SG_ 2566901440 Select 1;
BA_ "GenSigSendType" SG_ 2566901440 Pkg1D1 1;
BA_ "GenSigSendType" SG_ 2566901440 Pkg1D2 1;
BA_ "GenSigSendType" SG_ 2566901440 Pkg2D1 1;
BA_ "GenSigSendType" SG_ 2566901440 Pkg2D2 1;
BA_ "GenSigSendType" SG_ 2566901440 Pkg3D1 1;
BA_ "GenSigSendType" SG_ 2566901440 Pkg3D2 1;
BA_ "VFrameFormat" BO_ 2566901432 1;
BA_ "GenSigSendType" SG_ 2566901432 Pkg1Id 1;
BA_ "GenSigSendType" SG_ 2566901432 Pkg2Id 1;
BA_ "GenSigSendType" SG_ 2566901432 Pkg3Id 1;
BA_ "GenSigSendType" SG_ 2566901432 Select 1;
BA_ "GenSigSendType" SG_ 2566901432 Pkg1D1 1;
BA_ "GenSigSendType" SG_ 2566901432 Pkg1D2 1;
BA_ "GenSigSendType" SG_ 2566901432 Pkg2D1 1;
BA_ "GenSigSendType" SG_ 2566901432 Pkg2D2 1;
BA_ "GenSigSendType" SG_ 2566901432 Pkg3D1 1;
BA_ "GenSigSendType" SG_ 2566901432 Pkg3D2 1;
BA_ "VFrameFormat" BO_ 2566901424 1;
BA_ "GenSigSendType" SG_ 2566901424 Pkg1Id 1;
BA_ "GenSigSendType" SG_ 2566901424 Pkg2Id 1;
BA_ "GenSigSendType" SG_ 2566901424 Pkg3Id 1;
BA_ "GenSigSendType" SG_ 2566901424 Select 1;
BA_ "GenSigSendType" SG_ 2566901424 Pkg1D1 1;
BA_ "GenSigSendType" SG_ 2566901424 Pkg1D2 1;
BA_ "GenSigSendType" SG_ 2566901424 Pkg2D1 1;
BA_ "GenSigSendType" SG_ 2566901424 Pkg2D2 1;
BA_ "GenSigSendType" SG_ 2566901424 Pkg3D1 1;
BA_ "GenSigSendType" SG_ 2566901424 Pkg3D2 1;
BA_ "VFrameFormat" BO_ 2566901416 1;
BA_ "GenSigSendType" SG_ 2566901416 Pkg1Id 1;
BA_ "GenSigSendType" SG_ 2566901416 Pkg2Id 1;
BA_ "GenSigSendType" SG_ 2566901416 Pkg3Id 1;
BA_ "GenSigSendType" SG_ 2566901416 Select 1;
BA_ "GenSigSendType" SG_ 2566901416 Pkg1D1 1;
BA_ "GenSigSendType" SG_ 2566901416 Pkg1D2 1;
BA_ "GenSigSendType" SG_ 2566901416 Pkg2D1 1;
BA_ "GenSigSendType" SG_ 2566901416 Pkg2D2 1;
BA_ "GenSigSendType" SG_ 2566901416 Pkg3D1 1;
BA_ "GenSigSendType" SG_ 2566901416 Pkg3D2 1;
BA_ "VFrameFormat" BO_ 2566901408 1;
BA_ "GenSigSendType" SG_ 2566901408 Pkg1Id 1;
BA_ "GenSigSendType" SG_ 2566901408 Pkg2Id 1;
BA_ "GenSigSendType" SG_ 2566901408 Pkg3Id 1;
BA_ "GenSigSendType" SG_ 2566901408 Select 1;
BA_ "GenSigSendType" SG_ 2566901408 Pkg1D1 1;
BA_ "GenSigSendType" SG_ 2566901408 Pkg1D2 1;
BA_ "GenSigSendType" SG_ 2566901408 Pkg2D1 1;
BA_ "GenSigSendType" SG_ 2566901408 Pkg2D2 1;
BA_ "GenSigSendType" SG_ 2566901408 Pkg3D1 1;
BA_ "GenSigSendType" SG_ 2566901408 Pkg3D2 1;
BA_ "VFrameFormat" BO_ 2566901400 1;
BA_ "GenSigSendType" SG_ 2566901400 Pkg1Id 1;
BA_ "GenSigSendType" SG_ 2566901400 Pkg2Id 1;
BA_ "GenSigSendType" SG_ 2566901400 Pkg3Id 1;
BA_ "GenSigSendType" SG_ 2566901400 Select 1;
BA_ "GenSigSendType" SG_ 2566901400 Pkg1D1 1;
BA_ "GenSigSendType" SG_ 2566901400 Pkg1D2 1;
BA_ "GenSigSendType" SG_ 2566901400 Pkg2D1 1;
BA_ "GenSigSendType" SG_ 2566901400 Pkg2D2 1;
BA_ "GenSigSendType" SG_ 2566901400 Pkg3D1 1;
BA_ "GenSigSendType" SG_ 2566901400 Pkg3D2 1;
BA_ "VFrameFormat" BO_ 2566901392 1;
BA_ "GenSigSendType" SG_ 2566901392 Pkg1Id 1;
BA_ "GenSigSendType" SG_ 2566901392 Pkg2Id 1;
BA_ "GenSigSendType" SG_ 2566901392 Pkg3Id 1;
BA_ "GenSigSendType" SG_ 2566901392 Select 1;
BA_ "GenSigSendType" SG_ 2566901392 Pkg1D1 1;
BA_ "GenSigSendType" SG_ 2566901392 Pkg1D2 1;
BA_ "GenSigSendType" SG_ 2566901392 Pkg2D1 1;
BA_ "GenSigSendType" SG_ 2566901392 Pkg2D2 1;
BA_ "GenSigSendType" SG_ 2566901392 Pkg3D1 1;
BA_ "GenSigSendType" SG_ 2566901392 Pkg3D2 1;
BA_ "VFrameFormat" BO_ 2566901384 1;
BA_ "GenSigSendType" SG_ 2566901384 Pkg1Id 1;
BA_ "GenSigSendType" SG_ 2566901384 Pkg2Id 1;
BA_ "GenSigSendType" SG_ 2566901384 Pkg3Id 1;
BA_ "GenSigSendType" SG_ 2566901384 Select 1;
BA_ "GenSigSendType" SG_ 2566901384 Pkg1D1 1;
BA_ "GenSigSendType" SG_ 2566901384 Pkg1D2 1;
BA_ "GenSigSendType" SG_ 2566901384 Pkg2D1 1;
BA_ "GenSigSendType" SG_ 2566901384 Pkg2D2 1;
BA_ "GenSigSendType" SG_ 2566901384 Pkg3D1 1;
BA_ "GenSigSendType" SG_ 2566901384 Pkg3D2 1;
BA_ "VFrameFormat" BO_ 2566901376 1;
BA_ "GenSigSendType" SG_ 2566901376 Pkg1Id 1;
BA_ "GenSigSendType" SG_ 2566901376 Pkg2Id 1;
BA_ "GenSigSendType" SG_ 2566901376 Pkg3Id 1;
BA_ "GenSigSendType" SG_ 2566901376 Select 1;
BA_ "GenSigSendType" SG_ 2566901376 Pkg1D1 1;
BA_ "GenSigSendType" SG_ 2566901376 Pkg1D2 1;
BA_ "GenSigSendType" SG_ 2566901376 Pkg2D1 1;
BA_ "GenSigSendType" SG_ 2566901376 Pkg2D2 1;
BA_ "GenSigSendType" SG_ 2566901376 Pkg3D1 1;
BA_ "GenSigSendType" SG_ 2566901376 Pkg3D2 1;
BA_ "VFrameFormat" BO_ 2566876823 1;
BA_ "GenSigSendType" SG_ 2566876823 TyrePrSuf_CBP1_Rx 1;
BA_ "GenSigSendType" SG_ 2566876823 BrLinSuf_CBP1_Rx 1;
BA_ "GenSigSendType" SG_ 2566876823 BrTempSt_CBP1_Rx 1;
BA_ "GenSigSendType" SG_ 2566876823 PneuSupSuf_CBP1_Rx 1;
BA_ "GenSigSendType" SG_ 2566876823 TyreId_Press_CBP1_Rx 1;
BA_ "GenSigSendType" SG_ 2566876823 TyreId_Lining_CBP1_Rx 1;
BA_ "GenSigSendType" SG_ 2566876823 TyreId_Temp_CBP1_Rx 1;
BA_ "GenSigSendType" SG_ 2566876823 TyrePress_CBP1_Rx 1;
BA_ "GenSigSendType" SG_ 2566876823 BrLin_CBP1_Rx 1;
BA_ "GenSigSendType" SG_ 2566876823 BrTemp_CBP1_Rx 1;
BA_ "GenSigSendType" SG_ 2566876823 PneuSupPr_CBP1_Rx 1;
BA_ "VFrameFormat" BO_ 2565144471 1;
BA_ "GenSigSendType" SG_ 2565144471 RideHeiReq 1;
BA_ "GenSigSendType" SG_ 2565144471 LevChgReq_FA 1;
BA_ "GenSigSendType" SG_ 2565144471 LevChgReq_RA 1;
BA_ "GenSigSendType" SG_ 2565144471 TracHelpReq 1;
BA_ "GenSigSendType" SG_ 2565144471 LiftAxPos1Req 1;
BA_ "GenSigSendType" SG_ 2565144471 LiftAxPos2Req 1;
BA_ "GenSigSendType" SG_ 2565144471 StrAxLockReq 1;
BA_ "GenSigSendType" SG_ 2565144471 RampLevReq 1;
BA_ "GenSigSendType" SG_ 2565144471 LevCtrReq 1;
BA_ "GenSigSendType" SG_ 2565144471 RampLevStReq 1;
BA_ "GenSigSendType" SG_ 2565144471 StopLevChReq 1;
BA_ "GenSigSendType" SG_ 2565144471 DrvAxLoad 1;
BA_ "GenSigSendType" SG_ 2565144471 ParkAirPress 1;
BA_ "GenSigSendType" SG_ 2565144471 AuxSupPress 1;
BA_ "VFrameFormat" BO_ 2566900787 1;
BA_ "GenSigSendType" SG_ 2566900787 TrPos1 1;
BA_ "GenSigSendType" SG_ 2566900787 TrPress1 1;
BA_ "GenSigSendType" SG_ 2566900787 TrTemp1 1;
BA_ "GenSigSendType" SG_ 2566900787 TrPDev1 1;
BA_ "GenSigSendType" SG_ 2566900787 TrFltMap1 1;
BA_ "VFrameFormat" BO_ 2566901043 1;
BA_ "GenSigSendType" SG_ 2566901043 TrPos2 1;
BA_ "GenSigSendType" SG_ 2566901043 TrPress2 1;
BA_ "GenSigSendType" SG_ 2566901043 TrTemp2 1;
BA_ "GenSigSendType" SG_ 2566901043 TrPDev2 1;
BA_ "GenSigSendType" SG_ 2566901043 TrFltMap2 1;
BA_ "VFrameFormat" BO_ 2566849331 1;
BA_ "GenSigSendType" SG_ 2566849331 TrLoc1 1;
BA_ "GenSigSendType" SG_ 2566849331 TrSensLowBatt 1;
BA_ "GenSigSendType" SG_ 2566849331 TrSensIntErr 1;
BA_ "GenSigSendType" SG_ 2566849331 TrSensFault 1;
BA_ "GenSigSendType" SG_ 2566849331 TrAlrtHiLvl1 1;
BA_ "GenSigSendType" SG_ 2566849331 TrAlrtLoLvl1 1;
BA_ "GenSigSendType" SG_ 2566849331 TrAlrtLvl2 1;
BA_ "GenSigSendType" SG_ 2566849331 TrAlrtHiTemp 1;
BA_ "GenSigSendType" SG_ 2566849331 TrPressure 1;
BA_ "GenSigSendType" SG_ 2566849331 TrTemperature 1;
BA_ "GenSigSendType" SG_ 2566849331 TrDeviation 1;
BA_ "GenSigSendType" SG_ 2566849331 TrSensDataAgeMins 1;
BA_ "VFrameFormat" BO_ 2566845491 1;
BA_ "GenSigSendType" SG_ 2566845491 TrData0 1;
BA_ "GenSigSendType" SG_ 2566845491 TrData1 1;
BA_ "GenSigSendType" SG_ 2566845491 TrData2 1;
BA_ "GenSigSendType" SG_ 2566845491 TrData3 1;
BA_ "GenSigSendType" SG_ 2566845491 TrData4 1;
BA_ "GenSigSendType" SG_ 2566845491 TrData5 1;
BA_ "GenSigSendType" SG_ 2566845491 TrData6 1;
BA_ "GenSigSendType" SG_ 2566845491 TrData7 1;
BA_ "VFrameFormat" BO_ 385 0;
BA_ "GenSigSendType" SG_ 385 CANopenPr 1;
BA_ "VFrameFormat" BO_ 129 0;
BA_ "GenSigSendType" SG_ 129 CANopenErr 1;
BA_ "VFrameFormat" BO_ 2499780643 1;
BA_ "GenSigSendType" SG_ 2499780643 P0_CapMask 1;
BA_ "GenSigSendType" SG_ 2499780643 P1_CapMask 1;
BA_ "GenSigSendType" SG_ 2499780643 P2_CapMask 1;
BA_ "GenSigSendType" SG_ 2499780643 P3_CapMask 1;
BA_ "GenSigSendType" SG_ 2499780643 P4_CapMask 1;
BA_ "GenSigSendType" SG_ 2499780643 P5_CapMask 1;
BA_ "GenSigSendType" SG_ 2499780643 P6_CapMask 1;
BA_ "GenSigSendType" SG_ 2499780643 iCapSet 1;
BA_ "GenSigSendType" SG_ 2499780643 MaxCapSet 1;
BA_ "VFrameFormat" BO_ 2499780899 1;
BA_ "GenSigSendType" SG_ 2499780899 PkgXStat 1;
BA_ "GenSigSendType" SG_ 2499780899 PkgXData 1;
BA_ "GenSigSendType" SG_ 2499780899 PkgXStat2 1;
BA_ "GenSigSendType" SG_ 2499780899 PkgXData2 1;
BA_ "GenSigSendType" SG_ 2499780899 PkgYStat 1;
BA_ "GenSigSendType" SG_ 2499780899 PkgYData 1;
BA_ "GenSigSendType" SG_ 2499780899 PkgYStat2 1;
BA_ "GenSigSendType" SG_ 2499780899 PkgYData2 1;
BA_ "GenSigSendType" SG_ 2499780899 PkgZStat 1;
BA_ "GenSigSendType" SG_ 2499780899 PkgZData 1;
BA_ "GenSigSendType" SG_ 2499780899 PkgZStat2 1;
BA_ "GenSigSendType" SG_ 2499780899 PkgZData2 1;
BA_ "GenSigSendType" SG_ 2499780899 PkgXId 1;
BA_ "GenSigSendType" SG_ 2499780899 PkgYId 1;
BA_ "GenSigSendType" SG_ 2499780899 PkgZId 1;
BA_ "GenSigSendType" SG_ 2499780899 Reserved 1;
BA_ "VFrameFormat" BO_ 2499781320 1;
BA_ "GenSigSendType" SG_ 2499781320 P0_IOin 1;
BA_ "GenSigSendType" SG_ 2499781320 P0_Mode 1;
BA_ "GenSigSendType" SG_ 2499781320 P0_Ath_PWM 1;
BA_ "GenSigSendType" SG_ 2499781320 P0_Ath_Cap 1;
BA_ "GenSigSendType" SG_ 2499781320 P0_Ngnd_OC 1;
BA_ "GenSigSendType" SG_ 2499781320 P0_Nsup_Stim 1;
BA_ "GenSigSendType" SG_ 2499781320 P1_IOin 1;
BA_ "GenSigSendType" SG_ 2499781320 P1_Mode 1;
BA_ "GenSigSendType" SG_ 2499781320 P1_Ath_PWM 1;
BA_ "GenSigSendType" SG_ 2499781320 P1_Ath_Cap 1;
BA_ "GenSigSendType" SG_ 2499781320 P1_Ngnd_OC 1;
BA_ "GenSigSendType" SG_ 2499781320 P1_Nsup_Stim 1;
BA_ "GenSigSendType" SG_ 2499781320 P2_IOin 1;
BA_ "GenSigSendType" SG_ 2499781320 P2_Mode 1;
BA_ "GenSigSendType" SG_ 2499781320 P2_Ath_PWM 1;
BA_ "GenSigSendType" SG_ 2499781320 P2_Ath_Cap 1;
BA_ "GenSigSendType" SG_ 2499781320 P2_Ngnd_OC 1;
BA_ "GenSigSendType" SG_ 2499781320 P2_Nsup_Stim 1;
BA_ "GenSigSendType" SG_ 2499781320 P3_IOin 1;
BA_ "GenSigSendType" SG_ 2499781320 P3_Mode 1;
BA_ "GenSigSendType" SG_ 2499781320 P3_Ath_PWM 1;
BA_ "GenSigSendType" SG_ 2499781320 P3_Ath_Cap 1;
BA_ "GenSigSendType" SG_ 2499781320 P3_Ngnd_OC 1;
BA_ "GenSigSendType" SG_ 2499781320 P3_Nsup_Stim 1;
BA_ "GenSigSendType" SG_ 2499781320 P4_IOin 1;
BA_ "GenSigSendType" SG_ 2499781320 P4_Mode 1;
BA_ "GenSigSendType" SG_ 2499781320 P4_Ath_PWM 1;
BA_ "GenSigSendType" SG_ 2499781320 P4_Ath_Cap 1;
BA_ "GenSigSendType" SG_ 2499781320 P4_Ngnd_OC 1;
BA_ "GenSigSendType" SG_ 2499781320 P4_Nsup_Stim 1;
BA_ "GenSigSendType" SG_ 2499781320 P5_IOin 1;
BA_ "GenSigSendType" SG_ 2499781320 P5_Mode 1;
BA_ "GenSigSendType" SG_ 2499781320 P5_Ath_PWM 1;
BA_ "GenSigSendType" SG_ 2499781320 P5_Ath_Cap 1;
BA_ "GenSigSendType" SG_ 2499781320 P5_Ngnd_OC 1;
BA_ "GenSigSendType" SG_ 2499781320 P5_Nsup_Stim 1;
BA_ "GenSigSendType" SG_ 2499781320 P6_IOin 1;
BA_ "GenSigSendType" SG_ 2499781320 P6_Mode 1;
BA_ "GenSigSendType" SG_ 2499781320 P6_Ath_PWM 1;
BA_ "GenSigSendType" SG_ 2499781320 P6_Ath_Cap 1;
BA_ "GenSigSendType" SG_ 2499781320 P6_Ngnd_OC 1;
BA_ "GenSigSendType" SG_ 2499781320 P6_Nsup_Stim 1;
BA_ "GenSigSendType" SG_ 2499781320 iConfSet 1;
BA_ "GenSigSendType" SG_ 2499781320 MaxConfSet 1;
BA_ "VFrameFormat" BO_ 2499781576 1;
BA_ "GenSigSendType" SG_ 2499781576 P0_Act 1;
BA_ "GenSigSendType" SG_ 2499781576 P1_Act 1;
BA_ "GenSigSendType" SG_ 2499781576 P2_Act 1;
BA_ "GenSigSendType" SG_ 2499781576 P3_Act 1;
BA_ "GenSigSendType" SG_ 2499781576 P4_Act 1;
BA_ "GenSigSendType" SG_ 2499781576 P5_Act 1;
BA_ "GenSigSendType" SG_ 2499781576 P6_Act 1;
BA_ "GenSigSendType" SG_ 2499781576 P7_Act 1;
BA_ "GenSigSendType" SG_ 2499781576 P8_Act 1;
BA_ "GenSigSendType" SG_ 2499781576 P9_Act 1;
BA_ "GenSigSendType" SG_ 2499781576 PA_Act 1;
BA_ "GenSigSendType" SG_ 2499781576 PB_Act 1;
BA_ "GenSigSendType" SG_ 2499781576 PC_Act 1;
BA_ "GenSigSendType" SG_ 2499781576 PD_Act 1;
BA_ "GenSigSendType" SG_ 2499781576 iCmdSet 1;
BA_ "GenSigSendType" SG_ 2499781576 MaxCmdSet 1;
BA_ "VFrameFormat" BO_ 2499781667 1;
BA_ "GenSigSendType" SG_ 2499781667 CRC_E2E 1;
BA_ "GenSigSendType" SG_ 2499781667 Counter_E2E 1;
BA_ "GenSigSendType" SG_ 2499781667 MaxCapSet 1;
BA_ "GenSigSendType" SG_ 2499781667 P0_CapMask 1;
BA_ "GenSigSendType" SG_ 2499781667 P1_CapMask 1;
BA_ "GenSigSendType" SG_ 2499781667 P2_CapMask 1;
BA_ "GenSigSendType" SG_ 2499781667 P3_CapMask 1;
BA_ "GenSigSendType" SG_ 2499781667 P4_CapMask 1;
BA_ "GenSigSendType" SG_ 2499781667 iCapSet 1;
BA_ "VFrameFormat" BO_ 2499781923 1;
BA_ "GenSigSendType" SG_ 2499781923 CRC_E2E 1;
BA_ "GenSigSendType" SG_ 2499781923 Counter_E2E 1;
BA_ "GenSigSendType" SG_ 2499781923 PkgXStat 1;
BA_ "GenSigSendType" SG_ 2499781923 PkgXData 1;
BA_ "GenSigSendType" SG_ 2499781923 PkgXStat2 1;
BA_ "GenSigSendType" SG_ 2499781923 PkgXData2 1;
BA_ "GenSigSendType" SG_ 2499781923 PkgYStat 1;
BA_ "GenSigSendType" SG_ 2499781923 PkgYData 1;
BA_ "GenSigSendType" SG_ 2499781923 PkgYStat2 1;
BA_ "GenSigSendType" SG_ 2499781923 PkgYData2 1;
BA_ "GenSigSendType" SG_ 2499781923 PkgXId 1;
BA_ "GenSigSendType" SG_ 2499781923 PkgYId 1;
BA_ "VFrameFormat" BO_ 2499782344 1;
BA_ "GenSigSendType" SG_ 2499782344 CRC_E2E_ADP_Config_iTEPM_Tx 1;
BA_ "GenSigSendType" SG_ 2499782344 Counter_E2E_ADP_Config_iTEPM_Tx 1;
BA_ "GenSigSendType" SG_ 2499782344 MaxConfSet 1;
BA_ "GenSigSendType" SG_ 2499782344 P0_IOin 1;
BA_ "GenSigSendType" SG_ 2499782344 P0_Mode 1;
BA_ "GenSigSendType" SG_ 2499782344 P0_Ath_PWM 1;
BA_ "GenSigSendType" SG_ 2499782344 P0_Ath_Cap 1;
BA_ "GenSigSendType" SG_ 2499782344 P0_Ngnd_OC 1;
BA_ "GenSigSendType" SG_ 2499782344 P0_Nsup_Stim 1;
BA_ "GenSigSendType" SG_ 2499782344 P1_IOin 1;
BA_ "GenSigSendType" SG_ 2499782344 P1_Mode 1;
BA_ "GenSigSendType" SG_ 2499782344 P1_Ath_PWM 1;
BA_ "GenSigSendType" SG_ 2499782344 P1_Ath_Cap 1;
BA_ "GenSigSendType" SG_ 2499782344 P1_Ngnd_OC 1;
BA_ "GenSigSendType" SG_ 2499782344 P1_Nsup_Stim 1;
BA_ "GenSigSendType" SG_ 2499782344 P2_IOin 1;
BA_ "GenSigSendType" SG_ 2499782344 P2_Mode 1;
BA_ "GenSigSendType" SG_ 2499782344 P2_Ath_PWM 1;
BA_ "GenSigSendType" SG_ 2499782344 P2_Ath_Cap 1;
BA_ "GenSigSendType" SG_ 2499782344 P2_Ngnd_OC 1;
BA_ "GenSigSendType" SG_ 2499782344 P2_Nsup_Stim 1;
BA_ "GenSigSendType" SG_ 2499782344 P3_IOin 1;
BA_ "GenSigSendType" SG_ 2499782344 P3_Mode 1;
BA_ "GenSigSendType" SG_ 2499782344 P3_Ath_PWM 1;
BA_ "GenSigSendType" SG_ 2499782344 P3_Ath_Cap 1;
BA_ "GenSigSendType" SG_ 2499782344 P3_Ngnd_OC 1;
BA_ "GenSigSendType" SG_ 2499782344 P3_Nsup_Stim 1;
BA_ "GenSigSendType" SG_ 2499782344 P4_IOin 1;
BA_ "GenSigSendType" SG_ 2499782344 P4_Mode 1;
BA_ "GenSigSendType" SG_ 2499782344 P4_Ath_PWM 1;
BA_ "GenSigSendType" SG_ 2499782344 P4_Ath_Cap 1;
BA_ "GenSigSendType" SG_ 2499782344 P4_Ngnd_OC 1;
BA_ "GenSigSendType" SG_ 2499782344 P4_Nsup_Stim 1;
BA_ "GenSigSendType" SG_ 2499782344 iConfSet 1;
BA_ "VFrameFormat" BO_ 2499782600 1;
BA_ "GenSigSendType" SG_ 2499782600 CRC_E2E_ADP_Command_iTEPM_Tx 1;
BA_ "GenSigSendType" SG_ 2499782600 Counter_E2E_ADP_Command_iTEPM_Tx 1;
BA_ "GenSigSendType" SG_ 2499782600 MaxCmdSet 1;
BA_ "GenSigSendType" SG_ 2499782600 P0_Act 1;
BA_ "GenSigSendType" SG_ 2499782600 P1_Act 1;
BA_ "GenSigSendType" SG_ 2499782600 P2_Act 1;
BA_ "GenSigSendType" SG_ 2499782600 P3_Act 1;
BA_ "GenSigSendType" SG_ 2499782600 P4_Act 1;
BA_ "GenSigSendType" SG_ 2499782600 P5_Act 1;
BA_ "GenSigSendType" SG_ 2499782600 P6_Act 1;
BA_ "GenSigSendType" SG_ 2499782600 P7_Act 1;
BA_ "GenSigSendType" SG_ 2499782600 P8_Act 1;
BA_ "GenSigSendType" SG_ 2499782600 P9_Act 1;
BA_ "GenSigSendType" SG_ 2499782600 PA_Act 1;
BA_ "GenSigSendType" SG_ 2499782600 iCmdSet 1;
BA_ "VFrameFormat" BO_ 2560726795 1;
BA_ "GenSigSendType" SG_ 2560726795 EncrDataTEBS 1;
BA_ "VFrameFormat" BO_ 2560691095 1;
BA_ "GenSigSendType" SG_ 2560691095 EncrDataCTU 1;

SIG_GROUP_ 2499780643 AUTO_SG_ADP_Capability_Rx 1 : P0_CapMask P1_CapMask P2_CapMask P3_CapMask P4_CapMask P5_CapMask P6_CapMask iCapSet MaxCapSet;
SIG_GROUP_ 2499781667 AUTO_SG_ADP_Capability_iTEPM_Rx 1 : CRC_E2E Counter_E2E MaxCapSet P0_CapMask P1_CapMask P2_CapMask P3_CapMask P4_CapMask iCapSet;
SIG_GROUP_ 2499781576 AUTO_SG_ADP_Command_Tx 1 : P0_Act P1_Act P2_Act P3_Act P4_Act P5_Act P6_Act P7_Act P8_Act P9_Act PA_Act PB_Act PC_Act PD_Act iCmdSet MaxCmdSet;
SIG_GROUP_ 2499782600 AUTO_SG_ADP_Command_iTEPM_Tx 1 : CRC_E2E_ADP_Command_iTEPM_Tx Counter_E2E_ADP_Command_iTEPM_Tx MaxCmdSet P0_Act P1_Act P2_Act P3_Act P4_Act P5_Act P6_Act P7_Act P8_Act P9_Act PA_Act iCmdSet;
SIG_GROUP_ 2499781320 AUTO_SG_ADP_Config_Tx 1 : P0_IOin P0_Mode P0_Ath_PWM P0_Ath_Cap P0_Ngnd_OC P0_Nsup_Stim P1_IOin P1_Mode P1_Ath_PWM P1_Ath_Cap P1_Ngnd_OC P1_Nsup_Stim P2_IOin P2_Mode P2_Ath_PWM P2_Ath_Cap P2_Ngnd_OC P2_Nsup_Stim P3_IOin P3_Mode P3_Ath_PWM P3_Ath_Cap P3_Ngnd_OC P3_Nsup_Stim P4_IOin P4_Mode P4_Ath_PWM P4_Ath_Cap P4_Ngnd_OC P4_Nsup_Stim P5_IOin P5_Mode P5_Ath_PWM P5_Ath_Cap P5_Ngnd_OC P5_Nsup_Stim P6_IOin P6_Mode P6_Ath_PWM P6_Ath_Cap P6_Ngnd_OC P6_Nsup_Stim iConfSet MaxConfSet;
SIG_GROUP_ 2499782344 AUTO_SG_ADP_Config_iTEPM_Tx 1 : CRC_E2E_ADP_Config_iTEPM_Tx Counter_E2E_ADP_Config_iTEPM_Tx MaxConfSet P0_IOin P0_Mode P0_Ath_PWM P0_Ath_Cap P0_Ngnd_OC P0_Nsup_Stim P1_IOin P1_Mode P1_Ath_PWM P1_Ath_Cap P1_Ngnd_OC P1_Nsup_Stim P2_IOin P2_Mode P2_Ath_PWM P2_Ath_Cap P2_Ngnd_OC P2_Nsup_Stim P3_IOin P3_Mode P3_Ath_PWM P3_Ath_Cap P3_Ngnd_OC P3_Nsup_Stim P4_IOin P4_Mode P4_Ath_PWM P4_Ath_Cap P4_Ngnd_OC P4_Nsup_Stim iConfSet;
SIG_GROUP_ 2499780899 AUTO_SG_ADP_Status_Rx 1 : PkgXStat PkgXData PkgXStat2 PkgXData2 PkgYStat PkgYData PkgYStat2 PkgYData2 PkgZStat PkgZData PkgZStat2 PkgZData2 PkgXId PkgYId PkgZId Reserved;
SIG_GROUP_ 2499781923 AUTO_SG_ADP_Status_iTEPM_Rx 1 : CRC_E2E Counter_E2E PkgXStat PkgXData PkgXStat2 PkgXData2 PkgYStat PkgYData PkgYStat2 PkgYData2 PkgXId PkgYId;
SIG_GROUP_ 2566805888 AUTO_SG_ASC3_Tx_10 1 : VehicleLevelFrontLeft VehicleLevelFrontRight VehicleLevelRearLeft VehicleLevelRearRight;
SIG_GROUP_ 2566805936 AUTO_SG_ASC3_Tx_4 1 : VehicleLevelFrontLeft VehicleLevelFrontRight VehicleLevelRearLeft VehicleLevelRearRight;
SIG_GROUP_ 2566805928 AUTO_SG_ASC3_Tx_5 1 : VehicleLevelFrontLeft VehicleLevelFrontRight VehicleLevelRearLeft VehicleLevelRearRight;
SIG_GROUP_ 2566805920 AUTO_SG_ASC3_Tx_6 1 : VehicleLevelFrontLeft VehicleLevelFrontRight VehicleLevelRearLeft VehicleLevelRearRight;
SIG_GROUP_ 2173691288 AUTO_SG_ASC3_Tx_7 1 : VehicleLevelFrontLeft VehicleLevelFrontRight VehicleLevelRearLeft VehicleLevelRearRight;
SIG_GROUP_ 2566805904 AUTO_SG_ASC3_Tx_8 1 : VehicleLevelFrontLeft VehicleLevelFrontRight VehicleLevelRearLeft VehicleLevelRearRight;
SIG_GROUP_ 2566805896 AUTO_SG_ASC3_Tx_9 1 : VehicleLevelFrontLeft VehicleLevelFrontRight VehicleLevelRearLeft VehicleLevelRearRight;
SIG_GROUP_ 2566876823 AUTO_SG_CBP1_Rx 1 : TyrePrSuf_CBP1_Rx BrLinSuf_CBP1_Rx BrTempSt_CBP1_Rx PneuSupSuf_CBP1_Rx TyreId_Press_CBP1_Rx TyreId_Lining_CBP1_Rx TyreId_Temp_CBP1_Rx TyrePress_CBP1_Rx BrLin_CBP1_Rx BrTemp_CBP1_Rx PneuSupPr_CBP1_Rx;
SIG_GROUP_ 2565144471 AUTO_SG_CBP2_Rx 1 : RideHeiReq LevChgReq_FA LevChgReq_RA TracHelpReq LiftAxPos1Req LiftAxPos2Req StrAxLockReq RampLevReq LevCtrReq RampLevStReq StopLevChReq DrvAxLoad ParkAirPress AuxSupPress;
SIG_GROUP_ 2560691095 AUTO_SG_EncryptedDataCTU 1 : EncrDataCTU;
SIG_GROUP_ 2560726795 AUTO_SG_EncryptedDataTEBS 1 : EncrDataTEBS;
SIG_GROUP_ 2566813896 AUTO_SG_PGN65144_Tx 1 : Tire_Press_Sw_Sta;
SIG_GROUP_ 2566813824 AUTO_SG_PGN65144_Tx_10 1 : Tire_Press_Sw_Sta;
SIG_GROUP_ 2566813888 AUTO_SG_PGN65144_Tx_2 1 : Tire_Press_Sw_Sta;
SIG_GROUP_ 2566813880 AUTO_SG_PGN65144_Tx_3 1 : Tire_Press_Sw_Sta;
SIG_GROUP_ 2566813872 AUTO_SG_PGN65144_Tx_4 1 : Tire_Press_Sw_Sta;
SIG_GROUP_ 2566813864 AUTO_SG_PGN65144_Tx_5 1 : Tire_Press_Sw_Sta;
SIG_GROUP_ 2566813856 AUTO_SG_PGN65144_Tx_6 1 : Tire_Press_Sw_Sta;
SIG_GROUP_ 2566813848 AUTO_SG_PGN65144_Tx_7 1 : Tire_Press_Sw_Sta;
SIG_GROUP_ 2566813840 AUTO_SG_PGN65144_Tx_8 1 : Tire_Press_Sw_Sta;
SIG_GROUP_ 2566813832 AUTO_SG_PGN65144_Tx_9 1 : Tire_Press_Sw_Sta;
SIG_GROUP_ 2566844872 AUTO_SG_PGN65265_Tx 1 : ParkBrakeSwitch;
SIG_GROUP_ 2566844800 AUTO_SG_PGN65265_Tx_10 1 : ParkBrakeSwitch;
SIG_GROUP_ 2566844864 AUTO_SG_PGN65265_Tx_2 1 : ParkBrakeSwitch;
SIG_GROUP_ 2566844856 AUTO_SG_PGN65265_Tx_3 1 : ParkBrakeSwitch;
SIG_GROUP_ 2566844848 AUTO_SG_PGN65265_Tx_4 1 : ParkBrakeSwitch;
SIG_GROUP_ 2566844840 AUTO_SG_PGN65265_Tx_5 1 : ParkBrakeSwitch;
SIG_GROUP_ 2566844832 AUTO_SG_PGN65265_Tx_6 1 : ParkBrakeSwitch;
SIG_GROUP_ 2566844824 AUTO_SG_PGN65265_Tx_7 1 : ParkBrakeSwitch;
SIG_GROUP_ 2566844816 AUTO_SG_PGN65265_Tx_8 1 : ParkBrakeSwitch;
SIG_GROUP_ 2566844808 AUTO_SG_PGN65265_Tx_9 1 : ParkBrakeSwitch;
SIG_GROUP_ 2566845491 AUTO_SG_PGN65268_TPMS_Rx 1 : TrData0 TrData1 TrData2 TrData3 TrData4 TrData5 TrData6 TrData7;
SIG_GROUP_ 2566848712 AUTO_SG_PGN65280_Tx 1 : Overload TracHelp P1_Sys P4_Dem EBS_Press AvgBrPressMain AvgBrPressSteer LoadPress;
SIG_GROUP_ 2566848640 AUTO_SG_PGN65280_Tx_10 1 : Overload TracHelp P1_Sys P4_Dem EBS_Press AvgBrPressMain AvgBrPressSteer LoadPress;
SIG_GROUP_ 2566848704 AUTO_SG_PGN65280_Tx_2 1 : Overload TracHelp P1_Sys P4_Dem EBS_Press AvgBrPressMain AvgBrPressSteer LoadPress;
SIG_GROUP_ 2566848696 AUTO_SG_PGN65280_Tx_3 1 : Overload TracHelp P1_Sys P4_Dem EBS_Press AvgBrPressMain AvgBrPressSteer LoadPress;
SIG_GROUP_ 2566848688 AUTO_SG_PGN65280_Tx_4 1 : Overload TracHelp P1_Sys P4_Dem EBS_Press AvgBrPressMain AvgBrPressSteer LoadPress;
SIG_GROUP_ 2566848680 AUTO_SG_PGN65280_Tx_5 1 : Overload TracHelp P1_Sys P4_Dem EBS_Press AvgBrPressMain AvgBrPressSteer LoadPress;
SIG_GROUP_ 2566848672 AUTO_SG_PGN65280_Tx_6 1 : Overload TracHelp P1_Sys P4_Dem EBS_Press AvgBrPressMain AvgBrPressSteer LoadPress;
SIG_GROUP_ 2566848664 AUTO_SG_PGN65280_Tx_7 1 : Overload TracHelp P1_Sys P4_Dem EBS_Press AvgBrPressMain AvgBrPressSteer LoadPress;
SIG_GROUP_ 2566848656 AUTO_SG_PGN65280_Tx_8 1 : Overload TracHelp P1_Sys P4_Dem EBS_Press AvgBrPressMain AvgBrPressSteer LoadPress;
SIG_GROUP_ 2566848648 AUTO_SG_PGN65280_Tx_9 1 : Overload TracHelp P1_Sys P4_Dem EBS_Press AvgBrPressMain AvgBrPressSteer LoadPress;
SIG_GROUP_ 2566849224 AUTO_SG_PGN65282_Tx 1 : StBkpPSup StISO7638PSup YellowPress PCANDem P21 P22 P2P23;
SIG_GROUP_ 2566849152 AUTO_SG_PGN65282_Tx_10 1 : StBkpPSup StISO7638PSup YellowPress PCANDem P21 P22 P2P23;
SIG_GROUP_ 2566849216 AUTO_SG_PGN65282_Tx_2 1 : StBkpPSup StISO7638PSup YellowPress PCANDem P21 P22 P2P23;
SIG_GROUP_ 2566849208 AUTO_SG_PGN65282_Tx_3 1 : StBkpPSup StISO7638PSup YellowPress PCANDem P21 P22 P2P23;
SIG_GROUP_ 2566849200 AUTO_SG_PGN65282_Tx_4 1 : StBkpPSup StISO7638PSup YellowPress PCANDem P21 P22 P2P23;
SIG_GROUP_ 2566849192 AUTO_SG_PGN65282_Tx_5 1 : StBkpPSup StISO7638PSup YellowPress PCANDem P21 P22 P2P23;
SIG_GROUP_ 2566849184 AUTO_SG_PGN65282_Tx_6 1 : StBkpPSup StISO7638PSup YellowPress PCANDem P21 P22 P2P23;
SIG_GROUP_ 2566849176 AUTO_SG_PGN65282_Tx_7 1 : StBkpPSup StISO7638PSup YellowPress PCANDem P21 P22 P2P23;
SIG_GROUP_ 2566849168 AUTO_SG_PGN65282_Tx_8 1 : StBkpPSup StISO7638PSup YellowPress PCANDem P21 P22 P2P23;
SIG_GROUP_ 2566849160 AUTO_SG_PGN65282_Tx_9 1 : StBkpPSup StISO7638PSup YellowPress PCANDem P21 P22 P2P23;
SIG_GROUP_ 2566849331 AUTO_SG_PGN65283_TPMS_Rx 1 : TrLoc1 TrSensLowBatt TrSensIntErr TrSensFault TrAlrtHiLvl1 TrAlrtLoLvl1 TrAlrtLvl2 TrAlrtHiTemp TrPressure TrTemperature TrDeviation TrSensDataAgeMins;
SIG_GROUP_ 2566849480 AUTO_SG_PGN65283_Tx 1 : TrlInfInd TrlInfDat Odometer ConDevPermTr;
SIG_GROUP_ 2566849408 AUTO_SG_PGN65283_Tx_10 1 : TrlInfInd TrlInfDat Odometer ConDevPermTr;
SIG_GROUP_ 2566849472 AUTO_SG_PGN65283_Tx_2 1 : TrlInfInd TrlInfDat Odometer ConDevPermTr;
SIG_GROUP_ 2566849464 AUTO_SG_PGN65283_Tx_3 1 : TrlInfInd TrlInfDat Odometer ConDevPermTr;
SIG_GROUP_ 2566849456 AUTO_SG_PGN65283_Tx_4 1 : TrlInfInd TrlInfDat Odometer ConDevPermTr;
SIG_GROUP_ 2566849448 AUTO_SG_PGN65283_Tx_5 1 : TrlInfInd TrlInfDat Odometer ConDevPermTr;
SIG_GROUP_ 2566849440 AUTO_SG_PGN65283_Tx_6 1 : TrlInfInd TrlInfDat Odometer ConDevPermTr;
SIG_GROUP_ 2566849432 AUTO_SG_PGN65283_Tx_7 1 : TrlInfInd TrlInfDat Odometer ConDevPermTr;
SIG_GROUP_ 2566849424 AUTO_SG_PGN65283_Tx_8 1 : TrlInfInd TrlInfDat Odometer ConDevPermTr;
SIG_GROUP_ 2566849416 AUTO_SG_PGN65283_Tx_9 1 : TrlInfInd TrlInfDat Odometer ConDevPermTr;
SIG_GROUP_ 2566851272 AUTO_SG_PGN65290_Tx 1 : BLI_active BLI_ovrd BLS_status TG_status TG_Cont_status Cover_status URP_status RLF_status TrHelp_status OWS_status TIS_status iLvl_aut_low Tilt_Angle BL_Angle Art_Angle OWS_Weight;
SIG_GROUP_ 2566851200 AUTO_SG_PGN65290_Tx_10 1 : BLI_active BLI_ovrd BLS_status TG_status TG_Cont_status Cover_status URP_status RLF_status TrHelp_status OWS_status TIS_status iLvl_aut_low Tilt_Angle BL_Angle Art_Angle OWS_Weight;
SIG_GROUP_ 2566851264 AUTO_SG_PGN65290_Tx_2 1 : BLI_active BLI_ovrd BLS_status TG_status TG_Cont_status Cover_status URP_status RLF_status TrHelp_status OWS_status TIS_status iLvl_aut_low Tilt_Angle BL_Angle Art_Angle OWS_Weight;
SIG_GROUP_ 2566851256 AUTO_SG_PGN65290_Tx_3 1 : BLI_active BLI_ovrd BLS_status TG_status TG_Cont_status Cover_status URP_status RLF_status TrHelp_status OWS_status TIS_status iLvl_aut_low Tilt_Angle BL_Angle Art_Angle OWS_Weight;
SIG_GROUP_ 2566851248 AUTO_SG_PGN65290_Tx_4 1 : BLI_active BLI_ovrd BLS_status TG_status TG_Cont_status Cover_status URP_status RLF_status TrHelp_status OWS_status TIS_status iLvl_aut_low Tilt_Angle BL_Angle Art_Angle OWS_Weight;
SIG_GROUP_ 2566851240 AUTO_SG_PGN65290_Tx_5 1 : BLI_active BLI_ovrd BLS_status TG_status TG_Cont_status Cover_status URP_status RLF_status TrHelp_status OWS_status TIS_status iLvl_aut_low Tilt_Angle BL_Angle Art_Angle OWS_Weight;
SIG_GROUP_ 2566851232 AUTO_SG_PGN65290_Tx_6 1 : BLI_active BLI_ovrd BLS_status TG_status TG_Cont_status Cover_status URP_status RLF_status TrHelp_status OWS_status TIS_status iLvl_aut_low Tilt_Angle BL_Angle Art_Angle OWS_Weight;
SIG_GROUP_ 2566851224 AUTO_SG_PGN65290_Tx_7 1 : BLI_active BLI_ovrd BLS_status TG_status TG_Cont_status Cover_status URP_status RLF_status TrHelp_status OWS_status TIS_status iLvl_aut_low Tilt_Angle BL_Angle Art_Angle OWS_Weight;
SIG_GROUP_ 2566851216 AUTO_SG_PGN65290_Tx_8 1 : BLI_active BLI_ovrd BLS_status TG_status TG_Cont_status Cover_status URP_status RLF_status TrHelp_status OWS_status TIS_status iLvl_aut_low Tilt_Angle BL_Angle Art_Angle OWS_Weight;
SIG_GROUP_ 2566851208 AUTO_SG_PGN65290_Tx_9 1 : BLI_active BLI_ovrd BLS_status TG_status TG_Cont_status Cover_status URP_status RLF_status TrHelp_status OWS_status TIS_status iLvl_aut_low Tilt_Angle BL_Angle Art_Angle OWS_Weight;
SIG_GROUP_ 2566851528 AUTO_SG_PGN65291_Tx 1 : WF_press WF_temp RearProximSta SideProximSta Immob_State Immob_Safe_State Immob_Fault_State Immob_LockMoving_Sta Immob_LockPressure_Sta;
SIG_GROUP_ 2566851456 AUTO_SG_PGN65291_Tx_10 1 : WF_press WF_temp RearProximSta SideProximSta Immob_State Immob_Safe_State Immob_Fault_State Immob_LockMoving_Sta Immob_LockPressure_Sta;
SIG_GROUP_ 2566851520 AUTO_SG_PGN65291_Tx_2 1 : WF_press WF_temp RearProximSta SideProximSta Immob_State Immob_Safe_State Immob_Fault_State Immob_LockMoving_Sta Immob_LockPressure_Sta;
SIG_GROUP_ 2566851512 AUTO_SG_PGN65291_Tx_3 1 : WF_press WF_temp RearProximSta SideProximSta Immob_State Immob_Safe_State Immob_Fault_State Immob_LockMoving_Sta Immob_LockPressure_Sta;
SIG_GROUP_ 2566851504 AUTO_SG_PGN65291_Tx_4 1 : WF_press WF_temp RearProximSta SideProximSta Immob_State Immob_Safe_State Immob_Fault_State Immob_LockMoving_Sta Immob_LockPressure_Sta;
SIG_GROUP_ 2566851496 AUTO_SG_PGN65291_Tx_5 1 : WF_press WF_temp RearProximSta SideProximSta Immob_State Immob_Safe_State Immob_Fault_State Immob_LockMoving_Sta Immob_LockPressure_Sta;
SIG_GROUP_ 2566851488 AUTO_SG_PGN65291_Tx_6 1 : WF_press WF_temp RearProximSta SideProximSta Immob_State Immob_Safe_State Immob_Fault_State Immob_LockMoving_Sta Immob_LockPressure_Sta;
SIG_GROUP_ 2566851480 AUTO_SG_PGN65291_Tx_7 1 : WF_press WF_temp RearProximSta SideProximSta Immob_State Immob_Safe_State Immob_Fault_State Immob_LockMoving_Sta Immob_LockPressure_Sta;
SIG_GROUP_ 2566851472 AUTO_SG_PGN65291_Tx_8 1 : WF_press WF_temp RearProximSta SideProximSta Immob_State Immob_Safe_State Immob_Fault_State Immob_LockMoving_Sta Immob_LockPressure_Sta;
SIG_GROUP_ 2566851464 AUTO_SG_PGN65291_Tx_9 1 : WF_press WF_temp RearProximSta SideProximSta Immob_State Immob_Safe_State Immob_Fault_State Immob_LockMoving_Sta Immob_LockPressure_Sta;
SIG_GROUP_ 2566913480 AUTO_SG_PGN65533_Tx 1 : ServiceDist;
SIG_GROUP_ 2566913408 AUTO_SG_PGN65533_Tx_10 1 : ServiceDist;
SIG_GROUP_ 2566913472 AUTO_SG_PGN65533_Tx_2 1 : ServiceDist;
SIG_GROUP_ 2566913464 AUTO_SG_PGN65533_Tx_3 1 : ServiceDist;
SIG_GROUP_ 2566913456 AUTO_SG_PGN65533_Tx_4 1 : ServiceDist;
SIG_GROUP_ 2566913448 AUTO_SG_PGN65533_Tx_5 1 : ServiceDist;
SIG_GROUP_ 2566913440 AUTO_SG_PGN65533_Tx_6 1 : ServiceDist;
SIG_GROUP_ 2566913432 AUTO_SG_PGN65533_Tx_7 1 : ServiceDist;
SIG_GROUP_ 2566913424 AUTO_SG_PGN65533_Tx_8 1 : ServiceDist;
SIG_GROUP_ 2566913416 AUTO_SG_PGN65533_Tx_9 1 : ServiceDist;
SIG_GROUP_ 2566913736 AUTO_SG_PGN65534_Tx 1 : Data;
SIG_GROUP_ 2566913664 AUTO_SG_PGN65534_Tx_10 1 : Data;
SIG_GROUP_ 2566913728 AUTO_SG_PGN65534_Tx_2 1 : Data;
SIG_GROUP_ 2566913720 AUTO_SG_PGN65534_Tx_3 1 : Data;
SIG_GROUP_ 2566913712 AUTO_SG_PGN65534_Tx_4 1 : Data;
SIG_GROUP_ 2566913704 AUTO_SG_PGN65534_Tx_5 1 : Data;
SIG_GROUP_ 2566913696 AUTO_SG_PGN65534_Tx_6 1 : Data;
SIG_GROUP_ 2566913688 AUTO_SG_PGN65534_Tx_7 1 : Data;
SIG_GROUP_ 2566913680 AUTO_SG_PGN65534_Tx_8 1 : Data;
SIG_GROUP_ 2566913672 AUTO_SG_PGN65534_Tx_9 1 : Data;
SIG_GROUP_ 2566913992 AUTO_SG_PGN65535_Tx 1 : VlvVolt ElVolt BogLoadPrc TrlLoadPrc;
SIG_GROUP_ 2566913920 AUTO_SG_PGN65535_Tx_10 1 : VlvVolt ElVolt BogLoadPrc TrlLoadPrc;
SIG_GROUP_ 2566913984 AUTO_SG_PGN65535_Tx_2 1 : VlvVolt ElVolt BogLoadPrc TrlLoadPrc;
SIG_GROUP_ 2566913976 AUTO_SG_PGN65535_Tx_3 1 : VlvVolt ElVolt BogLoadPrc TrlLoadPrc;
SIG_GROUP_ 2566913968 AUTO_SG_PGN65535_Tx_4 1 : VlvVolt ElVolt BogLoadPrc TrlLoadPrc;
SIG_GROUP_ 2566913960 AUTO_SG_PGN65535_Tx_5 1 : VlvVolt ElVolt BogLoadPrc TrlLoadPrc;
SIG_GROUP_ 2566913952 AUTO_SG_PGN65535_Tx_6 1 : VlvVolt ElVolt BogLoadPrc TrlLoadPrc;
SIG_GROUP_ 2566913944 AUTO_SG_PGN65535_Tx_7 1 : VlvVolt ElVolt BogLoadPrc TrlLoadPrc;
SIG_GROUP_ 2566913936 AUTO_SG_PGN65535_Tx_8 1 : VlvVolt ElVolt BogLoadPrc TrlLoadPrc;
SIG_GROUP_ 2566913928 AUTO_SG_PGN65535_Tx_9 1 : VlvVolt ElVolt BogLoadPrc TrlLoadPrc;
SIG_GROUP_ 129 AUTO_SG_Sens1CANopen_Err_Rx 1 : CANopenErr;
SIG_GROUP_ 385 AUTO_SG_Sens1CANopen_Rx 1 : CANopenPr;
SIG_GROUP_ 2499791651 AUTO_SG_TIM_IO_Rx 1 : Aux31Error Aux31Input Aux32Error Aux32Input AuxADValue AuxADIndex;
SIG_GROUP_ 2499791560 AUTO_SG_TIM_IO_Tx 1 : Aux31Act Aux31CapL Aux31OCDet Aux31Dir Aux32Act Aux32CapL Aux32OCDet Aux32Dir;
SIG_GROUP_ 2499791488 AUTO_SG_TIM_IO_Tx_10 1 : Aux31Act Aux31CapL Aux31OCDet Aux31Dir Aux32Act Aux32CapL Aux32OCDet Aux32Dir;
SIG_GROUP_ 2499791552 AUTO_SG_TIM_IO_Tx_2 1 : Aux31Act Aux31CapL Aux31OCDet Aux31Dir Aux32Act Aux32CapL Aux32OCDet Aux32Dir;
SIG_GROUP_ 2499791544 AUTO_SG_TIM_IO_Tx_3 1 : Aux31Act Aux31CapL Aux31OCDet Aux31Dir Aux32Act Aux32CapL Aux32OCDet Aux32Dir;
SIG_GROUP_ 2499791536 AUTO_SG_TIM_IO_Tx_4 1 : Aux31Act Aux31CapL Aux31OCDet Aux31Dir Aux32Act Aux32CapL Aux32OCDet Aux32Dir;
SIG_GROUP_ 2499791528 AUTO_SG_TIM_IO_Tx_5 1 : Aux31Act Aux31CapL Aux31OCDet Aux31Dir Aux32Act Aux32CapL Aux32OCDet Aux32Dir;
SIG_GROUP_ 2499791520 AUTO_SG_TIM_IO_Tx_6 1 : Aux31Act Aux31CapL Aux31OCDet Aux31Dir Aux32Act Aux32CapL Aux32OCDet Aux32Dir;
SIG_GROUP_ 2499791512 AUTO_SG_TIM_IO_Tx_7 1 : Aux31Act Aux31CapL Aux31OCDet Aux31Dir Aux32Act Aux32CapL Aux32OCDet Aux32Dir;
SIG_GROUP_ 2499791504 AUTO_SG_TIM_IO_Tx_8 1 : Aux31Act Aux31CapL Aux31OCDet Aux31Dir Aux32Act Aux32CapL Aux32OCDet Aux32Dir;
SIG_GROUP_ 2499791496 AUTO_SG_TIM_IO_Tx_9 1 : Aux31Act Aux31CapL Aux31OCDet Aux31Dir Aux32Act Aux32CapL Aux32OCDet Aux32Dir;
SIG_GROUP_ 2566900787 AUTO_SG_TPMS1_Rx 1 : TrPos1 TrPress1 TrTemp1 TrPDev1 TrFltMap1;
SIG_GROUP_ 2566901043 AUTO_SG_TPMS2_Rx 1 : TrPos2 TrPress2 TrTemp2 TrPDev2 TrFltMap2;
SIG_GROUP_ 2566901448 AUTO_SG_VirtualIndicator 1 : Pkg1Id Pkg2Id Pkg3Id Select Pkg1D1 Pkg1D2 Pkg2D1 Pkg2D2 Pkg3D1 Pkg3D2;
SIG_GROUP_ 2566901376 AUTO_SG_VirtualIndicator_10 1 : Pkg1Id Pkg2Id Pkg3Id Select Pkg1D1 Pkg1D2 Pkg2D1 Pkg2D2 Pkg3D1 Pkg3D2;
SIG_GROUP_ 2566901440 AUTO_SG_VirtualIndicator_2 1 : Pkg1Id Pkg2Id Pkg3Id Select Pkg1D1 Pkg1D2 Pkg2D1 Pkg2D2 Pkg3D1 Pkg3D2;
SIG_GROUP_ 2566901432 AUTO_SG_VirtualIndicator_3 1 : Pkg1Id Pkg2Id Pkg3Id Select Pkg1D1 Pkg1D2 Pkg2D1 Pkg2D2 Pkg3D1 Pkg3D2;
SIG_GROUP_ 2566901424 AUTO_SG_VirtualIndicator_4 1 : Pkg1Id Pkg2Id Pkg3Id Select Pkg1D1 Pkg1D2 Pkg2D1 Pkg2D2 Pkg3D1 Pkg3D2;
SIG_GROUP_ 2566901416 AUTO_SG_VirtualIndicator_5 1 : Pkg1Id Pkg2Id Pkg3Id Select Pkg1D1 Pkg1D2 Pkg2D1 Pkg2D2 Pkg3D1 Pkg3D2;
SIG_GROUP_ 2566901408 AUTO_SG_VirtualIndicator_6 1 : Pkg1Id Pkg2Id Pkg3Id Select Pkg1D1 Pkg1D2 Pkg2D1 Pkg2D2 Pkg3D1 Pkg3D2;
SIG_GROUP_ 2566901400 AUTO_SG_VirtualIndicator_7 1 : Pkg1Id Pkg2Id Pkg3Id Select Pkg1D1 Pkg1D2 Pkg2D1 Pkg2D2 Pkg3D1 Pkg3D2;
SIG_GROUP_ 2566901392 AUTO_SG_VirtualIndicator_8 1 : Pkg1Id Pkg2Id Pkg3Id Select Pkg1D1 Pkg1D2 Pkg2D1 Pkg2D2 Pkg3D1 Pkg3D2;
SIG_GROUP_ 2566901384 AUTO_SG_VirtualIndicator_9 1 : Pkg1Id Pkg2Id Pkg3Id Select Pkg1D1 Pkg1D2 Pkg2D1 Pkg2D2 Pkg3D1 Pkg3D2;
SIG_GROUP_ 2566848547 AUTO_SG_VirtualSwitch 1 : TH_SWITCH TH_BUTTON MH_SWITCH MH_BUTTON LL_SWITCH LL1_SWITCH LL2_SWITCH LL_BUTTON LL1_BUTTON LL2_BUTTON LLTH FM ADL_IPA ADL_IPB ADL_IPC ADL_IPD ADL_IPE ADL_IPF LC1_State LC2_State BodyLift RLF TRI_ADL_A_VirtualSwitch TRI_ADL_B_VirtualSwitch TRI_ADL_C_VirtualSwitch TRI_ADL_D_VirtualSwitch TRI_REVERSE_VirtualSwitch LSP_SWITCH LSP_BUTTON TSR_BUTTON TBR_BUTTON TBR_IL_SW;
SIG_GROUP_ 2566848803 AUTO_SG_VirtualSwitchExt 1 : TH_SW__TBR_BU TH_BU__TBR_IL_SW MH_SW__ELC_FR_UP MH_BU__ELC_FR_DN LL_SW__ELC_RE_UP LL1_SW__ELC_RE_DN LL2_SW__ELC_FR_M1 LL_BU__ELC_RE_M1 LL1_BU__ELC_FR_M2 LL2_BU__ELC_RE_M2 LLTH__ELC_FR_DL1 FM__ELC_RE_DL1 ADL_IPA__ELC_FR_DL2 ADL_IPB__ELC_RE_DL2 ADL_IPC__ELC_FR_DL3 ADL_IPD__ELC_RE_DL3 ADL_IPE__ELC_FR_TOP ADL_IPF__ELC_RE_TOP LC1_State__ELC_FR_BOT LC2_State__ELC_RE_BOT BodyLift__ELC_FR_RAMP RLF__ELC_RE_RAMP TRI_ADL_A TRI_ADL_B TRI_ADL_C TRI_ADL_D TRI_REVERSE LSP_SW LSP_BU TSR_BU VSE_ID;
